VERSION "2021.24.4"

NS_ :

BS_:

BU_: VEH CH Receiver X

BA_DEF_ BO_ "GenMsgSendType" ENUM "Cyclic";
BA_DEF_ BO_ "GenMsgCycleTime" INT 0 10000;

BA_ "GenMsgSendType" BO_ 1879 0;
BA_ "GenMsgCycleTime" BO_ 1879 100;

BA_ "GenMsgSendType" BO_ 1680 0;
BA_ "GenMsgCycleTime" BO_ 1680 100;

BO_ 1666 HVP_hvpFaults: 8 Vector__XXX
 SG_ HVP_hvpFaultsChecksum : 56|8@1+ (1,0) [0|0] "" Vector__XXX
 SG_ HVP_hvpFaultsCounter : 52|4@1+ (1,0) [0|0] "" Vector__XXX
 SG_ HVP_shuntOverTemperature : 51|1@1+ (1,0) [0|0] "" Vector__XXX
 SG_ HVP_bmbBmbDataIntegrityLossFault : 49|1@1+ (1,0) [0|0] "" Vector__XXX
 SG_ HVP_bmbCommunicationFault : 48|1@1+ (1,0) [0|0] "" Vector__XXX
 SG_ HVP_configMinorVersion : 40|8@1+ (1,0) [0|0] "" Vector__XXX
 SG_ HVP_configMajorVersion : 32|8@1+ (1,0) [0|0] "" Vector__XXX
 SG_ HVP_hvilStatus : 30|2@1+ (1,0) [0|0] "" Vector__XXX
 SG_ HVP_hvilFault : 26|1@1+ (1,0) [0|0] "" Vector__XXX
 SG_ HVP_unsupportedBmbAsicType : 25|1@1+ (1,0) [0|0] "" Vector__XXX
 SG_ HVP_missingPartNumber : 24|1@1+ (1,0) [0|0] "" Vector__XXX
 SG_ HVP_missingConfigBlock : 23|1@1+ (1,0) [0|0] "" Vector__XXX
 SG_ HVP_fastVshFailureFault : 22|1@1+ (1,0) [0|0] "" Vector__XXX
 SG_ HVP_gpoRequestActive : 21|1@1+ (1,0) [0|0] "" Vector__XXX
 SG_ HVP_battery12vDisconnected : 20|1@1+ (1,0) [0|0] "" Vector__XXX
 SG_ HVP_packNegativeCtrArcFault : 19|1@1+ (1,0) [0|0] "" Vector__XXX
 SG_ HVP_packPositiveCtrArcFault : 18|1@1+ (1,0) [0|0] "" Vector__XXX
 SG_ HVP_ensMiaFault : 17|1@1+ (1,0) [0|0] "" Vector__XXX
 SG_ HVP_crashEvent : 16|1@1+ (1,0) [0|0] "" Vector__XXX
 SG_ HVP_packVoltageMismatchFault : 15|1@1+ (1,0) [0|0] "" Vector__XXX
 SG_ HVP_supply12vFault : 14|1@1+ (1,0) [0|0] "" Vector__XXX
 SG_ HVP_fcContactorHwFault : 13|1@1+ (1,0) [0|0] "" Vector__XXX
 SG_ HVP_packContactorHwFault : 12|1@1+ (1,0) [0|0] "" Vector__XXX
 SG_ HVP_pyroMiaWarning : 11|1@1+ (1,0) [0|0] "" Vector__XXX
 SG_ HVP_pyroMiaFault : 10|1@1+ (1,0) [0|0] "" Vector__XXX
 SG_ HVP_shuntHwAndBmsMiaFault : 9|1@1+ (1,0) [0|0] "" Vector__XXX
 SG_ HVP_shuntHwMiaFault : 8|1@1+ (1,0) [0|0] "" Vector__XXX
 SG_ HVP_cpFault : 7|1@1+ (1,0) [0|0] "" Vector__XXX
 SG_ HVP_pcsMiaFault : 6|1@1+ (1,0) [0|0] "" Vector__XXX
 SG_ HVP_cpMiaFault : 5|1@1+ (1,0) [0|0] "" Vector__XXX
 SG_ HVP_bmsMiaFault : 4|1@1+ (1,0) [0|0] "" Vector__XXX
 SG_ HVP_primaryBmbMiaFault : 3|1@1+ (1,0) [0|0] "" Vector__XXX
 SG_ HVP_underVoltageFault : 2|1@1+ (1,0) [0|0] "" Vector__XXX
 SG_ HVP_overVoltageFault : 1|1@1+ (1,0) [0|0] "" Vector__XXX
 SG_ HVP_overTemperatureFault : 0|1@1+ (1,0) [0|0] "" Vector__XXX

BO_ 1668 UDS_gtwRequest: 12 Vector__XXX
 SG_ UDS_gtwRequestData : 7|64@0+ (1,0) [0|0] "" Vector__XXX

BO_ 1669 GTW_udsResponse: 12 Vector__XXX
 SG_ GTW_udsResponseData : 7|64@0+ (1,0) [0|0] "" Vector__XXX

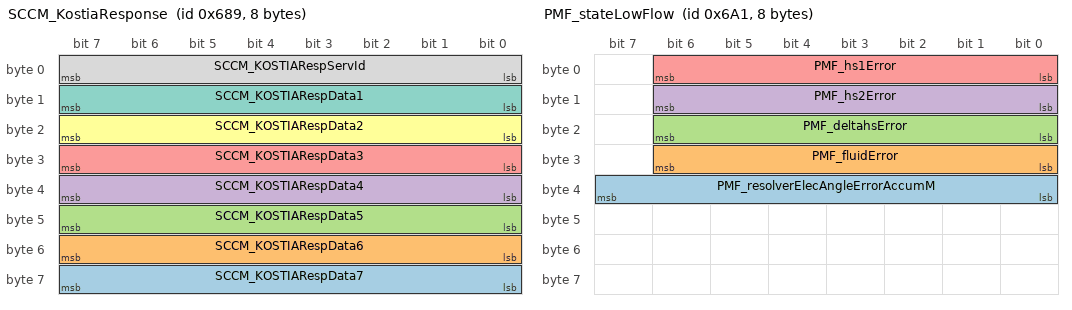
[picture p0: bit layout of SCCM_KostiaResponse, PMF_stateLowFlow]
BO_ 1673 SCCM_KostiaResponse: 8 Vector__XXX
 SG_ SCCM_KOSTIARespData7 : 56|8@1+ (1,0) [0|0] "" Vector__XXX
 SG_ SCCM_KOSTIARespData6 : 48|8@1+ (1,0) [0|0] "" Vector__XXX
 SG_ SCCM_KOSTIARespData5 : 40|8@1+ (1,0) [0|0] "" Vector__XXX
 SG_ SCCM_KOSTIARespData4 : 32|8@1+ (1,0) [0|0] "" Vector__XXX
 SG_ SCCM_KOSTIARespData3 : 24|8@1+ (1,0) [0|0] "" Vector__XXX
 SG_ SCCM_KOSTIARespData2 : 16|8@1+ (1,0) [0|0] "" Vector__XXX
 SG_ SCCM_KOSTIARespData1 : 8|8@1+ (1,0) [0|0] "" Vector__XXX
 SG_ SCCM_KOSTIARespServId : 0|8@1+ (1,0) [0|0] "" Vector__XXX

BO_ 1680 SCCM_udsResponse: 12 Vector__XXX
 SG_ SCCM_functionalResponseData_7 : 63|8@0+ (1,0) [0|0] "" Vector__XXX
 SG_ SCCM_functionalResponseData_6 : 55|8@0+ (1,0) [0|0] "" Vector__XXX
 SG_ SCCM_functionalResponseData_5 : 47|8@0+ (1,0) [0|0] "" Vector__XXX
 SG_ SCCM_functionalResponseData_4 : 39|8@0+ (1,0) [0|0] "" Vector__XXX
 SG_ SCCM_functionalResponseData_3 : 31|8@0+ (1,0) [0|0] "" Vector__XXX
 SG_ SCCM_functionalResponseData_2 : 23|8@0+ (1,0) [0|0] "" Vector__XXX
 SG_ SCCM_functionalResponseData_1 : 15|8@0+ (1,0) [0|0] "" Vector__XXX
 SG_ SCCM_functionalResponseData_0 : 7|8@0+ (1,0) [0|0] "" Vector__XXX

BO_ 1697 PMF_stateLowFlow: 8 Vector__XXX
 SG_ PMF_resolverElecAngleErrorAccumM : 32|8@1+ (0.00196078431372549,0) [0|0] "" Vector__XXX
 SG_ PMF_fluidError : 24|7@1+ (0.01,0) [0|0] "" Vector__XXX
 SG_ PMF_deltahsError : 16|7@1+ (0.01,0) [0|0] "" Vector__XXX
 SG_ PMF_hs2Error : 8|7@1+ (0.01,0) [0|0] "" Vector__XXX
 SG_ PMF_hs1Error : 0|7@1+ (0.01,0) [0|0] "" Vector__XXX

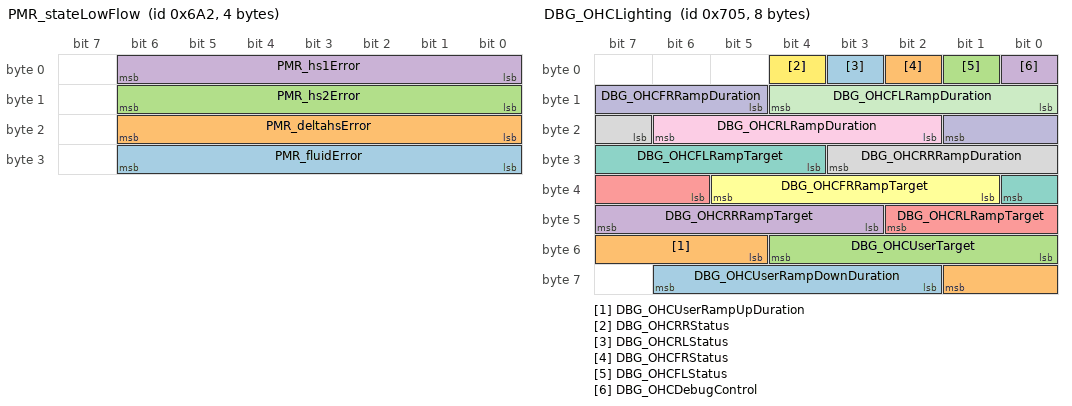
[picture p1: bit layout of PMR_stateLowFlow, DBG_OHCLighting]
BO_ 1698 PMR_stateLowFlow: 4 Vector__XXX
 SG_ PMR_fluidError : 24|7@1+ (0.01,0) [0|0] "" Vector__XXX
 SG_ PMR_deltahsError : 16|7@1+ (0.01,0) [0|0] "" Vector__XXX
 SG_ PMR_hs2Error : 8|7@1+ (0.01,0) [0|0] "" Vector__XXX
 SG_ PMR_hs1Error : 0|7@1+ (0.01,0) [0|0] "" Vector__XXX

BO_ 1723 UDS_sdcrRequest: 8 Vector__XXX
 SG_ UDS_sdcrRequestData : 7|64@0+ (1,0) [0|0] "" Vector__XXX

BO_ 1734 UDS_ptcRequest: 12 Vector__XXX
 SG_ UDS_ptcRequestData : 7|64@0+ (1,0) [0|0] "" Vector__XXX

BO_ 1736 EPBL_statsOutput: 8 Vector__XXX
 SG_ EPBL_staticApplyCountsVeryCold m0 : 44|20@1+ (1,0) [0|0] "" Vector__XXX
 SG_ EPBL_staticApplyCountsCold m0 : 24|20@1+ (1,0) [0|0] "" Vector__XXX
 SG_ EPBL_dynamicApplyCounts m1 : 8|32@1+ (1,0) [0|0] "" Vector__XXX
 SG_ EPBL_staticApplyCounts m0 : 2|20@1+ (1,0) [0|0] "" Vector__XXX
 SG_ EPBL_statsOutputIndex M : 0|2@1+ (1,0) [0|0] "" Vector__XXX

BO_ 1750 PTC_udsResponse: 12 Vector__XXX
 SG_ PTC_udsResponseData : 7|64@0+ (1,0) [0|0] "" Vector__XXX

BO_ 1766 PNCD_IsoTpPipeToCp: 8 Vector__XXX
 SG_ PNCD_isoTpToCpData : 0|64@1+ (1,0) [0|0] "" Vector__XXX

BO_ 1767 CP_IsoTpPipeToPncd: 8 Vector__XXX
 SG_ CP_isoTpToPncdData : 0|64@1+ (1,0) [0|0] "" Vector__XXX

BO_ 1768 EPBR_statsOutput: 8 Vector__XXX
 SG_ EPBR_staticApplyCountsVeryCold m0 : 44|20@1+ (1,0) [0|0] "" Vector__XXX
 SG_ EPBR_staticApplyCountsCold m0 : 24|20@1+ (1,0) [0|0] "" Vector__XXX
 SG_ EPBR_dynamicApplyCounts m1 : 8|32@1+ (1,0) [0|0] "" Vector__XXX
 SG_ EPBR_staticApplyCounts m0 : 2|20@1+ (1,0) [0|0] "" Vector__XXX
 SG_ EPBR_statsOutputIndex M : 0|2@1+ (1,0) [0|0] "" Vector__XXX

BO_ 1776 UNK_6F0_alive: 2 Vector__XXX
 SG_ UNK_6F0_crc : 0|8@1+ (1,0) [0|255] "" Vector__XXX
 SG_ UNK_6F0_counter : 8|4@1+ (1,0) [0|15] "" Vector__XXX

BO_ 1779 UNK_6F3_alive: 3 Vector__XXX
 SG_ UNK_6F3_crc : 0|8@1+ (1,0) [0|255] "" Vector__XXX
 SG_ UNK_6F3_counter : 8|4@1+ (1,0) [0|15] "" Vector__XXX

BO_ 1787 SDCR_udsResponse: 12 Vector__XXX
 SG_ SDCR_udsResponseData : 7|64@0+ (1,0) [0|0] "" Vector__XXX

BO_ 1793 VCFRONT_debugThermal10Hz: 8 Vector__XXX
 SG_ VCFRONT_ccRightExvCount m6 : 54|10@1- (4,0) [0|0] "" Vector__XXX
 SG_ VCFRONT_ccLeftExvCount m6 : 44|10@1- (4,0) [0|0] "" Vector__XXX
 SG_ VCFRONT_activeLouverAutoDetCur3 m3 : 40|7@1+ (5,0) [0|0] "" Vector__XXX
 SG_ VCFRONT_coolantNoFlowFaultPT m2 : 40|1@1+ (1,0) [0|0] "" Vector__XXX
 SG_ VCFRONT_coolantNoFlowReqPT m2 : 39|1@1+ (1,0) [0|0] "" Vector__XXX
 SG_ VCFRONT_lccExvCount m6 : 34|10@1- (4,0) [0|0] "" Vector__XXX
 SG_ VCFRONT_activeLouverAutoDetCur2 m3 : 32|7@1+ (5,0) [0|0] "" Vector__XXX
 SG_ VCFRONT_activeLouverMotorCurrent m5 : 32|10@1- (5,0) [0|0] "" Vector__XXX
 SG_ VCFRONT_coolantFlowPTMax m2 : 30|9@1+ (0.1,0) [0|0] "" Vector__XXX
 SG_ VCFRONT_coolantNoFlowFaultBat m2 : 29|1@1+ (1,0) [0|0] "" Vector__XXX
 SG_ VCFRONT_coolantNoFlowReqBat m2 : 28|1@1+ (1,0) [0|0] "" Vector__XXX
 SG_ VCFRONT_activeLouverAutoDetCur1 m3 : 25|7@1+ (5,0) [0|0] "" Vector__XXX
 SG_ VCFRONT_pumpBatteryFault m0 : 24|1@1+ (1,0) [0|0] "" Vector__XXX
 SG_ VCFRONT_pumpPowertrainFault m1 : 24|1@1+ (1,0) [0|0] "" Vector__XXX
 SG_ VCFRONT_radiatorFanFault m3 : 24|1@1+ (1,0) [0|0] "" Vector__XXX
 SG_ VCFRONT_recircExvCount m6 : 24|10@1- (4,0) [0|0] "" Vector__XXX
 SG_ VCFRONT_solenoidEvapPowerApplied m4 : 20|1@1+ (1,0) [0|0] "" Vector__XXX
 SG_ VCFRONT_coolantFlowBatMax m2 : 19|9@1+ (0.1,0) [0|0] "" Vector__XXX
 SG_ VCFRONT_exvMotorHasCommError m4 : 19|1@1+ (1,0) [0|0] "" Vector__XXX
 SG_ VCFRONT_coolantValveStall m2 : 18|1@1+ (1,0) [0|0] "" Vector__XXX
 SG_ VCFRONT_exvMotorIsCoilShortYNVbb m4 : 18|1@1+ (1,0) [0|0] "" Vector__XXX
 SG_ VCFRONT_coolantValveNoTravel m2 : 17|1@1+ (1,0) [0|0] "" Vector__XXX
 SG_ VCFRONT_exvMotorIsCoilShortYNGnd m4 : 17|1@1+ (1,0) [0|0] "" Vector__XXX
 SG_ VCFRONT_activeLouverMotorSpeed m5 : 16|16@1+ (0.1,0.1) [0|0] "" Vector__XXX
 SG_ VCFRONT_coolantValveOverTravel m2 : 16|1@1+ (1,0) [0|0] "" Vector__XXX
 SG_ VCFRONT_exvMotorIsCoilShortYPVbb m4 : 16|1@1+ (1,0) [0|0] "" Vector__XXX
 SG_ VCFRONT_pumpBatteryITerm m0 : 16|8@1+ (0.005,-0.6) [0|0] "" Vector__XXX
 SG_ VCFRONT_pumpPowertrainITerm m1 : 16|8@1+ (0.005,-0.6) [0|0] "" Vector__XXX
 SG_ VCFRONT_radiatorFanITerm m3 : 16|8@1+ (0.025,-1.5) [0|0] "" Vector__XXX
 SG_ VCFRONT_coolantValveUnderTravel m2 : 15|1@1+ (1,0) [0|0] "" Vector__XXX
 SG_ VCFRONT_exvMotorIsCoilShortYPGnd m4 : 15|1@1+ (1,0) [0|0] "" Vector__XXX
 SG_ VCFRONT_exvMotorIsCoilShortXNVbb m4 : 14|1@1+ (1,0) [0|0] "" Vector__XXX
 SG_ VCFRONT_evapExvCount m6 : 13|10@1- (4,0) [0|0] "" Vector__XXX
 SG_ VCFRONT_exvMotorIsCoilShortXNGnd m4 : 13|1@1+ (1,0) [0|0] "" Vector__XXX
 SG_ VCFRONT_exvMotorIsCoilShortXPVbb m4 : 12|1@1+ (1,0) [0|0] "" Vector__XXX
 SG_ VCFRONT_exvMotorIsCoilShortXPGnd m4 : 11|1@1+ (1,0) [0|0] "" Vector__XXX
 SG_ VCFRONT_exvMotorIsCoilOpenY m4 : 10|1@1+ (1,0) [0|0] "" Vector__XXX
 SG_ VCFRONT_exvMotorIsCoilOpenX m4 : 9|1@1+ (1,0) [0|0] "" Vector__XXX
 SG_ VCFRONT_exvMotorThermalShutdown m4 : 8|1@1+ (1,0) [0|0] "" Vector__XXX
 SG_ VCFRONT_pumpBatteryOutputDuty m0 : 8|7@1+ (1,0) [0|0] "" Vector__XXX
 SG_ VCFRONT_pumpPowertrainOutputDuty m1 : 8|7@1+ (1,0) [0|0] "" Vector__XXX
 SG_ VCFRONT_radiatorFanOutputDuty m3 : 8|7@1+ (1,0) [0|0] "" Vector__XXX
 SG_ VCFRONT_exvMotorThermalWarn m4 : 7|1@1+ (1,0) [0|0] "" Vector__XXX
 SG_ VCFRONT_exvMotorWasHardReset m4 : 6|1@1+ (1,0) [0|0] "" Vector__XXX
 SG_ VCFRONT_exvMotorDirection m4 : 5|1@1+ (1,0) [0|0] "" Vector__XXX
 SG_ VCFRONT_coolantValveMotorCounts m2 : 4|11@1+ (1,-1000) [0|0] "" Vector__XXX
 SG_ VCFRONT_exvMotorIsMoving m4 : 4|1@1+ (1,0) [0|0] "" Vector__XXX
 SG_ VCFRONT_activeLouverMotorKt m5 : 3|10@1+ (0.5,0) [0|0] "" Vector__XXX
 SG_ VCFRONT_chillerExvCount m6 : 3|10@1- (4,0) [0|0] "" Vector__XXX
 SG_ VCFRONT_coolantValveAtTarget m2 : 3|1@1+ (1,0) [0|0] "" Vector__XXX
 SG_ VCFRONT_exvMotorIsEnabled m4 : 3|1@1+ (1,0) [0|0] "" Vector__XXX
 SG_ VCFRONT_debugThermal10HzIndex M : 0|3@1+ (1,0) [0|0] "" Vector__XXX

BO_ 1796 XCP_pmrRequest: 12 Vector__XXX
 SG_ XCP_pmrRequestData : 7|64@0+ (1,0) [0|0] "" Vector__XXX

BO_ 1797 DBG_OHCLighting: 8 Vector__XXX
 SG_ DBG_OHCUserRampDownDuration : 58|5@1+ (0.25,0.25) [0|0] "" Vector__XXX
 SG_ DBG_OHCUserRampUpDuration : 53|5@1+ (0.25,0.25) [0|0] "" Vector__XXX
 SG_ DBG_OHCUserTarget : 48|5@1+ (5,0) [0|0] "" Vector__XXX
 SG_ DBG_OHCRRRampTarget : 43|5@1+ (5,0) [0|0] "" Vector__XXX
 SG_ DBG_OHCRLRampTarget : 38|5@1+ (5,0) [0|0] "" Vector__XXX
 SG_ DBG_OHCFRRampTarget : 33|5@1+ (5,0) [0|0] "" Vector__XXX
 SG_ DBG_OHCFLRampTarget : 28|5@1+ (5,0) [0|0] "" Vector__XXX
 SG_ DBG_OHCRRRampDuration : 23|5@1+ (0.25,0.25) [0|0] "" Vector__XXX
 SG_ DBG_OHCRLRampDuration : 18|5@1+ (0.25,0.25) [0|0] "" Vector__XXX
 SG_ DBG_OHCFRRampDuration : 13|5@1+ (0.25,0.25) [0|0] "" Vector__XXX
 SG_ DBG_OHCFLRampDuration : 8|5@1+ (0.25,0.25) [0|0] "" Vector__XXX
 SG_ DBG_OHCRRStatus : 4|1@1+ (1,0) [0|0] "" Vector__XXX
 SG_ DBG_OHCRLStatus : 3|1@1+ (1,0) [0|0] "" Vector__XXX
 SG_ DBG_OHCFRStatus : 2|1@1+ (1,0) [0|0] "" Vector__XXX
 SG_ DBG_OHCFLStatus : 1|1@1+ (1,0) [0|0] "" Vector__XXX
 SG_ DBG_OHCDebugControl : 0|1@1+ (1,0) [0|0] "" Vector__XXX

BO_ 1798 XCP_dirRequest: 12 Vector__XXX
 SG_ XCP_dirRequestData : 7|64@0+ (1,0) [0|0] "" Vector__XXX

BO_ 1799 DBG_intrusionSensor: 8 Vector__XXX
 SG_ DBG_IS_Reserved_06 : 23|1@1+ (1,0) [0|0] "" Vector__XXX
 SG_ DBG_IS_Siren_Alarm_Cycles : 22|1@1+ (1,0) [0|0] "" Vector__XXX
 SG_ DBG_IS_Siren_Tone : 21|1@1+ (1,0) [0|0] "" Vector__XXX
 SG_ DBG_IS_Siren_Beep_Duration : 19|2@1+ (1,0) [0|0] "" Vector__XXX
 SG_ DBG_IS_Siren_Beep_Type : 17|2@1+ (1,0) [0|0] "" Vector__XXX
 SG_ DBG_IS_Siren_Alarm : 16|1@1+ (1,0) [0|0] "" Vector__XXX
 SG_ DBG_IS_Reserved_05 : 15|1@1+ (1,0) [0|0] "" Vector__XXX
 SG_ DBG_IS_Reserved_04 : 14|1@1+ (1,0) [0|0] "" Vector__XXX
 SG_ DBG_IS_Reserved_03 : 13|1@1+ (1,0) [0|0] "" Vector__XXX
 SG_ DBG_IS_Reserved_02 : 12|1@1+ (1,0) [0|0] "" Vector__XXX
 SG_ DBG_IS_Vehicles_Settings : 8|4@1+ (1,0) [0|0] "" Vector__XXX
 SG_ DBG_IS_Suspensions : 7|1@1+ (1,0) [0|0] "" Vector__XXX
 SG_ DBG_IS_Reserved_01 : 6|1@1+ (1,0) [0|0] "" Vector__XXX
 SG_ DBG_IS_Window : 5|1@1+ (1,0) [0|0] "" Vector__XXX
 SG_ DBG_IS_Heater : 4|1@1+ (1,0) [0|0] "" Vector__XXX
 SG_ DBG_IS_Air_Conditioned : 3|1@1+ (1,0) [0|0] "" Vector__XXX
 SG_ DBG_IS_USS_Operation : 0|3@1+ (1,0) [0|0] "" Vector__XXX

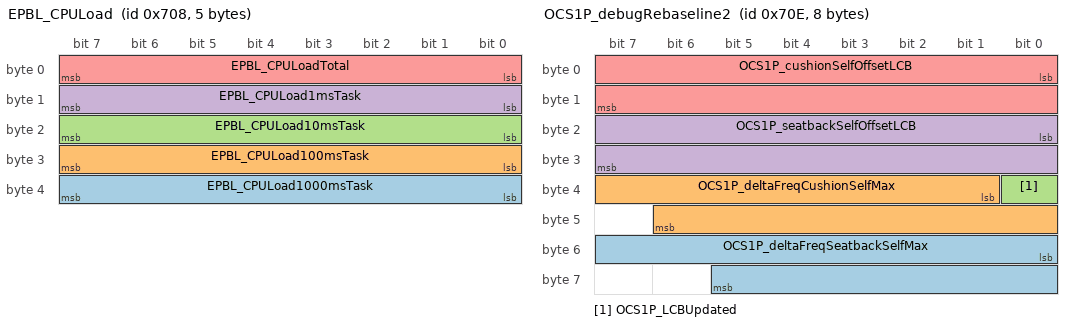
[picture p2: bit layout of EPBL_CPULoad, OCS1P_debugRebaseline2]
BO_ 1800 EPBL_CPULoad: 5 Vector__XXX
 SG_ EPBL_CPULoad1000msTask : 32|8@1+ (1,0) [0|0] "" Vector__XXX
 SG_ EPBL_CPULoad100msTask : 24|8@1+ (1,0) [0|0] "" Vector__XXX
 SG_ EPBL_CPULoad10msTask : 16|8@1+ (1,0) [0|0] "" Vector__XXX
 SG_ EPBL_CPULoad1msTask : 8|8@1+ (1,0) [0|0] "" Vector__XXX
 SG_ EPBL_CPULoadTotal : 0|8@1+ (1,0) [0|0] "" Vector__XXX

BO_ 1801 VCFRONT_logging0point1Hz: 8 Vector__XXX
 SG_ VCFRONT_sideMarkerLightCurrentSe m0 : 60|3@1+ (1,0) [0|0] "" Vector__XXX
 SG_ VCFRONT_airInRefrigerantFailureC m24 : 57|7@1+ (1,0) [0|0] "" Vector__XXX
 SG_ VCFRONT_evapExvFailureConfidence m23 : 57|7@1+ (1,0) [0|0] "" Vector__XXX
 SG_ VCFRONT_battHeatingPowerActual m2 : 56|7@1+ (100,0) [0|0] "" Vector__XXX
 SG_ VCFRONT_solverIterMaxAllModels m17 : 56|6@1+ (2,0) [0|0] "" Vector__XXX
 SG_ VCFRONT_solverIterMaxFeedforward m19 : 56|6@1+ (2,0) [0|0] "" Vector__XXX
 SG_ VCFRONT_solverIterMaxTotalLoad m18 : 56|6@1+ (2,0) [0|0] "" Vector__XXX
 SG_ VCFRONT_tempRefrigDischargeColdS m5 : 56|6@1+ (1,-40) [0|0] "" Vector__XXX
 SG_ VC_rightHeadlampAimingState m3 : 56|3@1+ (1,0) [0|0] "" Vector__XXX
 SG_ VC_rightHeadlampECUTemperature m1 : 56|8@1- (1,60) [0|0] "" Vector__XXX
 SG_ VC_hcmlCurrentBin3Value m26 : 52|3@1+ (1,0) [0|0] "" Vector__XXX
 SG_ VC_hcmrCurrentBin3Value m27 : 52|3@1+ (1,0) [0|0] "" Vector__XXX
 SG_ VCFRONT_sideMarkerLightCurrent m0 : 51|9@1+ (0.002,0) [0|0] "" Vector__XXX
 SG_ VC_leftHeadlampAimingState m3 : 51|3@1+ (1,0) [0|0] "" Vector__XXX
 SG_ VCFRONT_chillerExvFailureConfide m23 : 50|7@1+ (1,0) [0|0] "" Vector__XXX
 SG_ VCFRONT_maxAmbientSourceCapacity m24 : 50|7@1+ (100,0) [0|0] "" Vector__XXX
 SG_ VC_hcmlCurrentBin2Value m26 : 49|3@1+ (1,0) [0|0] "" Vector__XXX
 SG_ VC_hcmrCurrentBin2Value m27 : 49|3@1+ (1,0) [0|0] "" Vector__XXX
 SG_ VCFRONT_compLiquidDetectionTime m2 : 48|7@1+ (5,0) [0|0] "" Vector__XXX
 SG_ VCFRONT_headlampRegionAndTraffic m3 : 48|3@1+ (1,0) [0|0] "" Vector__XXX
 SG_ VCFRONT_leftSideRepeaterLig_0000 m0 : 48|3@1+ (1,0) [0|0] "" Vector__XXX
 SG_ VCFRONT_rightHeadlampBoostTemper m22 : 48|3@1+ (1,0) [0|0] "" Vector__XXX
 SG_ VCFRONT_rightHeadlampCommFaultCo m21 : 48|8@1+ (1,0) [0|0] "" Vector__XXX
 SG_ VCFRONT_solverIterAvgAllModels m17 : 48|6@1+ (2,0) [0|0] "" Vector__XXX
 SG_ VCFRONT_solverIterAvgFeedforward m19 : 48|6@1+ (2,0) [0|0] "" Vector__XXX
 SG_ VCFRONT_solverIterAvgTotalLoad m18 : 48|6@1+ (2,0) [0|0] "" Vector__XXX
 SG_ VC_leftHeadlampECUTemperature m1 : 48|8@1- (1,60) [0|0] "" Vector__XXX
 SG_ VCFRONT_calibratedPitchEstimate m4 : 46|10@1- (0.0002,0) [0|0] "" Vector__XXX
 SG_ VC_hcmlCurrentBin1Value m26 : 46|3@1+ (1,0) [0|0] "" Vector__XXX
 SG_ VC_hcmrCurrentBin1Value m27 : 46|3@1+ (1,0) [0|0] "" Vector__XXX
 SG_ VCFRONT_TlFailureConfidence m23 : 43|7@1+ (1,0) [0|0] "" Vector__XXX
 SG_ VCFRONT_leftHeadlampBoostTempera m22 : 43|3@1+ (1,0) [0|0] "" Vector__XXX
 SG_ VCFRONT_sovFailureConfidence m24 : 43|7@1+ (1,0) [0|0] "" Vector__XXX
 SG_ VC_hcmlCurrentBin0Value m26 : 43|3@1+ (1,0) [0|0] "" Vector__XXX
 SG_ VC_hcmrCurrentBin0Value m27 : 43|3@1+ (1,0) [0|0] "" Vector__XXX
 SG_ VC_rightHeadlampPositionSubState m20 : 43|4@1+ (1,0) [0|0] "" Vector__XXX
 SG_ VCFRONT_compRotationCount m28 : 41|18@1+ (10000,0) [0|0] "" Vector__XXX
 SG_ VCFRONT_leftSideRepeaterLightCur m0 : 41|7@1+ (0.002,0) [0|0] "" Vector__XXX
 SG_ VC_hcmlCurrentBinMappingType m26 : 41|2@1+ (1,0) [0|0] "" Vector__XXX
 SG_ VC_hcmrCurrentBinMappingType m27 : 41|2@1+ (1,0) [0|0] "" Vector__XXX
 SG_ VCFRONT_HCML_diffuseTemp m1 : 40|8@1- (1,67) [0|0] "" Vector__XXX
 SG_ VCFRONT_HCMR_diffuseTemp m2 : 40|8@1- (1,67) [0|0] "" Vector__XXX
 SG_ VCFRONT_rightHeadlampCrcFaultCou m21 : 40|8@1+ (1,0) [0|0] "" Vector__XXX
 SG_ VCFRONT_rightHeadlampLBWideDebou m22 : 40|3@1+ (1,0) [0|0] "" Vector__XXX
 SG_ VC_rightHeadlampPositionState m20 : 40|3@1+ (1,0) [0|0] "" Vector__XXX
 SG_ VCFRONT_leftFrontFogLightCu_0000 m0 : 38|3@1+ (1,0) [0|0] "" Vector__XXX
 SG_ VCFRONT_cclEXVCountOpenOvDrv m13 : 37|17@1+ (80,0) [0|0] "" Vector__XXX
 SG_ VCFRONT_ccrEXVCountOpenOvDrv m15 : 37|17@1+ (80,0) [0|0] "" Vector__XXX
 SG_ VCFRONT_chillerEXVCountOpenOvDrv m5 : 37|17@1+ (80,0) [0|0] "" Vector__XXX
 SG_ VCFRONT_evapEXVCountOpenOvDrv m7 : 37|17@1+ (80,0) [0|0] "" Vector__XXX
 SG_ VCFRONT_lccEXVCountOpenOvDrv m11 : 37|17@1+ (80,0) [0|0] "" Vector__XXX
 SG_ VCFRONT_recircEXVCountOpenOvDrv m9 : 37|17@1+ (80,0) [0|0] "" Vector__XXX
 SG_ VCFRONT_TsFailureConfidence m23 : 36|7@1+ (1,0) [0|0] "" Vector__XXX
 SG_ VCFRONT_lccExvFailureConfidence m24 : 36|7@1+ (1,0) [0|0] "" Vector__XXX
 SG_ VC_rightHeadlampAimedHorizontalP m4 : 36|10@1+ (1,0) [0|0] "" Vector__XXX
 SG_ VC_rightHeadlampCurrentHorizonta m3 : 36|10@1+ (1,0) [0|0] "" Vector__XXX
 SG_ VCFRONT_rightHeadlampLBWideInsta m22 : 35|4@1+ (1,0) [0|0] "" Vector__XXX
 SG_ VC_leftHeadlampPositionSubState m20 : 35|4@1+ (1,0) [0|0] "" Vector__XXX
 SG_ VCFRONT_HCML_bladeTemp m1 : 32|8@1- (1,67) [0|0] "" Vector__XXX
 SG_ VCFRONT_HCMR_bladeTemp m2 : 32|8@1- (1,67) [0|0] "" Vector__XXX
 SG_ VCFRONT_coolantValveOdometer m25 : 32|13@1+ (2000,0) [0|0] "" Vector__XXX
 SG_ VCFRONT_rightHeadlampLBSpotDebou m22 : 32|3@1+ (1,0) [0|0] "" Vector__XXX
 SG_ VCFRONT_rightHeadlampPowerBitRes m21 : 32|8@1+ (1,0) [0|0] "" Vector__XXX
 SG_ VC_leftHeadlampPositionState m20 : 32|3@1+ (1,0) [0|0] "" Vector__XXX
 SG_ VCFRONT_TdFailureConfidence m23 : 29|7@1+ (1,0) [0|0] "" Vector__XXX
 SG_ VCFRONT_ccrExvFailureConfidence m24 : 29|7@1+ (1,0) [0|0] "" Vector__XXX
 SG_ VCFRONT_leftFrontFogLightCurrent m0 : 29|9@1+ (0.002,0) [0|0] "" Vector__XXX
 SG_ VCFRONT_ccrEXVCountTotalDist m19 : 28|20@1+ (15000,0) [0|0] "" Vector__XXX
 SG_ VCFRONT_evapEXVCountTotalDist m17 : 28|20@1+ (15000,0) [0|0] "" Vector__XXX
 SG_ VCFRONT_lccEXVCountTotalDist m18 : 28|20@1+ (15000,0) [0|0] "" Vector__XXX
 SG_ VCFRONT_ccrEXVType m25 : 27|3@1+ (1,0) [0|0] "" Vector__XXX
 SG_ VCFRONT_rightHeadlampLBSpotInsta m22 : 27|4@1+ (1,0) [0|0] "" Vector__XXX
 SG_ VCFRONT_rightSideRepeaterLi_0000 m0 : 26|3@1+ (1,0) [0|0] "" Vector__XXX
 SG_ VC_leftHeadlampAimedHorizontalPo m4 : 26|10@1+ (1,0) [0|0] "" Vector__XXX
 SG_ VC_rightHeadlampCurrentVerticalP m3 : 26|10@1+ (1,0) [0|0] "" Vector__XXX
 SG_ VCFRONT_HCML_turnTemp m1 : 24|8@1- (1,67) [0|0] "" Vector__XXX
 SG_ VCFRONT_HCMR_turnTemp m2 : 24|8@1- (1,67) [0|0] "" Vector__XXX
 SG_ VCFRONT_activeLouverType m6 : 24|2@1+ (1,0) [0|0] "" Vector__XXX
 SG_ VCFRONT_cclEXVCountDirecChan m13 : 24|13@1+ (2000,0) [0|0] "" Vector__XXX
 SG_ VCFRONT_cclEXVType m25 : 24|3@1+ (1,0) [0|0] "" Vector__XXX
 SG_ VCFRONT_ccrEXVCountDirecChan m15 : 24|13@1+ (2000,0) [0|0] "" Vector__XXX
 SG_ VCFRONT_chillerEXVCountDirecChan m5 : 24|13@1+ (2000,0) [0|0] "" Vector__XXX
 SG_ VCFRONT_compHoursOn m28 : 24|17@1+ (1,0) [0|0] "" Vector__XXX
 SG_ VCFRONT_evapEXVCountDirecChan m7 : 24|13@1+ (2000,0) [0|0] "" Vector__XXX
 SG_ VCFRONT_lccEXVCountDirecChan m11 : 24|13@1+ (2000,0) [0|0] "" Vector__XXX
 SG_ VCFRONT_leftHeadlampCommFaultCou m21 : 24|8@1+ (1,0) [0|0] "" Vector__XXX
 SG_ VCFRONT_leftHeadlampLBWideDeboun m22 : 24|3@1+ (1,0) [0|0] "" Vector__XXX
 SG_ VCFRONT_minutesSinceAccDeviceCon m12 : 24|16@1+ (1,0) [0|0] "" Vector__XXX
 SG_ VCFRONT_recircEXVCountDirecChan m9 : 24|13@1+ (2000,0) [0|0] "" Vector__XXX
 SG_ VCFRONT_PlFailureConfidence m23 : 22|7@1+ (1,0) [0|0] "" Vector__XXX
 SG_ VCFRONT_cclExvFailureConfidence m24 : 22|7@1+ (1,0) [0|0] "" Vector__XXX
 SG_ VC_rightHeadlampUsableRange m20 : 20|10@1+ (1,0) [0|0] "" Vector__XXX
 SG_ VCFRONT_lccEXVType m25 : 19|3@1+ (1,0) [0|0] "" Vector__XXX
 SG_ VCFRONT_leftHeadlampLBWideInstan m22 : 19|4@1+ (1,0) [0|0] "" Vector__XXX
 SG_ VCFRONT_rightSideRepeaterLightCu m0 : 19|7@1+ (0.002,0) [0|0] "" Vector__XXX
 SG_ VCFRONT_HCML_highBeamTemp m1 : 16|8@1- (1,67) [0|0] "" Vector__XXX
 SG_ VCFRONT_HCMR_highBeamTemp m2 : 16|8@1- (1,67) [0|0] "" Vector__XXX
 SG_ VCFRONT_leftHeadlampCrcFaultCoun m21 : 16|8@1+ (1,0) [0|0] "" Vector__XXX
 SG_ VCFRONT_leftHeadlampLBSpotDeboun m22 : 16|3@1+ (1,0) [0|0] "" Vector__XXX
 SG_ VCFRONT_recircEXVType m25 : 16|3@1+ (1,0) [0|0] "" Vector__XXX
 SG_ VCFRONT_rightFrontFogLightC_0000 m0 : 16|3@1+ (1,0) [0|0] "" Vector__XXX
 SG_ VC_leftHeadlampCurrentHorizontal m3 : 16|10@1+ (1,0) [0|0] "" Vector__XXX
 SG_ VC_rightHeadlampAimedVerticalPos m4 : 16|10@1+ (1,0) [0|0] "" Vector__XXX
 SG_ VCFRONT_PsFailureConfidence m23 : 15|7@1+ (1,0) [0|0] "" Vector__XXX
 SG_ VCFRONT_compressorFailureConfide m24 : 15|7@1+ (1,0) [0|0] "" Vector__XXX
 SG_ VCFRONT_leftHeadlampLBSpotInstan m22 : 12|4@1+ (1,0) [0|0] "" Vector__XXX
 SG_ VCFRONT_evapEXVType m25 : 11|3@1+ (1,0) [0|0] "" Vector__XXX
 SG_ VC_leftHeadlampUsableRange m20 : 10|10@1+ (1,0) [0|0] "" Vector__XXX
 SG_ VC_hcmlHellaPartNumber m26 : 9|32@1+ (1,0) [0|0] "" Vector__XXX
 SG_ VC_hcmrHellaPartNumber m27 : 9|32@1+ (1,0) [0|0] "" Vector__XXX
 SG_ VCFRONT_HCML_lowBeamSpotTemp m1 : 8|8@1- (1,67) [0|0] "" Vector__XXX
 SG_ VCFRONT_HCMR_lowBeamSpotTemp m2 : 8|8@1- (1,67) [0|0] "" Vector__XXX
 SG_ VCFRONT_PdFailureConfidence m23 : 8|7@1+ (1,0) [0|0] "" Vector__XXX
 SG_ VCFRONT_cclEXVCountClosOvDrv m14 : 8|15@1+ (500,0) [0|0] "" Vector__XXX
 SG_ VCFRONT_cclEXVCountFirstOpen m13 : 8|15@1+ (100,0) [0|0] "" Vector__XXX
 SG_ VCFRONT_cclEXVCountTotalDist m19 : 8|20@1+ (15000,0) [0|0] "" Vector__XXX
 SG_ VCFRONT_ccrEXVCountClosOvDrv m16 : 8|15@1+ (500,0) [0|0] "" Vector__XXX
 SG_ VCFRONT_ccrEXVCountFirstOpen m15 : 8|15@1+ (100,0) [0|0] "" Vector__XXX
 SG_ VCFRONT_chillerEXVCountClosOvDrv m6 : 8|15@1+ (500,0) [0|0] "" Vector__XXX
 SG_ VCFRONT_chillerEXVCountFirstOpen m5 : 8|15@1+ (100,0) [0|0] "" Vector__XXX
 SG_ VCFRONT_chillerEXVCountTotalDist m17 : 8|20@1+ (15000,0) [0|0] "" Vector__XXX
 SG_ VCFRONT_chillerEXVType m25 : 8|3@1+ (1,0) [0|0] "" Vector__XXX
 SG_ VCFRONT_compOnOffCycles m28 : 8|16@1+ (10,0) [0|0] "" Vector__XXX
 SG_ VCFRONT_evapEXVCountClosOvDrv m8 : 8|15@1+ (500,0) [0|0] "" Vector__XXX
 SG_ VCFRONT_evapEXVCountFirstOpen m7 : 8|15@1+ (100,0) [0|0] "" Vector__XXX
 SG_ VCFRONT_hazardLightRequestDebug m22 : 8|4@1+ (1,0) [0|0] "" Vector__XXX
 SG_ VCFRONT_lccEXVCountClosOvDrv m12 : 8|15@1+ (500,0) [0|0] "" Vector__XXX
 SG_ VCFRONT_lccEXVCountFirstOpen m11 : 8|15@1+ (100,0) [0|0] "" Vector__XXX
 SG_ VCFRONT_leftHeadlampPowerBitRese m21 : 8|8@1+ (1,0) [0|0] "" Vector__XXX
 SG_ VCFRONT_recircEXVCountClosOvDrv m10 : 8|15@1+ (500,0) [0|0] "" Vector__XXX
 SG_ VCFRONT_recircEXVCountFirstOpen m9 : 8|15@1+ (100,0) [0|0] "" Vector__XXX
 SG_ VCFRONT_recircEXVCountTotalDist m18 : 8|20@1+ (15000,0) [0|0] "" Vector__XXX
 SG_ VCFRONT_recircExvFailureConfiden m24 : 8|7@1+ (1,0) [0|0] "" Vector__XXX
 SG_ VC_hcmlHellaPartNumberStatus m26 : 8|1@1+ (1,0) [0|0] "" Vector__XXX
 SG_ VC_hcmrHellaPartNumberStatus m27 : 8|1@1+ (1,0) [0|0] "" Vector__XXX
 SG_ VC_rightHeadlampMigrationState m20 : 8|2@1+ (1,0) [0|0] "" Vector__XXX
 SG_ VCFRONT_rightFrontFogLightCurren m0 : 6|9@1+ (0.002,0) [0|0] "" Vector__XXX
 SG_ VC_hcmlFactoryOfOrigin m26 : 6|2@1+ (1,0) [0|0] "" Vector__XXX
 SG_ VC_hcmrFactoryOfOrigin m27 : 6|2@1+ (1,0) [0|0] "" Vector__XXX
 SG_ VC_leftHeadlampAimedVerticalPosi m4 : 6|10@1+ (1,0) [0|0] "" Vector__XXX
 SG_ VC_leftHeadlampCurrentVerticalPo m3 : 6|10@1+ (1,0) [0|0] "" Vector__XXX
 SG_ VC_leftHeadlampMigrationState m20 : 6|2@1+ (1,0) [0|0] "" Vector__XXX
 SG_ VCFRONT_logging0point1HzIndex M : 0|6@1+ (1,0) [0|0] "" Vector__XXX

BO_ 1802 VCLEFT_logging0point1Hz: 5 Vector__XXX
 SG_ VCLEFT_leftBrakeLightCurrentSenseState m0 : 37|3@1+ (1,0) [0|0] "" Vector__XXX
 SG_ VCLEFT_leftBrakeLightCurrent m0 : 28|9@1+ (0.005,0) [0|0] "" Vector__XXX
 SG_ VCLEFT_leftRearTurnLightCurrentSenseState m0 : 24|3@1+ (1,0) [0|0] "" Vector__XXX
 SG_ VCLEFT_leftRearTurnLightCurrent m0 : 14|9@1+ (0.002,0) [0|0] "" Vector__XXX
 SG_ VCLEFT_leftTailLightCurrentSenseState m0 : 11|3@1+ (1,0) [0|0] "" Vector__XXX
 SG_ VCLEFT_leftTailLightCurrent m0 : 2|9@1+ (0.002,0) [0|0] "" Vector__XXX
 SG_ VCLEFT_logging0point1HzIndex M : 0|1@1+ (1,0) [0|0] "" Vector__XXX

BO_ 1803 VCRIGHT_logging0point1Hz: 8 Vector__XXX
 SG_ VCRIGHT_exteriorNightLightCurrentSenseState m0 : 61|3@1+ (1,0) [0|0] "" Vector__XXX
 SG_ VCRIGHT_leftTrunkLightCurrentSenseState m1 : 61|3@1+ (1,0) [0|0] "" Vector__XXX
 SG_ VCRIGHT_cabinTempBreathLevelF5minCooling m8 : 56|8@1+ (0.5,-40) [0|0] "" Vector__XXX
 SG_ VCRIGHT_hvacIntakeEndStop m3 : 56|8@1+ (0.02,0) [0|0] "" Vector__XXX
 SG_ VCRIGHT_hvacIntakeZeroStop m4 : 56|8@1+ (0.02,0) [0|0] "" Vector__XXX
 SG_ VCRIGHT_interiorCameraLedCurrent m6 : 56|8@1+ (8,0) [0|0] "" Vector__XXX
 SG_ VCRIGHT_airDistributionModeAdjustmentFactor m2 : 55|9@1+ (0.001,1) [0|0] "" Vector__XXX
 SG_ VCRIGHT_exteriorNightLightCurrent m0 : 52|9@1+ (0.002,0) [0|0] "" Vector__XXX
 SG_ VCRIGHT_leftTrunkLightCurrent m1 : 52|9@1+ (0.002,0) [0|0] "" Vector__XXX
 SG_ VCRIGHT_rearFogLightCurrentSenseState m1 : 49|3@1+ (1,0) [0|0] "" Vector__XXX
 SG_ VCRIGHT_rightTailLightCurrentSenseState m0 : 49|3@1+ (1,0) [0|0] "" Vector__XXX
 SG_ VCRIGHT_cabinTempBreathLevelF5minHeating m8 : 48|8@1+ (0.5,-40) [0|0] "" Vector__XXX
 SG_ VCRIGHT_hvacLowerModeEndStop m3 : 48|8@1+ (0.02,0) [0|0] "" Vector__XXX
 SG_ VCRIGHT_hvacLowerModeZeroStop m4 : 48|8@1+ (0.02,0) [0|0] "" Vector__XXX
 SG_ VCRIGHT_silentWakeRecordCount m6 : 48|5@1+ (1,0) [0|0] "" Vector__XXX
 SG_ VCRIGHT_cabinTempBreathLevelFOff m2 : 47|8@1+ (0.5,-40) [0|0] "" Vector__XXX
 SG_ VCRIGHT_cabinFilterHealthScore m2 : 40|7@1+ (1,0) [0|0] "" Vector__XXX
 SG_ VCRIGHT_cabinTempBreathLevelF10minCooling m8 : 40|8@1+ (0.5,-40) [0|0] "" Vector__XXX
 SG_ VCRIGHT_hvacUpperModeEndStop m3 : 40|8@1+ (0.02,0) [0|0] "" Vector__XXX
 SG_ VCRIGHT_hvacUpperModeZeroStop m4 : 40|8@1+ (0.02,0) [0|0] "" Vector__XXX
 SG_ VCRIGHT_rearFogLightCurrent m1 : 40|9@1+ (0.002,0) [0|0] "" Vector__XXX
 SG_ VCRIGHT_rightTailLightCurrent m0 : 40|9@1+ (0.002,0) [0|0] "" Vector__XXX
 SG_ VCRIGHT_thsSolarIrradianceLimp m6 : 40|8@1+ (5,0) [0|0] "" Vector__XXX
 SG_ VCRIGHT_rightBrakeLightCurrentSenseState m0 : 37|3@1+ (1,0) [0|0] "" Vector__XXX
 SG_ VCRIGHT_rightTrunkLightCurrentSenseState m1 : 37|3@1+ (1,0) [0|0] "" Vector__XXX
 SG_ VCRIGHT_cabinTempBreathLevelF10minHeating m8 : 32|8@1+ (0.5,-40) [0|0] "" Vector__XXX
 SG_ VCRIGHT_hepaFilterHealthScore m2 : 32|7@1+ (1,0) [0|0] "" Vector__XXX
 SG_ VCRIGHT_hvacRHVaneEndStop m3 : 32|8@1+ (0.02,0) [0|0] "" Vector__XXX
 SG_ VCRIGHT_hvacRHVaneZeroStop m4 : 32|8@1+ (0.02,0) [0|0] "" Vector__XXX
 SG_ VCRIGHT_thsCabinWaterMassLimp m6 : 32|8@1+ (0.5,0) [0|0] "" Vector__XXX
 SG_ VCRIGHT_rightBrakeLightCurrent m0 : 28|9@1+ (0.005,0) [0|0] "" Vector__XXX
 SG_ VCRIGHT_rightTrunkLightCurrent m1 : 28|9@1+ (0.002,0) [0|0] "" Vector__XXX
 SG_ VCRIGHT_rightPTCCompromisedRod m2 : 27|3@1+ (1,0) [0|0] "" Vector__XXX
 SG_ VCRIGHT_leftLiftgateTailLightCurrentSenseState m0 : 25|3@1+ (1,0) [0|0] "" Vector__XXX
 SG_ VCRIGHT_reverseLightCurrentSenseState m1 : 25|3@1+ (1,0) [0|0] "" Vector__XXX
 SG_ VCRIGHT_hvacLHVaneEndStop m3 : 24|8@1+ (0.02,0) [0|0] "" Vector__XXX
 SG_ VCRIGHT_hvacLHVaneZeroStop m4 : 24|8@1+ (0.02,0) [0|0] "" Vector__XXX
 SG_ VCRIGHT_leftPTCCompromisedRod m2 : 24|3@1+ (1,0) [0|0] "" Vector__XXX
 SG_ VCRIGHT_tempIncarCabinDeep m8 : 24|8@1+ (0.5,-40) [0|0] "" Vector__XXX
 SG_ VCRIGHT_thsTempLimp m6 : 24|8@1+ (0.5,-40) [0|0] "" Vector__XXX
 SG_ VCRIGHT_rightRearTurnLightCurrentSenseState m0 : 22|3@1+ (1,0) [0|0] "" Vector__XXX
 SG_ VCRIGHT_HEPAAirFilterLifeRemaining m2 : 17|7@1+ (1,0) [0|0] "" Vector__XXX
 SG_ VCRIGHT_cabinProbeTempLimp m6 : 16|8@1+ (0.5,-40) [0|0] "" Vector__XXX
 SG_ VCRIGHT_evapLoadInRecirc m8 : 16|8@1+ (35,0) [0|0] "" Vector__XXX
 SG_ VCRIGHT_hvacRHBleedEndStop m3 : 16|8@1+ (0.02,0) [0|0] "" Vector__XXX
 SG_ VCRIGHT_hvacRHBleedZeroStop m4 : 16|8@1+ (0.02,0) [0|0] "" Vector__XXX
 SG_ VCRIGHT_reverseLightCurrent m1 : 16|9@1+ (0.002,0) [0|0] "" Vector__XXX
 SG_ VCRIGHT_licensePlateLightCurrentSenseState m1 : 13|3@1+ (1,0) [0|0] "" Vector__XXX
 SG_ VCRIGHT_rightRearTurnLightCurrent m0 : 13|9@1+ (0.002,0) [0|0] "" Vector__XXX
 SG_ VCRIGHT_cabinAirFilterLifeRemaining m2 : 10|7@1+ (1,0) [0|0] "" Vector__XXX
 SG_ VCRIGHT_ambientTempLimp m6 : 8|8@1+ (0.5,-40) [0|0] "" Vector__XXX
 SG_ VCRIGHT_evapCondensateMass m7 : 8|8@1+ (2,0) [0|0] "" Vector__XXX
 SG_ VCRIGHT_evapLoadInFresh m8 : 8|8@1+ (35,0) [0|0] "" Vector__XXX
 SG_ VCRIGHT_hvacLHBleedEndStop m3 : 8|8@1+ (0.02,0) [0|0] "" Vector__XXX
 SG_ VCRIGHT_hvacLHBleedZeroStop m4 : 8|8@1+ (0.02,0) [0|0] "" Vector__XXX
 SG_ VCRIGHT_foggingMonitorRuntime m9 : 4|12@1+ (10,0) [0|0] "" Vector__XXX
 SG_ VCRIGHT_leftLiftgateTailLightCurrent m0 : 4|7@1+ (0.002,0) [0|0] "" Vector__XXX
 SG_ VCRIGHT_licensePlateLightCurrent m1 : 4|9@1+ (0.002,0) [0|0] "" Vector__XXX
 SG_ VCRIGHT_logging0point1HzIndex M : 0|4@1+ (1,0) [0|0] "" Vector__XXX

BO_ 1806 OCS1P_debugRebaseline2: 8 Vector__XXX
 SG_ OCS1P_deltaFreqSeatbackSelfMax : 48|14@1- (10,0) [0|0] "" Vector__XXX
 SG_ OCS1P_deltaFreqCushionSelfMax : 33|14@1- (10,0) [0|0] "" Vector__XXX
 SG_ OCS1P_LCBUpdated : 32|1@1+ (1,0) [0|0] "" Vector__XXX
 SG_ OCS1P_seatbackSelfOffsetLCB : 16|16@1- (0.005,0) [0|0] "" Vector__XXX
 SG_ OCS1P_cushionSelfOffsetLCB : 0|16@1- (0.005,0) [0|0] "" Vector__XXX

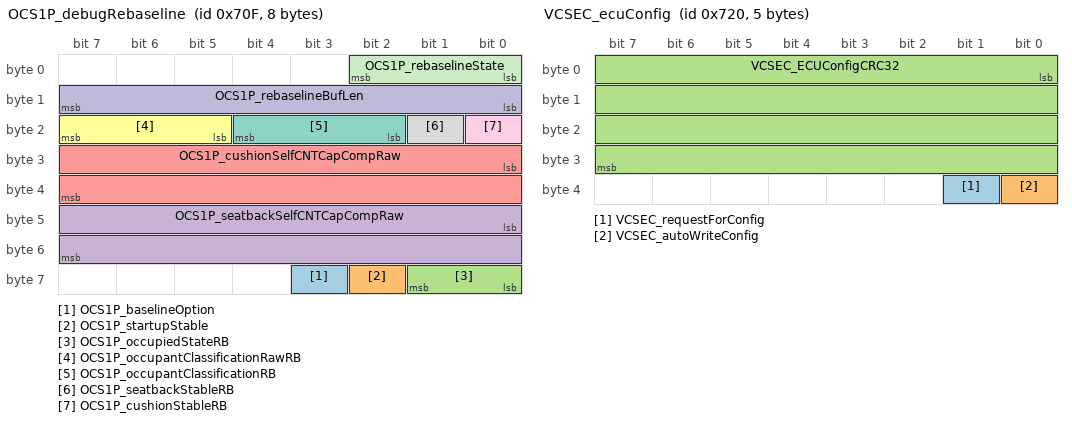
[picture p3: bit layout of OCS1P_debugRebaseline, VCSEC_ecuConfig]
BO_ 1807 OCS1P_debugRebaseline: 8 Vector__XXX
 SG_ OCS1P_baselineOption : 59|1@1+ (1,0) [0|0] "" Vector__XXX
 SG_ OCS1P_startupStable : 58|1@1+ (1,0) [0|0] "" Vector__XXX
 SG_ OCS1P_occupiedStateRB : 56|2@1+ (1,0) [0|0] "" Vector__XXX
 SG_ OCS1P_seatbackSelfCNTCapCompRaw : 40|16@1+ (0.005,0) [0|0] "" Vector__XXX
 SG_ OCS1P_cushionSelfCNTCapCompRaw : 24|16@1+ (0.005,0) [0|0] "" Vector__XXX
 SG_ OCS1P_occupantClassificationRawRB : 21|3@1+ (1,0) [0|0] "" Vector__XXX
 SG_ OCS1P_occupantClassificationRB : 18|3@1+ (1,0) [0|0] "" Vector__XXX
 SG_ OCS1P_seatbackStableRB : 17|1@1+ (1,0) [0|0] "" Vector__XXX
 SG_ OCS1P_cushionStableRB : 16|1@1+ (1,0) [0|0] "" Vector__XXX
 SG_ OCS1P_rebaselineBufLen : 8|8@1+ (1,0) [0|0] "" Vector__XXX
 SG_ OCS1P_rebaselineState : 0|3@1+ (1,0) [0|0] "" Vector__XXX

BO_ 1810 BMS_packTemperatureMeasurements: 8 Vector__XXX
 SG_ BMS_packTemperature12 m3 : 48|16@1- (0.01,0) [0|0] "" Vector__XXX
 SG_ BMS_packTemperature15 m4 : 48|16@1- (0.01,0) [0|0] "" Vector__XXX
 SG_ BMS_packTemperature18 m5 : 48|16@1- (0.01,0) [0|0] "" Vector__XXX
 SG_ BMS_packTemperature3 m0 : 48|16@1- (0.01,0) [0|0] "" Vector__XXX
 SG_ BMS_packTemperature6 m1 : 48|16@1- (0.01,0) [0|0] "" Vector__XXX
 SG_ BMS_packTemperature9 m2 : 48|16@1- (0.01,0) [0|0] "" Vector__XXX
 SG_ BMS_packTemperature11 m3 : 32|16@1- (0.01,0) [0|0] "" Vector__XXX
 SG_ BMS_packTemperature14 m4 : 32|16@1- (0.01,0) [0|0] "" Vector__XXX
 SG_ BMS_packTemperature17 m5 : 32|16@1- (0.01,0) [0|0] "" Vector__XXX
 SG_ BMS_packTemperature2 m0 : 32|16@1- (0.01,0) [0|0] "" Vector__XXX
 SG_ BMS_packTemperature5 m1 : 32|16@1- (0.01,0) [0|0] "" Vector__XXX
 SG_ BMS_packTemperature8 m2 : 32|16@1- (0.01,0) [0|0] "" Vector__XXX
 SG_ BMS_packTemperature1 m0 : 16|16@1- (0.01,0) [0|0] "" Vector__XXX
 SG_ BMS_packTemperature10 m3 : 16|16@1- (0.01,0) [0|0] "" Vector__XXX
 SG_ BMS_packTemperature13 m4 : 16|16@1- (0.01,0) [0|0] "" Vector__XXX
 SG_ BMS_packTemperature16 m5 : 16|16@1- (0.01,0) [0|0] "" Vector__XXX
 SG_ BMS_packTemperature4 m1 : 16|16@1- (0.01,0) [0|0] "" Vector__XXX
 SG_ BMS_packTemperature7 m2 : 16|16@1- (0.01,0) [0|0] "" Vector__XXX
 SG_ BMS_packTemperatureCounter : 14|2@1+ (1,0) [0|0] "" Vector__XXX
 SG_ BMS_packTemperatureStatus12 m3 : 12|2@1+ (1,0) [0|0] "" Vector__XXX
 SG_ BMS_packTemperatureStatus15 m4 : 12|2@1+ (1,0) [0|0] "" Vector__XXX
 SG_ BMS_packTemperatureStatus18 m5 : 12|2@1+ (1,0) [0|0] "" Vector__XXX
 SG_ BMS_packTemperatureStatus3 m0 : 12|2@1+ (1,0) [0|0] "" Vector__XXX
 SG_ BMS_packTemperatureStatus6 m1 : 12|2@1+ (1,0) [0|0] "" Vector__XXX
 SG_ BMS_packTemperatureStatus9 m2 : 12|2@1+ (1,0) [0|0] "" Vector__XXX
 SG_ BMS_packTemperatureStatus11 m3 : 10|2@1+ (1,0) [0|0] "" Vector__XXX
 SG_ BMS_packTemperatureStatus14 m4 : 10|2@1+ (1,0) [0|0] "" Vector__XXX
 SG_ BMS_packTemperatureStatus17 m5 : 10|2@1+ (1,0) [0|0] "" Vector__XXX
 SG_ BMS_packTemperatureStatus2 m0 : 10|2@1+ (1,0) [0|0] "" Vector__XXX
 SG_ BMS_packTemperatureStatus5 m1 : 10|2@1+ (1,0) [0|0] "" Vector__XXX
 SG_ BMS_packTemperatureStatus8 m2 : 10|2@1+ (1,0) [0|0] "" Vector__XXX
 SG_ BMS_packTemperatureStatus1 m0 : 8|2@1+ (1,0) [0|0] "" Vector__XXX
 SG_ BMS_packTemperatureStatus10 m3 : 8|2@1+ (1,0) [0|0] "" Vector__XXX
 SG_ BMS_packTemperatureStatus13 m4 : 8|2@1+ (1,0) [0|0] "" Vector__XXX
 SG_ BMS_packTemperatureStatus16 m5 : 8|2@1+ (1,0) [0|0] "" Vector__XXX
 SG_ BMS_packTemperatureStatus4 m1 : 8|2@1+ (1,0) [0|0] "" Vector__XXX
 SG_ BMS_packTemperatureStatus7 m2 : 8|2@1+ (1,0) [0|0] "" Vector__XXX
 SG_ BMS_packTemperatureMultiplexer M : 0|8@1+ (1,0) [0|0] "" Vector__XXX

BO_ 1812 PMR_xcpResponse: 12 Vector__XXX
 SG_ PMR_xcpResponseData : 7|64@0+ (1,0) [0|0] "" Vector__XXX

BO_ 1814 DIR_xcpResponse: 12 Vector__XXX
 SG_ DIR_xcpResponseData : 7|64@0+ (1,0) [0|0] "" Vector__XXX

BO_ 1815 RCM_imuOffsets: 7 Vector__XXX
 SG_ RCM_CGZdistance m2 : 40|16@1+ (1,-32768) [0|0] "" Vector__XXX
 SG_ RCM_rollRateOffset m0 : 40|16@1- (0.0001,0) [0|0] "" Vector__XXX
 SG_ RCM_verticalAccelOffset m1 : 40|16@1- (0.00125,0) [0|0] "" Vector__XXX
 SG_ RCM_CGYdistance m2 : 24|16@1+ (1,-32768) [0|0] "" Vector__XXX
 SG_ RCM_lateralAccelOffset m1 : 24|16@1- (0.00125,0) [0|0] "" Vector__XXX
 SG_ RCM_pitchRateOffset m0 : 24|16@1- (0.0001,0) [0|0] "" Vector__XXX
 SG_ RCM_CGXdistance m2 : 8|16@1+ (1,-32768) [0|0] "" Vector__XXX
 SG_ RCM_longitudinalAccelOffset m1 : 8|16@1- (0.00125,0) [0|0] "" Vector__XXX
 SG_ RCM_yawRateOffset m0 : 8|16@1- (0.0001,0) [0|0] "" Vector__XXX
 SG_ RCM_imuOffsetsIndex M : 0|2@1+ (1,0) [0|0] "" Vector__XXX

BO_ 1816 VC_LVBMS_statusLow: 8 Vector__XXX
 SG_ VC_LVBMS_MosfetStuckOpenError m0 : 51|1@1+ (1,0) [0|0] "" Vector__XXX
 SG_ VC_LVBMS_MosfetStuckCloseError m0 : 50|1@1+ (1,0) [0|0] "" Vector__XXX
 SG_ VC_LVBMS_SamplingError m0 : 49|1@1+ (1,0) [0|0] "" Vector__XXX
 SG_ VC_LVBMS_DeepDischargeFlag m0 : 48|1@1+ (1,0) [0|0] "" Vector__XXX
 SG_ VC_LVBMS_SOP m1 : 48|8@1+ (20,0) [0|0] "" Vector__XXX
 SG_ VC_LVBMS_NTCTempDiffWarnLevel1 m0 : 47|1@1+ (1,0) [0|0] "" Vector__XXX
 SG_ VC_LVBMS_MOSStateFault m0 : 46|1@1+ (1,0) [0|0] "" Vector__XXX
 SG_ VC_LVBMS_BalanceCircuitFault m0 : 45|1@1+ (1,0) [0|0] "" Vector__XXX
 SG_ VC_LVBMS_KBValueLostFault m0 : 44|1@1+ (1,0) [0|0] "" Vector__XXX
 SG_ VC_LVBMS_MOSFETOTLevel1 m0 : 43|1@1+ (1,0) [0|0] "" Vector__XXX
 SG_ VC_LVBMS_ChrgOCLevel2 m0 : 42|1@1+ (1,0) [0|0] "" Vector__XXX
 SG_ VC_LVBMS_ChrgOCLevel1 m0 : 41|1@1+ (1,0) [0|0] "" Vector__XXX
 SG_ VC_LVBMS_usableEnergyAvailable m4 : 41|12@1+ (1,0) [0|0] "" Vector__XXX
 SG_ VC_LVBMS_DischrgOCLevel2 m0 : 40|1@1+ (1,0) [0|0] "" Vector__XXX
 SG_ VC_LVBMS_MaxSleepCurrent m3 : 40|16@1+ (0.01,-200) [0|0] "" Vector__XXX
 SG_ VC_LVBMS_MinSleepCurrent m2 : 40|16@1+ (0.01,-200) [0|0] "" Vector__XXX
 SG_ VC_LVBMS_dynamicSOCCorrection m4 : 40|1@1+ (1,0) [0|0] "" Vector__XXX
 SG_ VC_LVBMS_DischrgOCLevel1 m0 : 39|1@1+ (1,0) [0|0] "" Vector__XXX
 SG_ VC_LVBMS_staticSOCCorrection m4 : 39|1@1+ (1,0) [0|0] "" Vector__XXX
 SG_ VC_LVBMS_PackOVLevel2 m0 : 38|1@1+ (1,0) [0|0] "" Vector__XXX
 SG_ VC_LVBMS_PackOVLevel1 m0 : 37|1@1+ (1,0) [0|0] "" Vector__XXX
 SG_ VC_LVBMS_ModuleOTLevel1 m0 : 36|1@1+ (1,0) [0|0] "" Vector__XXX
 SG_ VC_LVBMS_CellUVLevel2 m0 : 35|1@1+ (1,0) [0|0] "" Vector__XXX
 SG_ VC_LVBMS_CellUVLevel1 m0 : 34|1@1+ (1,0) [0|0] "" Vector__XXX
 SG_ VC_LVBMS_CellOVLevel3 m0 : 33|1@1+ (1,0) [0|0] "" Vector__XXX
 SG_ VC_LVBMS_CellOVLevel2 m0 : 32|1@1+ (1,0) [0|0] "" Vector__XXX
 SG_ VC_LVBMS_minCellSOC m4 : 32|7@1+ (1,0) [0|0] "" Vector__XXX
 SG_ VC_LVBMS_CellOVLevel1 m0 : 31|1@1+ (1,0) [0|0] "" Vector__XXX
 SG_ VC_LVBMS_SOH m0 : 24|7@1+ (1,0) [0|0] "" Vector__XXX
 SG_ VC_LVBMS_TimeSlept m1 : 24|24@1+ (1,0) [0|0] "" Vector__XXX
 SG_ VC_LVBMS_maxCellSOC m4 : 24|7@1+ (1,0) [0|0] "" Vector__XXX
 SG_ VC_LVBMS_SOE m0 : 16|7@1+ (1,0) [0|0] "" Vector__XXX
 SG_ VC_LVBMS_AhCharged m2 : 8|32@1+ (0.001,0) [0|0] "" Vector__XXX
 SG_ VC_LVBMS_AhDischarged m3 : 8|32@1+ (0.001,0) [0|0] "" Vector__XXX
 SG_ VC_LVBMS_AvgSleepCurrent m1 : 8|16@1+ (0.01,-200) [0|0] "" Vector__XXX
 SG_ VC_LVBMS_SOC m0 : 8|7@1+ (1,0) [0|0] "" Vector__XXX
 SG_ VC_LVBMS_sumCellVoltageFiltered m4 : 8|16@1+ (0.001,0) [0|0] "" Vector__XXX
 SG_ VC_lvbmsStatusLowIndex M : 0|3@1+ (1,0) [0|0] "" Vector__XXX

BO_ 1817 VCSEC_debug100ms: 8 Vector__XXX
 SG_ VCSEC_UHFInterruptState m2 : 61|1@1+ (1,0) [0|0] "" Vector__XXX
 SG_ VCSEC_BLE2PhoneBatteryLevel m20 : 58|6@1+ (2,0) [0|0] "" Vector__XXX
 SG_ VCSEC_lastFromVCSECTagSentRemote m13 : 57|7@1+ (1,0) [0|0] "" Vector__XXX
 SG_ VCSEC_BLE2PhoneBatteryState m20 : 56|2@1+ (1,0) [0|0] "" Vector__XXX
 SG_ VCSEC_algoNNPresentRevision m14 : 56|8@1+ (1,0) [0|0] "" Vector__XXX
 SG_ VCSEC_BLE2LastMessageRoutable m12 : 55|1@1+ (1,0) [0|0] "" Vector__XXX
 SG_ VCSEC_chargeHandleMitigationActi m0 : 55|1@1+ (1,0) [0|0] "" Vector__XXX
 SG_ VCSEC_BLE1LastMessageRoutable m12 : 54|1@1+ (1,0) [0|0] "" Vector__XXX
 SG_ VCSEC_BLE0LastMessageRoutable m12 : 53|1@1+ (1,0) [0|0] "" Vector__XXX
 SG_ VCSEC_thermalDetectState m0 : 53|2@1+ (1,0) [0|0] "" Vector__XXX
 SG_ VCSEC_routableNotDispatched m12 : 52|1@1+ (1,0) [0|0] "" Vector__XXX
 SG_ VCSEC_BLE1PhoneBatteryLevel m20 : 50|6@1+ (2,0) [0|0] "" Vector__XXX
 SG_ VCSEC_lastFromVCSECTagSentBLE2 m13 : 50|7@1+ (1,0) [0|0] "" Vector__XXX
 SG_ VCSEC_BLE1PhoneBatteryState m20 : 48|2@1+ (1,0) [0|0] "" Vector__XXX
 SG_ VCSEC_algoNNPresentClassifi_0003 m14 : 48|7@1+ (0.01,0) [0|0] "" Vector__XXX
 SG_ VCSEC_incomingMessageSigStartFai m12 : 48|4@1+ (1,0) [0|0] "" Vector__XXX
 SG_ VCSEC_numberOfPubKeysOnWhitelist m0 : 48|5@1+ (1,0) [0|0] "" Vector__XXX
 SG_ VCSEC_UHFNumberEndpointResets m2 : 45|16@1+ (1,0) [0|0] "" Vector__XXX
 SG_ VCSEC_UHFFaultCalibrationFail m2 : 44|1@1+ (1,0) [0|0] "" Vector__XXX
 SG_ VCSEC_incomingMessageChannelBusy m12 : 44|4@1+ (1,0) [0|0] "" Vector__XXX
 SG_ VCSEC_UHFFaultPLLNotLocked m2 : 43|1@1+ (1,0) [0|0] "" Vector__XXX
 SG_ VCSEC_lastFromVCSECTagSentBLE1 m13 : 43|7@1+ (1,0) [0|0] "" Vector__XXX
 SG_ VCSEC_pollingReason m0 : 43|4@1+ (1,0) [0|0] "" Vector__XXX
 SG_ VCSEC_BLE0PhoneBatteryLevel m20 : 42|6@1+ (2,0) [0|0] "" Vector__XXX
 SG_ VCSEC_UHFFaultRadioBadState m2 : 42|1@1+ (1,0) [0|0] "" Vector__XXX
 SG_ VCSEC_algoHighThreshCenter m0 : 42|1@1+ (1,0) [0|0] "" Vector__XXX
 SG_ VCSEC_UHFFaultSPITimeout m2 : 41|1@1+ (1,0) [0|0] "" Vector__XXX
 SG_ VCSEC_algoHighThreshRight m0 : 41|1@1+ (1,0) [0|0] "" Vector__XXX
 SG_ VCSEC_BLE0PhoneBatteryState m20 : 40|2@1+ (1,0) [0|0] "" Vector__XXX
 SG_ VCSEC_UHFFaultResponseTimeout m2 : 40|1@1+ (1,0) [0|0] "" Vector__XXX
 SG_ VCSEC_algoHighThreshLeft m0 : 40|1@1+ (1,0) [0|0] "" Vector__XXX
 SG_ VCSEC_algoNNPresentClassifi_0002 m14 : 40|7@1+ (0.01,0) [0|0] "" Vector__XXX
 SG_ VCSEC_incomingMessageOutOfAddres m12 : 40|4@1+ (1,0) [0|0] "" Vector__XXX
 SG_ VCSEC_UHFFaultReceiverReset m2 : 39|1@1+ (1,0) [0|0] "" Vector__XXX
 SG_ VCSEC_UHFRecalibrationFailure m2 : 38|1@1+ (1,0) [0|0] "" Vector__XXX
 SG_ VCSEC_UHFRecalibrated m2 : 37|1@1+ (1,0) [0|0] "" Vector__XXX
 SG_ VCSEC_walkUpUnlockState m0 : 37|3@1+ (1,0) [0|0] "" Vector__XXX
 SG_ VCSEC_infoRequestSlotsCounter m12 : 36|4@1+ (1,0) [0|0] "" Vector__XXX
 SG_ VCSEC_lastFromVCSECTagSentBLE0 m13 : 36|7@1+ (1,0) [0|0] "" Vector__XXX
 SG_ VCSEC_BLE2WatchBatteryLevel m20 : 34|6@1+ (2,0) [0|0] "" Vector__XXX
 SG_ VCSEC_UHFRecalibrationState m2 : 34|3@1+ (1,0) [0|0] "" Vector__XXX
 SG_ VCSEC_BLE2WatchExceededBgNotiLim m20 : 33|1@1+ (1,0) [0|0] "" Vector__XXX
 SG_ VCSEC_BLE0AuthResponseSplit m21 : 32|8@1+ (10,0) [0|0] "" Vector__XXX
 SG_ VCSEC_BLE1AuthResponseSplit m22 : 32|8@1+ (10,0) [0|0] "" Vector__XXX
 SG_ VCSEC_BLE2AuthResponseSplit m23 : 32|8@1+ (10,0) [0|0] "" Vector__XXX
 SG_ VCSEC_BLE2WatchNearBackgroundNot m20 : 32|1@1+ (1,0) [0|0] "" Vector__XXX
 SG_ VCSEC_algoNNPresentClassifierFil m14 : 32|7@1+ (0.01,0) [0|0] "" Vector__XXX
 SG_ VCSEC_flowControlSentCounter m12 : 32|4@1+ (1,0) [0|0] "" Vector__XXX
 SG_ VCSEC_lastSPComm_central_TPMS3 m19 : 32|2@1+ (1,0) [0|0] "" Vector__XXX
 SG_ VCSEC_rearAdvertRSSI m3 : 32|8@1- (1,0) [0|0] "" Vector__XXX
 SG_ VCSEC_rssi2WLEntry m0 : 32|5@1+ (1,0) [0|0] "" Vector__XXX
 SG_ VCSEC_BLE2WatchAppState m20 : 30|2@1+ (1,0) [0|0] "" Vector__XXX
 SG_ VCSEC_lastSPComm_central_TPMS2 m19 : 30|2@1+ (1,0) [0|0] "" Vector__XXX
 SG_ VCSEC_lastToVCSECTagReceivedRemo m13 : 29|7@1+ (1,0) [0|0] "" Vector__XXX
 SG_ VCSEC_UHFDevUHFState m2 : 28|6@1+ (1,0) [0|0] "" Vector__XXX
 SG_ VCSEC_lastSPComm_central_TPMS1 m19 : 28|2@1+ (1,0) [0|0] "" Vector__XXX
 SG_ VCSEC_routingChannelBusyCounter m12 : 28|4@1+ (1,0) [0|0] "" Vector__XXX
 SG_ VCSEC_UHFSleep m2 : 27|1@1+ (1,0) [0|0] "" Vector__XXX
 SG_ VCSEC_lastSPComm_central_TPMS0 m19 : 26|2@1+ (1,0) [0|0] "" Vector__XXX
 SG_ VCSEC_BLE0SignUpSplit m21 : 24|8@1+ (10,0) [0|0] "" Vector__XXX
 SG_ VCSEC_BLE1SignUpSplit m22 : 24|8@1+ (10,0) [0|0] "" Vector__XXX
 SG_ VCSEC_BLE1WatchBatteryLevel m20 : 24|6@1+ (2,0) [0|0] "" Vector__XXX
 SG_ VCSEC_BLE2SignUpSplit m23 : 24|8@1+ (10,0) [0|0] "" Vector__XXX
 SG_ VCSEC_UHFradioState m2 : 24|3@1+ (1,0) [0|0] "" Vector__XXX
 SG_ VCSEC_algoNNPresentClassifi_0001 m14 : 24|7@1+ (0.01,0) [0|0] "" Vector__XXX
 SG_ VCSEC_device2Offset m1 : 24|6@1- (0.5,0) [0|0] "" Vector__XXX
 SG_ VCSEC_lastSPComm_central_BLE2 m19 : 24|2@1+ (1,0) [0|0] "" Vector__XXX
 SG_ VCSEC_rightAdvertRSSI m3 : 24|8@1- (1,0) [0|0] "" Vector__XXX
 SG_ VCSEC_routingOutofAddressCounter m12 : 24|4@1+ (1,0) [0|0] "" Vector__XXX
 SG_ VCSEC_rssi1WLEntry m0 : 24|5@1+ (1,0) [0|0] "" Vector__XXX
 SG_ VCSEC_UHFBasestationInitialized m2 : 22|1@1+ (1,0) [0|0] "" Vector__XXX
 SG_ VCSEC_lastSPComm_central_BLE1 m19 : 22|2@1+ (1,0) [0|0] "" Vector__XXX
 SG_ VCSEC_lastToVCSECTagReceivedBLE2 m13 : 22|7@1+ (1,0) [0|0] "" Vector__XXX
 SG_ VCSEC_endpointLayout m0 : 21|2@1+ (1,0) [0|0] "" Vector__XXX
 SG_ VCSEC_lastSPComm_central_BLE0 m19 : 20|2@1+ (1,0) [0|0] "" Vector__XXX
 SG_ VCSEC_routingCantFindAddressCoun m12 : 20|4@1+ (1,0) [0|0] "" Vector__XXX
 SG_ VCSEC_BLE1WatchExceededBgNotiLim m20 : 19|1@1+ (1,0) [0|0] "" Vector__XXX
 SG_ VCSEC_BLE1WatchNearBackgroundNot m20 : 18|1@1+ (1,0) [0|0] "" Vector__XXX
 SG_ VCSEC_lastSPComm_peripheral_0002 m19 : 18|2@1+ (1,0) [0|0] "" Vector__XXX
 SG_ VCSEC_BLE0ServiceDiscoverySplit m21 : 16|8@1+ (10,0) [0|0] "" Vector__XXX
 SG_ VCSEC_BLE1ServiceDiscoverySplit m22 : 16|8@1+ (10,0) [0|0] "" Vector__XXX
 SG_ VCSEC_BLE1WatchAppState m20 : 16|2@1+ (1,0) [0|0] "" Vector__XXX
 SG_ VCSEC_BLE2ServiceDiscoverySplit m23 : 16|8@1+ (10,0) [0|0] "" Vector__XXX
 SG_ VCSEC_UHFMeasureofSuccess m2 : 16|6@1+ (1,0) [0|0] "" Vector__XXX
 SG_ VCSEC_algoNNPresentClassifi_0000 m14 : 16|7@1+ (0.01,0) [0|0] "" Vector__XXX
 SG_ VCSEC_device1Offset m1 : 16|6@1- (0.5,0) [0|0] "" Vector__XXX
 SG_ VCSEC_lastSPComm_peripheral_0001 m19 : 16|2@1+ (1,0) [0|0] "" Vector__XXX
 SG_ VCSEC_leftAdvertRSSI m3 : 16|8@1- (1,0) [0|0] "" Vector__XXX
 SG_ VCSEC_routingAddressesFreeCounte m12 : 16|4@1+ (1,0) [0|0] "" Vector__XXX
 SG_ VCSEC_rssi0WLEntry m0 : 16|5@1+ (1,0) [0|0] "" Vector__XXX
 SG_ VCSEC_lastToVCSECTagReceivedBLE1 m13 : 15|7@1+ (1,0) [0|0] "" Vector__XXX
 SG_ VCSEC_lastSPComm_peripheral_0000 m19 : 14|2@1+ (1,0) [0|0] "" Vector__XXX
 SG_ VCSEC_lastSPComm_peripheral_TPMS m19 : 12|2@1+ (1,0) [0|0] "" Vector__XXX
 SG_ VCSEC_routablesProcessed m12 : 12|4@1+ (1,0) [0|0] "" Vector__XXX
 SG_ VCSEC_walkAwayLockState m0 : 11|3@1+ (1,0) [0|0] "" Vector__XXX
 SG_ VCSEC_lastSPComm_peripheral_BLE2 m19 : 10|2@1+ (1,0) [0|0] "" Vector__XXX
 SG_ VCSEC_BLE0WatchBatteryLevel m20 : 9|6@1+ (2,0) [0|0] "" Vector__XXX
 SG_ VCSEC_algoNNPresentClassifierRaw m14 : 9|7@1+ (0.01,0) [0|0] "" Vector__XXX
 SG_ VCSEC_BLE0MTUExchangeSplit m21 : 8|8@1+ (10,0) [0|0] "" Vector__XXX
 SG_ VCSEC_BLE0WatchExceededBgNotiLim m20 : 8|1@1+ (1,0) [0|0] "" Vector__XXX
 SG_ VCSEC_BLE1MTUExchangeSplit m22 : 8|8@1+ (10,0) [0|0] "" Vector__XXX
 SG_ VCSEC_BLE2MTUExchangeSplit m23 : 8|8@1+ (10,0) [0|0] "" Vector__XXX
 SG_ VCSEC_UHFRSSI m2 : 8|8@1- (1,0) [0|0] "" Vector__XXX
 SG_ VCSEC_algoNNPresentEnsemble_0000 m14 : 8|1@1+ (1,0) [0|0] "" Vector__XXX
 SG_ VCSEC_centerAdvertRSSI m3 : 8|8@1- (1,0) [0|0] "" Vector__XXX
 SG_ VCSEC_device0Offset m1 : 8|6@1- (0.5,0) [0|0] "" Vector__XXX
 SG_ VCSEC_lastSPComm_peripheral_BLE1 m19 : 8|2@1+ (1,0) [0|0] "" Vector__XXX
 SG_ VCSEC_lastToVCSECTagReceivedBLE0 m13 : 8|7@1+ (1,0) [0|0] "" Vector__XXX
 SG_ VCSEC_routingCompleteCounter m12 : 8|4@1+ (1,0) [0|0] "" Vector__XXX
 SG_ VCSEC_thresholdOffsetVersion m0 : 8|3@1+ (1,0) [0|0] "" Vector__XXX
 SG_ VCSEC_BLE0WatchNearBackgroundNot m20 : 7|1@1+ (1,0) [0|0] "" Vector__XXX
 SG_ VCSEC_algoNNPresentEnsembleClass m14 : 7|1@1+ (1,0) [0|0] "" Vector__XXX
 SG_ VCSEC_algoNNPresentModelClassFil m14 : 6|1@1+ (1,0) [0|0] "" Vector__XXX
 SG_ VCSEC_BLE0WatchAppState m20 : 5|2@1+ (1,0) [0|0] "" Vector__XXX
 SG_ VCSEC_algoHighThreshRear m1 : 5|1@1+ (1,0) [0|0] "" Vector__XXX
 SG_ VCSEC_algoNNPresentModelClassRaw m14 : 5|1@1+ (1,0) [0|0] "" Vector__XXX
 SG_ VCSEC_lastSPComm_peripheral_BLE0 m19 : 5|2@1+ (1,0) [0|0] "" Vector__XXX
 SG_ VCSEC_walkAwayLockKeyState m0 : 5|2@1+ (1,0) [0|0] "" Vector__XXX
 SG_ VCSEC_debug100msIndex M : 0|5@1+ (1,0) [0|0] "" Vector__XXX

BO_ 1822 GB_chgLogData: 8 Vector__XXX
 SG_ GB_Chg_Permission m5 : 56|2@1+ (1,0) [0|0] "" Vector__XXX
 SG_ GB_Min_Output_I m3 : 51|13@1+ (0.1,-400) [0|0] "" Vector__XXX
 SG_ GB_EVSE_maxCurrentLimit_exp m11 : 43|3@1- (1,0) [0|0] "" Vector__XXX
 SG_ GB_Chg_Time m5 : 40|16@1+ (1,0) [0|0] "" Vector__XXX
 SG_ GB_EVSE_outputCurrent_exp m11 : 40|3@1- (1,0) [0|0] "" Vector__XXX
 SG_ GB_Max_Output_I m3 : 38|13@1+ (0.1,-400) [0|0] "" Vector__XXX
 SG_ GB_Chg_Stop_Rsn_V_ERR m6 : 26|2@1+ (1,0) [0|0] "" Vector__XXX
 SG_ GB_Chg_Stop_Rsn_I_Match_ERR m6 : 24|2@1+ (1,0) [0|0] "" Vector__XXX
 SG_ GB_EVSE_maxCurrentLimit_value m11 : 24|16@1- (1,0) [0|0] "" Vector__XXX
 SG_ GB_EVSE_teslaGbProtocolVersion m9 : 24|8@1+ (1,0) [0|0] "" Vector__XXX
 SG_ GB_Iout m5 : 24|16@1+ (0.1,-400) [0|0] "" Vector__XXX
 SG_ GB_Min_Output_V m3 : 24|14@1+ (0.1,0) [0|0] "" Vector__XXX
 SG_ GB_Total_Chg_Energy m7 : 24|16@1+ (0.1,0) [0|0] "" Vector__XXX
 SG_ GB_Chg_Stop_Rsn_Other_FLT m6 : 22|2@1+ (1,0) [0|0] "" Vector__XXX
 SG_ GB_Chg_Stop_Rsn_E_Stop_FLT m6 : 20|2@1+ (1,0) [0|0] "" Vector__XXX
 SG_ GB_BMS_CHG_Others m8 : 18|6@1+ (1,0) [0|0] "" Vector__XXX
 SG_ GB_Chg_Stop_Rsn_Bad_Req_FLT m6 : 18|2@1+ (1,0) [0|0] "" Vector__XXX
 SG_ GB_BMS_CHG_Statistic_Tmt m8 : 16|2@1+ (1,0) [0|0] "" Vector__XXX
 SG_ GB_Charger_Number m1 : 16|32@1+ (1,0) [0|0] "" Vector__XXX
 SG_ GB_Chg_Stop_Rsn_EVSE_OT_FLT m6 : 16|2@1+ (1,0) [0|0] "" Vector__XXX
 SG_ GB_BMS_CHG_Stop_Tmt m8 : 14|2@1+ (1,0) [0|0] "" Vector__XXX
 SG_ GB_Chg_Stop_Rsn_Conn_FLT m6 : 14|2@1+ (1,0) [0|0] "" Vector__XXX
 SG_ GB_BMS_CHG_Demand_Tmt m8 : 12|2@1+ (1,0) [0|0] "" Vector__XXX
 SG_ GB_Chg_Stop_Rsn_OT_FLT m6 : 12|2@1+ (1,0) [0|0] "" Vector__XXX
 SG_ GB_BMS_CHG_Status_Tmt m8 : 10|2@1+ (1,0) [0|0] "" Vector__XXX
 SG_ GB_Chg_Stop_Rsn_BST m6 : 10|2@1+ (1,0) [0|0] "" Vector__XXX
 SG_ GB_BMS_CHG_Ready_Tmt m8 : 8|2@1+ (1,0) [0|0] "" Vector__XXX
 SG_ GB_Chg_Stop_Rsn_Error m6 : 8|2@1+ (1,0) [0|0] "" Vector__XXX
 SG_ GB_EVSE_outputCurrent_value m11 : 8|16@1- (1,0) [0|0] "" Vector__XXX
 SG_ GB_FC_maxCurrentLimit m9 : 8|16@1+ (0.1,-400) [0|0] "" Vector__XXX
 SG_ GB_Local_Area_Number m2 : 8|24@1+ (1,0) [0|0] "" Vector__XXX
 SG_ GB_Max_Output_V m3 : 8|14@1+ (0.1,0) [0|0] "" Vector__XXX
 SG_ GB_Protocol_Ver m0 : 8|24@1+ (1,0) [0|0] "" Vector__XXX
 SG_ GB_Recognition_Result m1 : 8|8@1+ (1,0) [0|0] "" Vector__XXX
 SG_ GB_Total_Chg_Time m7 : 8|16@1+ (1,0) [0|0] "" Vector__XXX
 SG_ GB_Vout m5 : 8|16@1+ (0.1,0) [0|0] "" Vector__XXX
 SG_ GB_ready m4 : 8|8@1+ (1,0) [0|0] "" Vector__XXX
 SG_ GB_BMS_CHG_Param_Tmt m8 : 6|2@1+ (1,0) [0|0] "" Vector__XXX
 SG_ GB_Chg_Stop_Rsn_Manual m6 : 6|2@1+ (1,0) [0|0] "" Vector__XXX
 SG_ GB_BMS_ID_Tmt m8 : 4|2@1+ (1,0) [0|0] "" Vector__XXX
 SG_ GB_Chg_Stop_Rsn_Setpoint m6 : 4|2@1+ (1,0) [0|0] "" Vector__XXX
 SG_ GB_chgLogDataSelect M : 0|4@1+ (1,0) [0|0] "" Vector__XXX

BO_ 1824 VCSEC_ecuConfig: 5 Vector__XXX
 SG_ VCSEC_requestForConfig : 33|1@1+ (1,0) [0|0] "" Vector__XXX
 SG_ VCSEC_autoWriteConfig : 32|1@1+ (1,0) [0|0] "" Vector__XXX
 SG_ VCSEC_ECUConfigCRC32 : 0|32@1+ (1,0) [0|0] "" Vector__XXX

BO_ 1825 VCFRONT_debugThermal1Hz: 8 Vector__XXX
 SG_ VCFRONT_fanRadStatDiagFail m4 : 63|1@1+ (1,0) [0|0] "" Vector__XXX
 SG_ VCFRONT_fanRadStatSPIFail m4 : 62|1@1+ (1,0) [0|0] "" Vector__XXX
 SG_ VCFRONT_fanRadStatOTPAny m4 : 61|1@1+ (1,0) [0|0] "" Vector__XXX
 SG_ VCFRONT_fanRadStatMode m4 : 59|2@1+ (1,0) [0|0] "" Vector__XXX
 SG_ VCFRONT_fanRadPwmInputFault m4 : 58|1@1+ (1,0) [0|0] "" Vector__XXX
 SG_ VCFRONT_fanRadVccUnderVoltage m4 : 57|1@1+ (1,0) [0|0] "" Vector__XXX
 SG_ VCFRONT_fanRadLossOfSpeedLock m4 : 56|1@1+ (1,0) [0|0] "" Vector__XXX
 SG_ VCFRONT_activeDemandChiller m0 : 55|7@1+ (1,0) [0|0] "" Vector__XXX
 SG_ VCFRONT_fanRadStartUpOperation m4 : 55|1@1+ (1,0) [0|0] "" Vector__XXX
 SG_ VCFRONT_fanRadWatchdogTimeout m4 : 54|1@1+ (1,0) [0|0] "" Vector__XXX
 SG_ VCFRONT_fanRadJunctionOverTemp m4 : 53|1@1+ (1,0) [0|0] "" Vector__XXX
 SG_ VCFRONT_fanRadJunctionTempWarn m4 : 52|1@1+ (1,0) [0|0] "" Vector__XXX
 SG_ VCFRONT_fanRadLockedRotor m4 : 51|1@1+ (1,0) [0|0] "" Vector__XXX
 SG_ VCFRONT_fanRadThOverTemperature m4 : 50|1@1+ (1,0) [0|0] "" Vector__XXX
 SG_ VCFRONT_fanRadFetShortCircuit m4 : 49|1@1+ (1,0) [0|0] "" Vector__XXX
 SG_ VCFRONT_activeDemandFanRad m0 : 48|7@1+ (1,0) [0|0] "" Vector__XXX
 SG_ VCFRONT_fanRadVglUnderVoltage m4 : 48|1@1+ (1,0) [0|0] "" Vector__XXX
 SG_ VCFRONT_passiveDemandLouver m3 : 48|7@1+ (1,0) [0|0] "" Vector__XXX
 SG_ VCFRONT_fanRadChpUnderVoltage m4 : 47|1@1+ (1,0) [0|0] "" Vector__XXX
 SG_ VCFRONT_fanRadVsOverVoltage m4 : 46|1@1+ (1,0) [0|0] "" Vector__XXX
 SG_ VCFRONT_fanRadVsUnderVoltage m4 : 45|1@1+ (1,0) [0|0] "" Vector__XXX
 SG_ VCFRONT_fanRadOverCurrentError m4 : 44|1@1+ (1,0) [0|0] "" Vector__XXX
 SG_ VCFRONT_pumpPtStatDiagFail m4 : 43|1@1+ (1,0) [0|0] "" Vector__XXX
 SG_ VCFRONT_pumpPtStatSPIFail m4 : 42|1@1+ (1,0) [0|0] "" Vector__XXX
 SG_ VCFRONT_activeDemandPumpBatt m0 : 41|7@1+ (1,0) [0|0] "" Vector__XXX
 SG_ VCFRONT_pumpPtStatOTPAny m4 : 41|1@1+ (1,0) [0|0] "" Vector__XXX
 SG_ VCFRONT_passiveDemandPumpBatt m3 : 40|7@1+ (1,0) [0|0] "" Vector__XXX
 SG_ VCFRONT_pumpPtStatMode m4 : 39|2@1+ (1,0) [0|0] "" Vector__XXX
 SG_ VCFRONT_pumpPtPwmInputFault m4 : 38|1@1+ (1,0) [0|0] "" Vector__XXX
 SG_ VCFRONT_pumpPtVccUnderVoltage m4 : 37|1@1+ (1,0) [0|0] "" Vector__XXX
 SG_ VCFRONT_pumpPtLossOfSpeedLock m4 : 36|1@1+ (1,0) [0|0] "" Vector__XXX
 SG_ VCFRONT_pumpPtStartUpOperation m4 : 35|1@1+ (1,0) [0|0] "" Vector__XXX
 SG_ VCFRONT_activeDemandPumpPT m0 : 34|7@1+ (1,0) [0|0] "" Vector__XXX
 SG_ VCFRONT_mdotRefLcc m6 : 34|10@1+ (0.1,0) [0|0] "" Vector__XXX
 SG_ VCFRONT_pumpPtWatchdogTimeout m4 : 34|1@1+ (1,0) [0|0] "" Vector__XXX
 SG_ VCFRONT_activeParallelBattRegOn m0 : 33|1@1+ (1,0) [0|0] "" Vector__XXX
 SG_ VCFRONT_pumpPtJunctionOverTemp m4 : 33|1@1+ (1,0) [0|0] "" Vector__XXX
 SG_ VCFRONT_activeParallelPTRegOn m0 : 32|1@1+ (1,0) [0|0] "" Vector__XXX
 SG_ VCFRONT_condenserMinLouverReq m5 : 32|7@1+ (1,0) [0|0] "" Vector__XXX
 SG_ VCFRONT_passiveDemandPumpPT m3 : 32|7@1+ (1,0) [0|0] "" Vector__XXX
 SG_ VCFRONT_pumpPtJunctionTempWarn m4 : 32|1@1+ (1,0) [0|0] "" Vector__XXX
 SG_ VCFRONT_superheatChiller m7 : 32|6@1+ (1,0) [0|0] "" Vector__XXX
 SG_ VCFRONT_activeSeriesRegOn m0 : 31|1@1+ (1,0) [0|0] "" Vector__XXX
 SG_ VCFRONT_pumpPtLockedRotor m4 : 31|1@1+ (1,0) [0|0] "" Vector__XXX
 SG_ VCFRONT_pumpPtThOverTemperature m4 : 30|1@1+ (1,0) [0|0] "" Vector__XXX
 SG_ VCFRONT_refrigLccTypeConfig m8 : 30|2@1+ (1,0) [0|0] "" Vector__XXX
 SG_ VCFRONT_pumpPtFetShortCircuit m4 : 29|1@1+ (1,0) [0|0] "" Vector__XXX
 SG_ VCFRONT_pumpPtVglUnderVoltage m4 : 28|1@1+ (1,0) [0|0] "" Vector__XXX
 SG_ VCFRONT_refrigFilterTypeConfig m8 : 28|2@1+ (1,0) [0|0] "" Vector__XXX
 SG_ VCFRONT_pumpPtChpUnderVoltage m4 : 27|1@1+ (1,0) [0|0] "" Vector__XXX
 SG_ VCFRONT_pumpPtVsOverVoltage m4 : 26|1@1+ (1,0) [0|0] "" Vector__XXX
 SG_ VCFRONT_passiveParallelPTRegMaxd m3 : 25|1@1+ (1,0) [0|0] "" Vector__XXX
 SG_ VCFRONT_pumpPtVsUnderVoltage m4 : 25|1@1+ (1,0) [0|0] "" Vector__XXX
 SG_ VCFRONT_activeParallelBattReg m0 : 24|7@1+ (1,0) [0|0] "" Vector__XXX
 SG_ VCFRONT_condenserMinFanReq m5 : 24|7@1+ (1,0) [0|0] "" Vector__XXX
 SG_ VCFRONT_mdotRefCabinCondenser m6 : 24|10@1+ (0.1,0) [0|0] "" Vector__XXX
 SG_ VCFRONT_passiveSeriesRegMaxd m3 : 24|1@1+ (1,0) [0|0] "" Vector__XXX
 SG_ VCFRONT_pumpPtOverCurrentError m4 : 24|1@1+ (1,0) [0|0] "" Vector__XXX
 SG_ VCFRONT_superheatEvap m7 : 24|6@1+ (1,0) [0|0] "" Vector__XXX
 SG_ VCFRONT_supermanifoldTypeConfig m8 : 24|4@1+ (1,0) [0|0] "" Vector__XXX
 SG_ VCFRONT_passiveParallelPTRegOn m3 : 23|1@1+ (1,0) [0|0] "" Vector__XXX
 SG_ VCFRONT_pumpBatStatDiagFail m4 : 23|1@1+ (1,0) [0|0] "" Vector__XXX
 SG_ VCFRONT_pumpBatStatSPIFail m4 : 22|1@1+ (1,0) [0|0] "" Vector__XXX
 SG_ VCFRONT_pumpBatStatOTPAny m4 : 21|1@1+ (1,0) [0|0] "" Vector__XXX
 SG_ VCFRONT_pumpPtPolePairConfig m8 : 20|4@1+ (1,0) [0|0] "" Vector__XXX
 SG_ VCFRONT_pumpBatStatMode m4 : 19|2@1+ (1,0) [0|0] "" Vector__XXX
 SG_ VCFRONT_pumpBatPwmInputFault m4 : 18|1@1+ (1,0) [0|0] "" Vector__XXX
 SG_ VCFRONT_burnInState m1 : 17|3@1+ (1,0) [0|0] "" Vector__XXX
 SG_ VCFRONT_condenserRegDemand m5 : 17|7@1+ (1,0) [0|0] "" Vector__XXX
 SG_ VCFRONT_pumpBatVccUnderVoltage m4 : 17|1@1+ (1,0) [0|0] "" Vector__XXX
 SG_ VCFRONT_activeLouverBrakeEngaged m1 : 16|1@1+ (1,0) [0|0] "" Vector__XXX
 SG_ VCFRONT_activeParallelPTReg m0 : 16|7@1+ (1,0) [0|0] "" Vector__XXX
 SG_ VCFRONT_condenserFeedfwdForEvap m5 : 16|1@1+ (1,0) [0|0] "" Vector__XXX
 SG_ VCFRONT_passiveParallelPTReg m3 : 16|7@1+ (1,0) [0|0] "" Vector__XXX
 SG_ VCFRONT_pumpBatLossOfSpeedLock m4 : 16|1@1+ (1,0) [0|0] "" Vector__XXX
 SG_ VCFRONT_pumpBattPolePairConfig m8 : 16|4@1+ (1,0) [0|0] "" Vector__XXX
 SG_ VCFRONT_subcoolLcc m7 : 16|6@1+ (1,0) [0|0] "" Vector__XXX
 SG_ VCFRONT_activeLouverDirection m1 : 15|1@1+ (1,0) [0|0] "" Vector__XXX
 SG_ VCFRONT_condenserFeedfwdForChill m5 : 15|1@1+ (1,0) [0|0] "" Vector__XXX
 SG_ VCFRONT_pumpBatStartUpOperation m4 : 15|1@1+ (1,0) [0|0] "" Vector__XXX
 SG_ VCFRONT_condenserActivePID m5 : 14|1@1+ (1,0) [0|0] "" Vector__XXX
 SG_ VCFRONT_mdotRefChiller m6 : 14|10@1+ (0.1,0) [0|0] "" Vector__XXX
 SG_ VCFRONT_pumpBatWatchdogTimeout m4 : 14|1@1+ (1,0) [0|0] "" Vector__XXX
 SG_ VCFRONT_pumpBatJunctionOverTemp m4 : 13|1@1+ (1,0) [0|0] "" Vector__XXX
 SG_ VCFRONT_compressorTypeConfig m8 : 12|4@1+ (1,0) [0|0] "" Vector__XXX
 SG_ VCFRONT_pumpBatJunctionTempWarn m4 : 12|1@1+ (1,0) [0|0] "" Vector__XXX
 SG_ VCFRONT_copEvapActiveSinceLastDr m2 : 11|1@1+ (1,0) [0|0] "" Vector__XXX
 SG_ VCFRONT_pumpBatLockedRotor m4 : 11|1@1+ (1,0) [0|0] "" Vector__XXX
 SG_ VCFRONT_modeCop1Attainable m2 : 10|1@1+ (1,0) [0|0] "" Vector__XXX
 SG_ VCFRONT_pumpBatThOverTemperature m4 : 10|1@1+ (1,0) [0|0] "" Vector__XXX
 SG_ VCFRONT_modeAmbientSourceAttaina m2 : 9|1@1+ (1,0) [0|0] "" Vector__XXX
 SG_ VCFRONT_pumpBatFetShortCircuit m4 : 9|1@1+ (1,0) [0|0] "" Vector__XXX
 SG_ VCFRONT_activeLouverSpeedCmd m1 : 8|7@1+ (1,0) [0|0] "" Vector__XXX
 SG_ VCFRONT_activeSeriesReg m0 : 8|7@1+ (1,0) [0|0] "" Vector__XXX
 SG_ VCFRONT_condenserTempLimit m5 : 8|6@1+ (1,80) [0|0] "" Vector__XXX
 SG_ VCFRONT_modeParallelAttainable m2 : 8|1@1+ (1,0) [0|0] "" Vector__XXX
 SG_ VCFRONT_passiveSeriesReg m3 : 8|8@1- (1,0) [0|0] "" Vector__XXX
 SG_ VCFRONT_pumpBatVglUnderVoltage m4 : 8|1@1+ (1,0) [0|0] "" Vector__XXX
 SG_ VCFRONT_refrigerantTypeConfig m8 : 8|4@1+ (1,0) [0|0] "" Vector__XXX
 SG_ VCFRONT_subcoolCabinCondenser m7 : 8|6@1+ (1,0) [0|0] "" Vector__XXX
 SG_ VCFRONT_modeSeriesAttainable m2 : 7|1@1+ (1,0) [0|0] "" Vector__XXX
 SG_ VCFRONT_pumpBatChpUnderVoltage m4 : 7|1@1+ (1,0) [0|0] "" Vector__XXX
 SG_ VCFRONT_modeHysteresisActive m2 : 6|1@1+ (1,0) [0|0] "" Vector__XXX
 SG_ VCFRONT_pumpBatVsOverVoltage m4 : 6|1@1+ (1,0) [0|0] "" Vector__XXX
 SG_ VCFRONT_pumpBatVsUnderVoltage m4 : 5|1@1+ (1,0) [0|0] "" Vector__XXX
 SG_ VCFRONT_coolantPumpTypeConfig m8 : 4|4@1+ (1,0) [0|0] "" Vector__XXX
 SG_ VCFRONT_mdotRefEvap m6 : 4|10@1+ (0.1,0) [0|0] "" Vector__XXX
 SG_ VCFRONT_modeDesiredPrevious m2 : 4|2@1+ (1,0) [0|0] "" Vector__XXX
 SG_ VCFRONT_pumpBatOverCurrentError m4 : 4|1@1+ (1,0) [0|0] "" Vector__XXX
 SG_ VCFRONT_debugThermal1HzIndex M : 0|4@1+ (1,0) [0|0] "" Vector__XXX

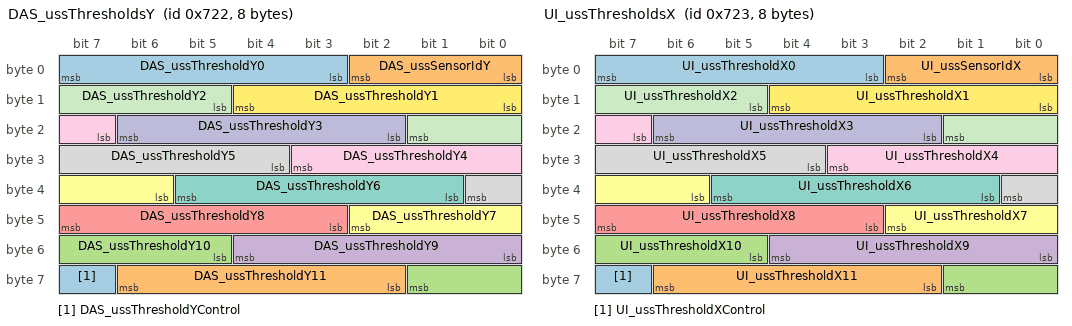
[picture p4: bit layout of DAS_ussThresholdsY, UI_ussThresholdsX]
BO_ 1826 DAS_ussThresholdsY: 8 Vector__XXX
 SG_ DAS_ussThresholdYControl : 63|1@1+ (1,0) [0|0] "" Vector__XXX
 SG_ DAS_ussThresholdY11 : 58|5@1+ (1,0) [0|0] "" Vector__XXX
 SG_ DAS_ussThresholdY10 : 53|5@1+ (1,0) [0|0] "" Vector__XXX
 SG_ DAS_ussThresholdY9 : 48|5@1+ (1,0) [0|0] "" Vector__XXX
 SG_ DAS_ussThresholdY8 : 43|5@1+ (1,0) [0|0] "" Vector__XXX
 SG_ DAS_ussThresholdY7 : 38|5@1+ (1,0) [0|0] "" Vector__XXX
 SG_ DAS_ussThresholdY6 : 33|5@1+ (1,0) [0|0] "" Vector__XXX
 SG_ DAS_ussThresholdY5 : 28|5@1+ (1,0) [0|0] "" Vector__XXX
 SG_ DAS_ussThresholdY4 : 23|5@1+ (1,0) [0|0] "" Vector__XXX
 SG_ DAS_ussThresholdY3 : 18|5@1+ (1,0) [0|0] "" Vector__XXX
 SG_ DAS_ussThresholdY2 : 13|5@1+ (1,0) [0|0] "" Vector__XXX
 SG_ DAS_ussThresholdY1 : 8|5@1+ (1,0) [0|0] "" Vector__XXX
 SG_ DAS_ussThresholdY0 : 3|5@1+ (1,0) [0|0] "" Vector__XXX
 SG_ DAS_ussSensorIdY : 0|3@1+ (1,0) [0|0] "" Vector__XXX

BO_ 1827 UI_ussThresholdsX: 8 Vector__XXX
 SG_ UI_ussThresholdXControl : 63|1@1+ (1,0) [0|0] "" Vector__XXX
 SG_ UI_ussThresholdX11 : 58|5@1+ (1,0) [0|0] "" Vector__XXX
 SG_ UI_ussThresholdX10 : 53|5@1+ (1,0) [0|0] "" Vector__XXX
 SG_ UI_ussThresholdX9 : 48|5@1+ (1,0) [0|0] "" Vector__XXX
 SG_ UI_ussThresholdX8 : 43|5@1+ (1,0) [0|0] "" Vector__XXX
 SG_ UI_ussThresholdX7 : 38|5@1+ (1,0) [0|0] "" Vector__XXX
 SG_ UI_ussThresholdX6 : 33|5@1+ (1,0) [0|0] "" Vector__XXX
 SG_ UI_ussThresholdX5 : 28|5@1+ (1,0) [0|0] "" Vector__XXX
 SG_ UI_ussThresholdX4 : 23|5@1+ (1,0) [0|0] "" Vector__XXX
 SG_ UI_ussThresholdX3 : 18|5@1+ (1,0) [0|0] "" Vector__XXX
 SG_ UI_ussThresholdX2 : 13|5@1+ (1,0) [0|0] "" Vector__XXX
 SG_ UI_ussThresholdX1 : 8|5@1+ (1,0) [0|0] "" Vector__XXX
 SG_ UI_ussThresholdX0 : 3|5@1+ (1,0) [0|0] "" Vector__XXX
 SG_ UI_ussSensorIdX : 0|3@1+ (1,0) [0|0] "" Vector__XXX

BO_ 1828 VCFRONT_loadShedDebugStatus: 3 Vector__XXX
 SG_ VCFRONT_loadShedStsBatteryPump_duty m1 : 16|7@1+ (1,0) [0|0] "" Vector__XXX
 SG_ VCFRONT_loadShedStsCondenserFan_duty m2 : 16|7@1+ (1,0) [0|0] "" Vector__XXX
 SG_ VCFRONT_loadShedStsPTPump_duty m3 : 16|7@1+ (1,0) [0|0] "" Vector__XXX
 SG_ VCFRONT_loadShedReasonAPHeater m0 : 4|9@1+ (1,0) [0|0] "" Vector__XXX
 SG_ VCFRONT_loadShedReasonAutopilot m5 : 4|9@1+ (1,0) [0|0] "" Vector__XXX
 SG_ VCFRONT_loadShedReasonBatteryPump m1 : 4|9@1+ (1,0) [0|0] "" Vector__XXX
 SG_ VCFRONT_loadShedReasonCondenserFan m2 : 4|9@1+ (1,0) [0|0] "" Vector__XXX
 SG_ VCFRONT_loadShedReasonMCUAudio m8 : 4|9@1+ (1,0) [0|0] "" Vector__XXX
 SG_ VCFRONT_loadShedReasonMCUGraphic m7 : 4|9@1+ (1,0) [0|0] "" Vector__XXX
 SG_ VCFRONT_loadShedReasonPCS m9 : 4|9@1+ (1,0) [0|0] "" Vector__XXX
 SG_ VCFRONT_loadShedReasonPTPump m3 : 4|9@1+ (1,0) [0|0] "" Vector__XXX
 SG_ VCFRONT_loadShedReasonTAS m4 : 4|9@1+ (1,0) [0|0] "" Vector__XXX
 SG_ VCFRONT_loadShedReasonUI m6 : 4|9@1+ (1,0) [0|0] "" Vector__XXX
 SG_ VCFRONT_loadShedDebugStatusIndex M : 0|4@1+ (1,0) [0|0] "" Vector__XXX

BO_ 1829 VCBATT2_loadShedDebugStatus: 8 Vector__XXX
 SG_ VCBATT2_loadShedStsBatteryPump_d m1 : 16|7@1+ (1,0) [0|0] "" Vector__XXX
 SG_ VCBATT2_loadShedStsCondenserFan_ m2 : 16|7@1+ (1,0) [0|0] "" Vector__XXX
 SG_ VCBATT2_loadShedStsPTPump_duty m3 : 16|7@1+ (1,0) [0|0] "" Vector__XXX
 SG_ VCBATT2_loadShedReasonAPHeater m0 : 4|9@1+ (1,0) [0|0] "" Vector__XXX
 SG_ VCBATT2_loadShedReasonAutopilot m5 : 4|9@1+ (1,0) [0|0] "" Vector__XXX
 SG_ VCBATT2_loadShedReasonBatteryPum m1 : 4|9@1+ (1,0) [0|0] "" Vector__XXX
 SG_ VCBATT2_loadShedReasonCondenserF m2 : 4|9@1+ (1,0) [0|0] "" Vector__XXX
 SG_ VCBATT2_loadShedReasonMCUAudio m8 : 4|9@1+ (1,0) [0|0] "" Vector__XXX
 SG_ VCBATT2_loadShedReasonMCUGraphic m7 : 4|9@1+ (1,0) [0|0] "" Vector__XXX
 SG_ VCBATT2_loadShedReasonPCS m9 : 4|9@1+ (1,0) [0|0] "" Vector__XXX
 SG_ VCBATT2_loadShedReasonPTPump m3 : 4|9@1+ (1,0) [0|0] "" Vector__XXX
 SG_ VCBATT2_loadShedReasonTAS m4 : 4|9@1+ (1,0) [0|0] "" Vector__XXX
 SG_ VCBATT2_loadShedReasonUI m6 : 4|9@1+ (1,0) [0|0] "" Vector__XXX
 SG_ VCBATT2_loadShedDebugStatusIndex M : 0|4@1+ (1,0) [0|0] "" Vector__XXX

BO_ 1830 VCLEFT_loadShedDebugStatus: 3 Vector__XXX
 SG_ VCLEFT_loadShedStsHVACBlower_duty m1 : 16|7@1+ (1,0) [0|0] "" Vector__XXX
 SG_ VCLEFT_loadShedReason12VAuxLoads m0 : 8|7@1+ (1,0) [0|0] "" Vector__XXX
 SG_ VCLEFT_loadShedReasonHVACBlower m1 : 8|7@1+ (1,0) [0|0] "" Vector__XXX
 SG_ VCLEFT_loadShedReasonLiftgate m2 : 8|7@1+ (1,0) [0|0] "" Vector__XXX
 SG_ VCLEFT_loadShedReasonMirrorHeater m3 : 8|7@1+ (1,0) [0|0] "" Vector__XXX
 SG_ VCLEFT_loadShedReasonMotorEncoders m4 : 8|7@1+ (1,0) [0|0] "" Vector__XXX
 SG_ VCLEFT_loadShedReasonSTWInOut m10 : 8|7@1+ (1,0) [0|0] "" Vector__XXX
 SG_ VCLEFT_loadShedReasonSTWUpDown m11 : 8|7@1+ (1,0) [0|0] "" Vector__XXX
 SG_ VCLEFT_loadShedReasonSeatBackrest m5 : 8|7@1+ (1,0) [0|0] "" Vector__XXX
 SG_ VCLEFT_loadShedReasonSeatHeaters m7 : 8|7@1+ (1,0) [0|0] "" Vector__XXX
 SG_ VCLEFT_loadShedReasonSeatLift m6 : 8|7@1+ (1,0) [0|0] "" Vector__XXX
 SG_ VCLEFT_loadShedReasonSeatTilt m8 : 8|7@1+ (1,0) [0|0] "" Vector__XXX
 SG_ VCLEFT_loadShedReasonSeatTrack m9 : 8|7@1+ (1,0) [0|0] "" Vector__XXX
 SG_ VCLEFT_loadShedReasonUSBPorts m12 : 8|7@1+ (1,0) [0|0] "" Vector__XXX
 SG_ VCLEFT_loadShedReasonWindowMotorsFront m13 : 8|7@1+ (1,0) [0|0] "" Vector__XXX
 SG_ VCLEFT_loadShedReasonWindowMotorsRear m14 : 8|7@1+ (1,0) [0|0] "" Vector__XXX
 SG_ VCLEFT_loadShedDebugStatusIndex M : 0|4@1+ (1,0) [0|0] "" Vector__XXX

BO_ 1831 VCRIGHT_loadShedDebugStatus: 2 Vector__XXX
 SG_ VCRIGHT_loadShedReasonMirrorHeater m0 : 8|7@1+ (1,0) [0|0] "" Vector__XXX
 SG_ VCRIGHT_loadShedReasonMotorEncoders m1 : 8|7@1+ (1,0) [0|0] "" Vector__XXX
 SG_ VCRIGHT_loadShedReasonPremAudio m2 : 8|7@1+ (1,0) [0|0] "" Vector__XXX
 SG_ VCRIGHT_loadShedReasonRearDefroster m3 : 8|7@1+ (1,0) [0|0] "" Vector__XXX
 SG_ VCRIGHT_loadShedReasonSeatBackrest m4 : 8|7@1+ (1,0) [0|0] "" Vector__XXX
 SG_ VCRIGHT_loadShedReasonSeatHeaters m5 : 8|7@1+ (1,0) [0|0] "" Vector__XXX
 SG_ VCRIGHT_loadShedReasonSeatLift m6 : 8|7@1+ (1,0) [0|0] "" Vector__XXX
 SG_ VCRIGHT_loadShedReasonSeatTilt m7 : 8|7@1+ (1,0) [0|0] "" Vector__XXX
 SG_ VCRIGHT_loadShedReasonSeatTrack m8 : 8|7@1+ (1,0) [0|0] "" Vector__XXX
 SG_ VCRIGHT_loadShedReasonUSBPorts m9 : 8|7@1+ (1,0) [0|0] "" Vector__XXX
 SG_ VCRIGHT_loadShedReasonWindowMotorsFront m10 : 8|7@1+ (1,0) [0|0] "" Vector__XXX
 SG_ VCRIGHT_loadShedReasonWindowMotorsRear m11 : 8|7@1+ (1,0) [0|0] "" Vector__XXX
 SG_ VCRIGHT_loadShedDebugStatusIndex M : 0|4@1+ (1,0) [0|0] "" Vector__XXX

BO_ 1833 DBG_IsotermSMS: 12 Vector__XXX
 SG_ DBG_IsotermSMS : 7|64@0+ (1,0) [0|0] "" Vector__XXX

BO_ 1834 BMS_serialNumber: 8 Vector__XXX
 SG_ BMS_packSerialNumberByte07 m0 : 56|8@1+ (1,0) [0|0] "" Vector__XXX
 SG_ BMS_packSerialNumberByte14 m1 : 56|8@1+ (1,0) [0|0] "" Vector__XXX
 SG_ BMS_packSerialNumberByte06 m0 : 48|8@1+ (1,0) [0|0] "" Vector__XXX
 SG_ BMS_packSerialNumberByte13 m1 : 48|8@1+ (1,0) [0|0] "" Vector__XXX
 SG_ BMS_packSerialNumberByte05 m0 : 40|8@1+ (1,0) [0|0] "" Vector__XXX
 SG_ BMS_packSerialNumberByte12 m1 : 40|8@1+ (1,0) [0|0] "" Vector__XXX
 SG_ BMS_packSerialNumberByte04 m0 : 32|8@1+ (1,0) [0|0] "" Vector__XXX
 SG_ BMS_packSerialNumberByte11 m1 : 32|8@1+ (1,0) [0|0] "" Vector__XXX
 SG_ BMS_packSerialNumberByte03 m0 : 24|8@1+ (1,0) [0|0] "" Vector__XXX
 SG_ BMS_packSerialNumberByte10 m1 : 24|8@1+ (1,0) [0|0] "" Vector__XXX
 SG_ BMS_packSerialNumberByte02 m0 : 16|8@1+ (1,0) [0|0] "" Vector__XXX
 SG_ BMS_packSerialNumberByte09 m1 : 16|8@1+ (1,0) [0|0] "" Vector__XXX
 SG_ BMS_packSerialBirthDateBinned m2 : 8|32@1+ (1,0) [0|0] "" Vector__XXX
 SG_ BMS_packSerialNumberByte01 m0 : 8|8@1+ (1,0) [0|0] "" Vector__XXX
 SG_ BMS_packSerialNumberByte08 m1 : 8|8@1+ (1,0) [0|0] "" Vector__XXX
 SG_ BMS_serialNumberMultiplexer M : 0|2@1+ (1,0) [0|0] "" Vector__XXX

BO_ 1835 XCP_tasRequest: 12 Vector__XXX
 SG_ XCP_tasRequest : 7|64@0+ (1,0) [0|0] "" Vector__XXX

BO_ 1840 UDS_epas3sRequest: 12 Vector__XXX
 SG_ UDS_epas3sRequestData : 7|64@0+ (1,0) [0|0] "" Vector__XXX

BO_ 1842 XCP_bmsRequest: 12 Vector__XXX
 SG_ XCP_bmsRequestData : 7|64@0+ (1,0) [0|0] "" Vector__XXX

BO_ 1847 VCFRONT_LVBMS_info: 7 Vector__XXX
 SG_ VCFRONT_LVBMS_mfgYear m4 : 48|7@1+ (1,2011) [0|0] "" Vector__XXX
 SG_ VCFRONT_LVBMS_SubUsageId m0 : 40|16@1+ (1,0) [0|0] "" Vector__XXX
 SG_ VCFRONT_LVBMS_mfgMonth m4 : 40|4@1+ (1,0) [0|0] "" Vector__XXX
 SG_ VCFRONT_LVBMS_mfgDay m4 : 32|5@1+ (1,0) [0|0] "" Vector__XXX
 SG_ VCFRONT_LVBMS_AppCRC m1 : 24|32@1+ (1,0) [0|0] "" Vector__XXX
 SG_ VCFRONT_LVBMS_AssemblyId m0 : 24|16@1+ (1,0) [0|0] "" Vector__XXX
 SG_ VCFRONT_LVBMS_FWBuildType m3 : 8|8@1+ (1,0) [0|0] "" Vector__XXX
 SG_ VCFRONT_LVBMS_GitHash m2 : 8|16@1+ (1,0) [0|0] "" Vector__XXX
 SG_ VCFRONT_LVBMS_PcbaId m0 : 8|16@1+ (1,0) [0|0] "" Vector__XXX
 SG_ VCFRONT_LVBMS_UsageId m1 : 8|16@1+ (1,0) [0|0] "" Vector__XXX
 SG_ VCFRONT_LVBMS_serialNumber m4 : 8|24@1+ (1,0) [0|0] "" Vector__XXX
 SG_ VCFRONT_LVBMS_InfoIndex M : 0|8@1+ (1,0) [0|0] "" Vector__XXX

BO_ 1848 EPAS3S_udsResponse: 12 Vector__XXX
 SG_ EPAS3S_udsResponseData : 7|64@0+ (1,0) [0|0] "" Vector__XXX

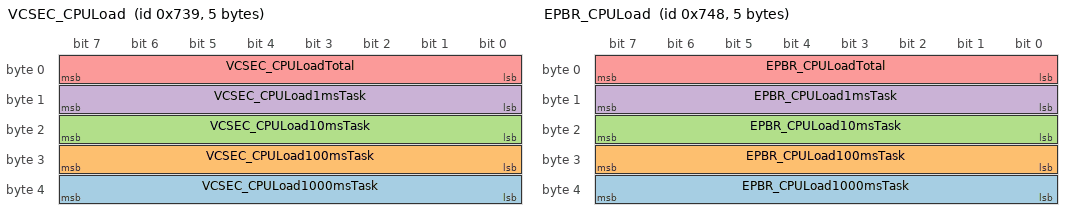
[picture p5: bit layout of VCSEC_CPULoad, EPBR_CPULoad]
BO_ 1849 VCSEC_CPULoad: 5 Vector__XXX
 SG_ VCSEC_CPULoad1000msTask : 32|8@1+ (1,0) [0|0] "" Vector__XXX
 SG_ VCSEC_CPULoad100msTask : 24|8@1+ (1,0) [0|0] "" Vector__XXX
 SG_ VCSEC_CPULoad10msTask : 16|8@1+ (1,0) [0|0] "" Vector__XXX
 SG_ VCSEC_CPULoad1msTask : 8|8@1+ (1,0) [0|0] "" Vector__XXX
 SG_ VCSEC_CPULoadTotal : 0|8@1+ (1,0) [0|0] "" Vector__XXX

BO_ 1850 VC_LVBMS_brickMeasurements: 8 Vector__XXX
 SG_ VC_LVBMS_brickBalancingState2 m1 : 57|1@1+ (1,0) [0|0] "" Vector__XXX
 SG_ VC_LVBMS_brickBalancingState4 m2 : 57|1@1+ (1,0) [0|0] "" Vector__XXX
 SG_ VC_LVBMS_brickBalancingState1 m1 : 56|1@1+ (1,0) [0|0] "" Vector__XXX
 SG_ VC_LVBMS_brickBalancingState3 m2 : 56|1@1+ (1,0) [0|0] "" Vector__XXX
 SG_ VC_LVBMS_brickVoltage4 m0 : 50|13@1+ (0.001,0) [0|0] "" Vector__XXX
 SG_ VC_LVBMS_brickVoltage3 m0 : 37|13@1+ (0.001,0) [0|0] "" Vector__XXX
 SG_ VC_LVBMS_brickBalancingAh2 m1 : 32|24@1+ (0.001,0) [0|0] "" Vector__XXX
 SG_ VC_LVBMS_brickBalancingAh4 m2 : 32|24@1+ (0.001,0) [0|0] "" Vector__XXX
 SG_ VC_LVBMS_brickVoltage2 m0 : 24|13@1+ (0.001,0) [0|0] "" Vector__XXX
 SG_ VC_LVBMS_brickBalancingAh1 m1 : 8|24@1+ (0.001,0) [0|0] "" Vector__XXX
 SG_ VC_LVBMS_brickBalancingAh3 m2 : 8|24@1+ (0.001,0) [0|0] "" Vector__XXX
 SG_ VC_LVBMS_brickVoltage1 m0 : 8|13@1+ (0.001,0) [0|0] "" Vector__XXX
 SG_ VC_LVBMS_brickMeasurementsMultiplexer M : 0|6@1+ (1,0) [0|0] "" Vector__XXX

BO_ 1851 TAS_xcpResponse: 12 Vector__XXX
 SG_ TAS_xcpResponse : 7|64@0+ (1,0) [0|0] "" Vector__XXX

BO_ 1853 SDCR_debug: 8 Vector__XXX
 SG_ SDCR_accumulatedSampleTime m1 : 52|12@1+ (0.1,0) [0|0] "" Vector__XXX
 SG_ SDCR_cpuUsageISR m4 : 44|10@1+ (0.1,0) [0|0] "" Vector__XXX
 SG_ SDCR_maxSampleTime m1 : 40|12@1+ (0.1,0) [0|0] "" Vector__XXX
 SG_ SDCR_cpuUsage100MS m4 : 34|10@1+ (0.1,0) [0|0] "" Vector__XXX
 SG_ SDCR_vPhaseC m2 : 28|12@1+ (0.4,0) [0|0] "" Vector__XXX
 SG_ SDCR_cpuUsage10MS m4 : 24|10@1+ (0.1,0) [0|0] "" Vector__XXX
 SG_ SDCR_lastMaxAbsSpeed m1 : 24|16@1- (0.1,0) [0|0] "" Vector__XXX
 SG_ SDCR_magI2 m0 : 24|16@1+ (34.33279926756695,0) [0|0] "" Vector__XXX
 SG_ SDCR_busBarTempA m3 : 16|8@1+ (1,-40) [0|0] "" Vector__XXX
 SG_ SDCR_vPhaseB m2 : 16|12@1+ (0.4,0) [0|0] "" Vector__XXX
 SG_ SDCR_vref m0 : 16|8@1+ (0.02,0) [0|0] "" Vector__XXX
 SG_ SDCR_cpuUsage1MS m4 : 13|10@1+ (0.1,0) [0|0] "" Vector__XXX
 SG_ SDCR_busBarTempC m3 : 8|8@1+ (1,-40) [0|0] "" Vector__XXX
 SG_ SDCR_elcSpeed m1 : 8|16@1- (0.1,0) [0|0] "" Vector__XXX
 SG_ SDCR_pyroSenseV m0 : 8|8@1+ (0.02,0) [0|0] "" Vector__XXX
 SG_ SDCR_cpuUsageCumulative m4 : 3|10@1+ (0.1,0) [0|0] "" Vector__XXX
 SG_ SDCR_vPhaseA m2 : 3|12@1+ (0.4,0) [0|0] "" Vector__XXX
 SG_ SDCR_debugOutputIndex M : 0|3@1+ (1,0) [0|0] "" Vector__XXX

BO_ 1854 GB_vehLogData: 8 Vector__XXX
 SG_ VEH_GB_BAT_Max_V_BRM m1 : 48|16@1+ (0.1,0) [0|0] "" Vector__XXX
 SG_ VEH_GB_Rem_Chg_Time_Mins m6 : 48|16@1+ (1,0) [0|0] "" Vector__XXX
 SG_ VEH_chargeCurrent_exp_log m13 : 43|3@1- (1,0) [0|0] "" Vector__XXX
 SG_ VEH_GB_BAT_V m3 : 40|16@1+ (0.1,0) [0|0] "" Vector__XXX
 SG_ VEH_GB_SOC m6 : 40|8@1+ (1,0) [0|0] "" Vector__XXX
 SG_ VEH_currentDemand_exp_log m13 : 40|3@1- (1,0) [0|0] "" Vector__XXX
 SG_ VEH_GB_BAT_Cap_Ah m1 : 32|16@1+ (0.1,0) [0|0] "" Vector__XXX
 SG_ VEH_GB_Chg_Stop_Rsn_Param_Mismat m9 : 32|2@1+ (1,0) [0|0] "" Vector__XXX
 SG_ VEH_GB_Chg_Stop_Rsn_V_ERR m9 : 30|2@1+ (1,0) [0|0] "" Vector__XXX
 SG_ VEH_GB_Chg_Stop_Rsn_OC_ERR m9 : 28|2@1+ (1,0) [0|0] "" Vector__XXX
 SG_ VEH_GB_Chg_Stop_Rsn_Other_FLT m9 : 26|2@1+ (1,0) [0|0] "" Vector__XXX
 SG_ VEH_GB_BAT_SOC m3 : 24|16@1+ (0.1,0) [0|0] "" Vector__XXX
 SG_ VEH_GB_Chg_Stop_Rsn_VPt2_FLT m9 : 24|2@1+ (1,0) [0|0] "" Vector__XXX
 SG_ VEH_GB_Meas_I m6 : 24|16@1+ (0.1,-400) [0|0] "" Vector__XXX
 SG_ VEH_chargeCurrent_value_log m13 : 24|16@1- (1,0) [0|0] "" Vector__XXX
 SG_ VEH_GB_Chg_Stop_Rsn_HVRelay_FLT m9 : 22|2@1+ (1,0) [0|0] "" Vector__XXX
 SG_ VEH_GB_Chg_Stop_Rsn_Pack_OT_FLT m9 : 20|2@1+ (1,0) [0|0] "" Vector__XXX
 SG_ VEH_GB_Chg_Other_Tmt m11 : 18|6@1+ (1,0) [0|0] "" Vector__XXX
 SG_ VEH_GB_Chg_Stop_Rsn_Conn_FLT m9 : 18|2@1+ (1,0) [0|0] "" Vector__XXX
 SG_ VEH_GB_Chg_Statistics_Tmt m11 : 16|2@1+ (1,0) [0|0] "" Vector__XXX
 SG_ VEH_GB_Chg_Stop_Rsn_BMS_OT_FLT m9 : 16|2@1+ (1,0) [0|0] "" Vector__XXX
 SG_ VEH_GB_Chg_Stop_Rsn_Conn_OT_FLT m9 : 14|2@1+ (1,0) [0|0] "" Vector__XXX
 SG_ VEH_GB_Chg_Stop_Tmt m11 : 14|2@1+ (1,0) [0|0] "" Vector__XXX
 SG_ VEH_GB_Chg_Status_Tmt m11 : 12|2@1+ (1,0) [0|0] "" Vector__XXX
 SG_ VEH_GB_Chg_Stop_Rsn_Insul_Fault m9 : 12|2@1+ (1,0) [0|0] "" Vector__XXX
 SG_ VEH_GB_CHG_Readiness_Tmt m11 : 10|2@1+ (1,0) [0|0] "" Vector__XXX
 SG_ VEH_GB_Chg_Stop_Rsn_CST m9 : 10|2@1+ (1,0) [0|0] "" Vector__XXX
 SG_ VEH_GB_BAT_Max_V_BHM m0 : 8|16@1+ (0.1,0) [0|0] "" Vector__XXX
 SG_ VEH_GB_BAT_Mfr_Name m2 : 8|32@1+ (1,0) [0|0] "" Vector__XXX
 SG_ VEH_GB_Chg_Max_I m3 : 8|16@1+ (0.1,-400) [0|0] "" Vector__XXX
 SG_ VEH_GB_Chg_Max_Output_Tmt m11 : 8|2@1+ (1,0) [0|0] "" Vector__XXX
 SG_ VEH_GB_Chg_Stop_Rsn_Cell_V m9 : 8|2@1+ (1,0) [0|0] "" Vector__XXX
 SG_ VEH_GB_Current_Demand m5 : 8|16@1+ (0.1,-400) [0|0] "" Vector__XXX
 SG_ VEH_GB_Final_SOC m10 : 8|8@1+ (1,0) [0|0] "" Vector__XXX
 SG_ VEH_GB_Meas_V m6 : 8|16@1+ (0.1,0) [0|0] "" Vector__XXX
 SG_ VEH_GB_Protocol_Ver_log m1 : 8|24@1+ (1,0) [0|0] "" Vector__XXX
 SG_ VEH_GB_Status m4 : 8|8@1+ (1,0) [0|0] "" Vector__XXX
 SG_ VEH_currentDemand_value_log m13 : 8|16@1- (1,0) [0|0] "" Vector__XXX
 SG_ VEH_teslaGbProtocolVersion_log m12 : 8|8@1+ (1,0) [0|0] "" Vector__XXX
 SG_ VEH_GB_Chg_ID_AA_Tmt m11 : 6|2@1+ (1,0) [0|0] "" Vector__XXX
 SG_ VEH_GB_Chg_Stop_Rsn_Pack_V m9 : 6|2@1+ (1,0) [0|0] "" Vector__XXX
 SG_ VEH_GB_Chg_Allowed m7 : 4|1@1+ (1,0) [0|0] "" Vector__XXX
 SG_ VEH_GB_Chg_ID_00_Tmt m11 : 4|2@1+ (1,0) [0|0] "" Vector__XXX
 SG_ VEH_GB_Chg_Stop_Rsn_SOC m9 : 4|2@1+ (1,0) [0|0] "" Vector__XXX
 SG_ VEH_GB_kwhChargeTotal_sent m8 : 4|1@1+ (1,0) [0|0] "" Vector__XXX
 SG_ VEH_teslaVin_muxSent m14 : 4|2@1+ (1,0) [0|0] "" Vector__XXX
 SG_ GB_vehLogDataSelect M : 0|4@1+ (1,0) [0|0] "" Vector__XXX

BO_ 1856 TPMS_sensorIDs: 8 Vector__XXX
 SG_ TPMS_sensorIDRR m1 : 32|32@1+ (1,0) [0|0] "" Vector__XXX
 SG_ TPMS_sensorIDRL m3 : 32|32@1+ (1,0) [0|0] "" Vector__XXX
 SG_ TPMS_sensorIDFR m2 : 32|32@1+ (1,0) [0|0] "" Vector__XXX
 SG_ TPMS_sensorIDFL m0 : 32|32@1+ (1,0) [0|0] "" Vector__XXX
 SG_ TPMS_sensorIDIndex M : 0|8@1+ (1,0) [0|0] "" Vector__XXX

BO_ 1858 VCBATT1_LVBMS_statusHigh: 8 Vector__XXX
 SG_ VCBATT1_LVBMS_minBrickVoltageIndex m4 : 56|8@1+ (1,0) [0|0] "" Vector__XXX
 SG_ VCBATT1_LVBMS_MOSTemperature m0 : 50|12@1+ (0.5,-50) [0|0] "" Vector__XXX
 SG_ VCBATT1_LVBMS_maxAllowedDischargeCurrent m3 : 50|13@1+ (0.1,0) [0|0] "" Vector__XXX
 SG_ VCBATT1_LVBMS_estimatedPackOcv m2 : 48|16@1+ (0.001,0) [0|0] "" Vector__XXX
 SG_ VCBATT1_LVBMS_packTemperature m0 : 41|9@1+ (0.5,-50) [0|0] "" Vector__XXX
 SG_ VCBATT1_LVBMS_maxBrickVoltageIndex m1 : 40|8@1+ (1,0) [0|0] "" Vector__XXX
 SG_ VCBATT1_LVBMS_minBrickVoltage m4 : 40|13@1+ (0.001,0) [0|0] "" Vector__XXX
 SG_ VCBATT1_LVBMS_maxAllowedChargeCurrent m3 : 37|13@1+ (0.1,0) [0|0] "" Vector__XXX
 SG_ VCBATT1_LVPackCurrent m2 : 34|14@1- (0.1,0) [0|0] "" Vector__XXX
 SG_ VCBATT1_LVBMS_packVoltage m0 : 25|16@1+ (0.001,0) [0|0] "" Vector__XXX
 SG_ VCBATT1_LVBMS_avgBrickVoltage m4 : 24|13@1+ (0.001,0) [0|0] "" Vector__XXX
 SG_ VCBATT1_LVBMS_maxBrickVoltage m1 : 24|13@1+ (0.001,0) [0|0] "" Vector__XXX
 SG_ VCBATT1_LVPackChargeCurrentLimit m2 : 22|12@1+ (0.1,0) [0|0] "" Vector__XXX
 SG_ VCBATT1_LVBMS_cellAndArcProtEnabled m4 : 19|1@1+ (1,0) [0|0] "" Vector__XXX
 SG_ VCBATT1_LVBMS_currentTarget m3 : 19|18@1+ (0.001,-122) [0|0] "" Vector__XXX
 SG_ VCBATT1_LVBMS_chargeType m4 : 16|3@1+ (1,0) [0|0] "" Vector__XXX
 SG_ VCBATT1_LVBMS_LINWakeDisabled m4 : 14|1@1+ (1,0) [0|0] "" Vector__XXX
 SG_ VCBATT1_LVBMS_VehicleState m4 : 12|2@1+ (1,0) [0|0] "" Vector__XXX
 SG_ VCBATT1_LVBMS_MOSState m4 : 10|2@1+ (1,0) [0|0] "" Vector__XXX
 SG_ VCBATT1_LVBMS_ECPAState m4 : 8|2@1+ (1,0) [0|0] "" Vector__XXX
 SG_ VCBATT1_LVBMS_sumCellVoltage m1 : 8|16@1+ (0.001,0) [0|0] "" Vector__XXX
 SG_ VCBATT1_totalLVLoadCurrent m2 : 8|14@1- (0.1,0) [0|0] "" Vector__XXX
 SG_ VCBATT1_LVBMS_EnterHibernationCommand m4 : 7|1@1+ (1,0) [0|0] "" Vector__XXX
 SG_ VCBATT1_LVBMS_ResetLVBMSCommand m4 : 6|1@1+ (1,0) [0|0] "" Vector__XXX
 SG_ VCBATT1_LVBMS_ClearHistoricFaultCommand m4 : 5|1@1+ (1,0) [0|0] "" Vector__XXX
 SG_ VCBATT1_LVBMS_ClearErrorCntrCommand m4 : 4|1@1+ (1,0) [0|0] "" Vector__XXX
 SG_ VCBATT1_LVBMS_MOSCommand m4 : 3|1@1+ (1,0) [0|0] "" Vector__XXX
 SG_ VCBATT1_LVBMS_packCurrent m0 : 3|22@1+ (0.001,-2000) [0|0] "" Vector__XXX
 SG_ VCBATT1_LVBMS_voltageTarget m3 : 3|16@1+ (0.001,0) [0|0] "" Vector__XXX
 SG_ VCBATT1_lvbmsStatusHighIndex M : 0|3@1+ (1,0) [0|0] "" Vector__XXX

BO_ 1863 DBG_vdcControl: 8 Vector__XXX
 SG_ DBG_vdcDebugEnable : 0|1@1+ (1,0) [0|0] "" Vector__XXX

BO_ 1864 EPBR_CPULoad: 5 Vector__XXX
 SG_ EPBR_CPULoad1000msTask : 32|8@1+ (1,0) [0|0] "" Vector__XXX
 SG_ EPBR_CPULoad100msTask : 24|8@1+ (1,0) [0|0] "" Vector__XXX
 SG_ EPBR_CPULoad10msTask : 16|8@1+ (1,0) [0|0] "" Vector__XXX
 SG_ EPBR_CPULoad1msTask : 8|8@1+ (1,0) [0|0] "" Vector__XXX
 SG_ EPBR_CPULoadTotal : 0|8@1+ (1,0) [0|0] "" Vector__XXX

BO_ 1870 XCP_pmRequest: 8 Vector__XXX
 SG_ XCP_pmRequestData : 7|64@0+ (1,0) [0|0] "" Vector__XXX

BO_ 1871 PM_xcpResponse: 8 Vector__XXX
 SG_ PM_xcpResponseData : 7|64@0+ (1,0) [0|0] "" Vector__XXX

BO_ 1872 XCP_vcbattRequest: 8 Vector__XXX
 SG_ XCP_vcbattRequestData : 0|64@1+ (1,0) [0|0] "" Vector__XXX

BO_ 1873 XCP_vcbatt1Request: 8 Vector__XXX
 SG_ XCP_vcbatt1RequestData : 0|64@1+ (1,0) [0|0] "" Vector__XXX

BO_ 1874 BMS_debugInfo_100Hz: 8 Vector__XXX
 SG_ BMS_energyCounter m4 : 59|4@1+ (1,0) [0|0] "" Vector__XXX
 SG_ BMS_dbgCpUserChargeStatus m2 : 57|3@1+ (1,0) [0|0] "" Vector__XXX
 SG_ BMS_energyCoolantOutletTemp m10 : 56|8@1+ (1,-50) [0|0] "" Vector__XXX
 SG_ BMS_voltageInstabilityMaxBrickVN m8 : 56|7@1+ (1,0) [0|0] "" Vector__XXX
 SG_ BMS_instantPowerDissipation m9 : 54|10@1+ (0.25,0) [0|0] "" Vector__XXX
 SG_ BMS_dbgHviBusIsOff m6 : 50|1@1+ (1,0) [0|0] "" Vector__XXX
 SG_ BMS_impedanceDevDeltaCurrent m12 : 50|12@1+ (1,-3000) [0|0] "" Vector__XXX
 SG_ BMS_energyWalkPackSoc m4 : 49|10@1+ (0.1,0) [0|0] "" Vector__XXX
 SG_ BMS_dbgHviFaultConfinement m6 : 48|2@1+ (1,0) [0|0] "" Vector__XXX
 SG_ BMS_energyWalkPackTemp m5 : 48|8@1- (1,40) [0|0] "" Vector__XXX
 SG_ BMS_missingCellImpedanceDeviatio m13 : 48|10@1+ (0.001,0) [0|0] "" Vector__XXX
 SG_ BMS_chargeSourcePresent m3 : 47|1@1+ (1,0) [0|0] "" Vector__XXX
 SG_ BMS_brickVoltagesClean m3 : 46|1@1+ (1,0) [0|0] "" Vector__XXX
 SG_ BMS_dbgCurrentReg_targetI m2 : 46|11@1+ (0.5,0) [0|0] "" Vector__XXX
 SG_ BMS_energyMinBrickTemp m10 : 46|9@1+ (0.25,-25) [0|0] "" Vector__XXX
 SG_ BMS_brickOcvSum m9 : 44|10@1+ (0.5,0) [0|0] "" Vector__XXX
 SG_ BMS_dbgDischargeCurrentLimitMode m7 : 44|4@1+ (1,0) [0|0] "" Vector__XXX
 SG_ BMS_voltageInstabilityMaxRawCnts m8 : 44|12@1+ (1,0) [0|0] "" Vector__XXX
 SG_ BMS_dbgCurrentReg_error m1 : 40|12@1- (0.1,0) [0|0] "" Vector__XXX
 SG_ BMS_dbgHviRxErrorCount m6 : 40|8@1+ (1,0) [0|0] "" Vector__XXX
 SG_ BMS_dbgPeakRegenCurrentLimitMode m7 : 40|4@1+ (1,0) [0|0] "" Vector__XXX
 SG_ BMS_dbgVoltageReg_output m0 : 40|12@1- (0.5,0) [0|0] "" Vector__XXX
 SG_ BMS_fcCtrCleaningNegCount m3 : 40|6@1+ (1,0) [0|0] "" Vector__XXX
 SG_ BMS_missingCellExcessCurrentGain m13 : 40|8@1+ (0.05,0) [0|0] "" Vector__XXX
 SG_ BMS_snapshot1MaxVoltage m12 : 40|10@1+ (0.005,0) [0|0] "" Vector__XXX
 SG_ BMS_energyMaxBrickTemp m10 : 37|9@1+ (0.25,-25) [0|0] "" Vector__XXX
 SG_ BMS_energyWalkAhRemaining m4 : 37|12@1+ (0.1,0) [0|0] "" Vector__XXX
 SG_ BMS_dbgMaxDcCurrentAvailable m2 : 35|11@1+ (0.5,0) [0|0] "" Vector__XXX
 SG_ BMS_brickOcvMin m9 : 32|12@1+ (0.002,0) [0|0] "" Vector__XXX
 SG_ BMS_dbgChargeNeededState m2 : 32|3@1+ (1,0) [0|0] "" Vector__XXX
 SG_ BMS_dbgHviTxErrorCount m6 : 32|8@1+ (1,0) [0|0] "" Vector__XXX
 SG_ BMS_energyWalkPackResistance m5 : 32|10@1+ (0.1,0) [0|0] "" Vector__XXX
 SG_ BMS_fcCtrCleaningPosCount m3 : 32|6@1+ (1,0) [0|0] "" Vector__XXX
 SG_ BMS_voltageInstabilityFltExcessN m8 : 32|12@1+ (0.1,0) [0|0] "" Vector__XXX
 SG_ BMS_fcCtrCleaningActive m3 : 31|1@1+ (1,0) [0|0] "" Vector__XXX
 SG_ BMS_socByDvNetAh m7 : 31|9@1+ (0.002,0) [0|0] "" Vector__XXX
 SG_ BMS_fcCtrCleaningAllowed m3 : 30|1@1+ (1,0) [0|0] "" Vector__XXX
 SG_ BMS_rawImpedanceDeviation m13 : 30|10@1+ (0.001,0) [0|0] "" Vector__XXX
 SG_ BMS_fcCtrCleaningDesired m3 : 29|1@1+ (1,0) [0|0] "" Vector__XXX
 SG_ BMS_avgBrickImpedance m12 : 28|12@1+ (0.01,0) [0|0] "" Vector__XXX
 SG_ BMS_dbgVoltageReg_error m0 : 28|12@1- (0.00122,0) [0|0] "" Vector__XXX
 SG_ BMS_smHvUpRequestAllowed m3 : 28|1@1+ (1,0) [0|0] "" Vector__XXX
 SG_ BMS_dbgHvsGoToSleep m6 : 27|1@1+ (1,0) [0|0] "" Vector__XXX
 SG_ BMS_minTetheredLoadPresent m3 : 27|1@1+ (1,0) [0|0] "" Vector__XXX
 SG_ BMS_dbgHvsBusIsOff m6 : 26|1@1+ (1,0) [0|0] "" Vector__XXX
 SG_ BMS_walkEnergy m4 : 26|11@1+ (0.1,0) [0|0] "" Vector__XXX
 SG_ BMS_chargeEnergyPackCurrent m10 : 24|13@1- (1,1000) [0|0] "" Vector__XXX
 SG_ BMS_dbgCurrentReg_outProp m1 : 24|14@1- (0.1,0) [0|0] "" Vector__XXX
 SG_ BMS_dbgHvsFaultConfinement m6 : 24|2@1+ (1,0) [0|0] "" Vector__XXX
 SG_ BMS_fcLinkLeakageTestStatus m3 : 24|3@1+ (1,0) [0|0] "" Vector__XXX
 SG_ BMS_dbgEnoughPowerForSupport m3 : 21|1@1+ (1,0) [0|0] "" Vector__XXX
 SG_ BMS_socByDvStartCurrent m7 : 21|10@1- (1,0) [0|0] "" Vector__XXX
 SG_ BMS_voltageDiffPerSMax m8 : 21|11@1+ (0.00244140625,-2.5) [0|0] "" Vector__XXX
 SG_ BMS_brickOcvMax m9 : 20|12@1+ (0.002,0) [0|0] "" Vector__XXX
 SG_ BMS_dbgUdsCtrControlActive m3 : 20|1@1+ (1,0) [0|0] "" Vector__XXX
 SG_ BMS_normalizedDcrNoise m13 : 20|10@1+ (0.001,0) [0|0] "" Vector__XXX
 SG_ BMS_dbgFeimBlocking m3 : 19|1@1+ (1,0) [0|0] "" Vector__XXX
 SG_ BMS_dbgSmDriveActive m3 : 18|1@1+ (1,0) [0|0] "" Vector__XXX
 SG_ BMS_dbgOffsetReg_output m2 : 17|14@1- (0.1,0) [0|0] "" Vector__XXX
 SG_ BMS_dbgSmStateSupportRequired m3 : 17|1@1+ (1,0) [0|0] "" Vector__XXX
 SG_ BMS_dbgVoltageReg_Ki m0 : 17|11@1+ (1,0) [0|0] "" Vector__XXX
 SG_ BMS_energyWalkPackCurrent m5 : 17|15@1- (0.1,1000) [0|0] "" Vector__XXX
 SG_ BMS_dbgChargeNeeded m3 : 16|1@1+ (1,0) [0|0] "" Vector__XXX
 SG_ BMS_dbgHvsRxErrorCount m6 : 16|8@1+ (1,0) [0|0] "" Vector__XXX
 SG_ BMS_energyWalkTime m4 : 16|10@1+ (0.01,0) [0|0] "" Vector__XXX
 SG_ BMS_maxDeviationBrickImpedance m12 : 16|12@1+ (0.01,0) [0|0] "" Vector__XXX
 SG_ BMS_energyWalkId m4 : 13|3@1+ (1,0) [0|0] "" Vector__XXX
 SG_ BMS_dbgChargeState m3 : 12|4@1+ (1,0) [0|0] "" Vector__XXX
 SG_ BMS_energyWalkTimedOut m4 : 12|1@1+ (1,0) [0|0] "" Vector__XXX
 SG_ BMS_dbgSmBmsWantsToCharge m3 : 11|1@1+ (1,0) [0|0] "" Vector__XXX
 SG_ BMS_energyTargetReached m4 : 11|1@1+ (1,0) [0|0] "" Vector__XXX
 SG_ BMS_dbgSmChargerActive m3 : 10|1@1+ (1,0) [0|0] "" Vector__XXX
 SG_ BMS_energyNotEnoughPower m4 : 10|1@1+ (1,0) [0|0] "" Vector__XXX
 SG_ BMS_dbgSmChargeRequestActive m3 : 9|1@1+ (1,0) [0|0] "" Vector__XXX
 SG_ BMS_energySocLimitReached m4 : 9|1@1+ (1,0) [0|0] "" Vector__XXX
 SG_ BMS_socByDvStartCcv m7 : 9|12@1+ (0.002,0) [0|0] "" Vector__XXX
 SG_ BMS_voltageInstabilityFiltMedian m8 : 9|12@1+ (0.1,0) [0|0] "" Vector__XXX
 SG_ BMS_brickOcvAvg m9 : 8|12@1+ (0.002,0) [0|0] "" Vector__XXX
 SG_ BMS_dbgCurrentReg_outIntegral m1 : 8|14@1- (0.1,0) [0|0] "" Vector__XXX
 SG_ BMS_dbgHvsTxErrorCount m6 : 8|8@1+ (1,0) [0|0] "" Vector__XXX
 SG_ BMS_dbgSmChargeCablePresent m3 : 8|1@1+ (1,0) [0|0] "" Vector__XXX
 SG_ BMS_dbgVoltageReg_Kp m0 : 8|9@1+ (5,0) [0|0] "" Vector__XXX
 SG_ BMS_energySimulationWalk m11 : 8|3@1+ (1,0) [0|0] "" Vector__XXX
 SG_ BMS_energySimulationWalkTime m10 : 8|14@1+ (0.1,0) [0|0] "" Vector__XXX
 SG_ BMS_energyWalkDone m4 : 8|1@1+ (1,0) [0|0] "" Vector__XXX
 SG_ BMS_energyWalkLoadedPackV m5 : 8|9@1+ (1,0) [0|0] "" Vector__XXX
 SG_ BMS_maxDeviationBrickId m12 : 8|8@1+ (1,1) [0|0] "" Vector__XXX
 SG_ BMS_measuredImpedanceNoise m13 : 8|12@1+ (0.001,0) [0|0] "" Vector__XXX
 SG_ BMS_socByDvStartPtInitialized m7 : 8|1@1+ (1,0) [0|0] "" Vector__XXX
 SG_ BMS_voltageInstabilityPresent m8 : 8|1@1+ (1,0) [0|0] "" Vector__XXX
 SG_ BMS_dbgSmChgModuleBlockingTrans m3 : 7|1@1+ (1,0) [0|0] "" Vector__XXX
 SG_ BMS_energyPowerTargetReached m4 : 7|1@1+ (1,0) [0|0] "" Vector__XXX
 SG_ BMS_dbgLoadReg_output m2 : 6|11@1- (0.1,0) [0|0] "" Vector__XXX
 SG_ BMS_dbgSmWeldRequest m3 : 6|1@1+ (1,0) [0|0] "" Vector__XXX
 SG_ BMS_energyVoltageFloorReached m4 : 6|1@1+ (1,0) [0|0] "" Vector__XXX
 SG_ BMS_100HzDebug_Id M : 0|6@1+ (1,0) [0|0] "" Vector__XXX

BO_ 1875 XCP_vcrightRequest: 12 Vector__XXX
 SG_ XCP_vcrightRequestData : 7|64@0+ (1,0) [0|0] "" Vector__XXX

BO_ 1876 XCP_vcfrontRequest: 12 Vector__XXX
 SG_ XCP_vcfrontRequestData : 7|64@0+ (1,0) [0|0] "" Vector__XXX

BO_ 1877 XCP_vcsecRequest: 12 Vector__XXX
 SG_ XCP_vcsecRequestData : 7|64@0+ (1,0) [0|0] "" Vector__XXX

BO_ 1878 XCP_vcleftRequest: 12 Vector__XXX
 SG_ XCP_vcleftRequestData : 7|64@0+ (1,0) [0|0] "" Vector__XXX

BO_ 1879 DIF_debug: 8 Vector__XXX
 SG_ DIF_immobilizerStack m68 : 56|8@1+ (0.4,0) [0|0] "" Vector__XXX
 SG_ DIF_posDcBusbarTemp m70 : 56|8@1+ (1,-40) [0|0] "" Vector__XXX
 SG_ DIF_intervalMaxHvBusV m72 : 54|10@1+ (1,0) [0|0] "" Vector__XXX
 SG_ DIF_cpuIDWord3 m132 : 48|16@1+ (1,0) [0|0] "" Vector__XXX
 SG_ DIF_internalAngleFilt m37 : 48|16@1+ (0.0003,0) [0|0] "" Vector__XXX
 SG_ DIF_magnetTempEst m47 : 48|8@1+ (1,-40) [0|0] "" Vector__XXX
 SG_ DIF_module10HzStack m66 : 48|8@1+ (0.4,0) [0|0] "" Vector__XXX
 SG_ DIF_motorIBavg m38 : 48|16@1- (0.1,0) [0|0] "" Vector__XXX
 SG_ DIF_motorV m34 : 48|16@1+ (2e-05,0) [0|0] "" Vector__XXX
 SG_ DIF_negDcBusbarTemp m70 : 48|8@1+ (1,-40) [0|0] "" Vector__XXX
 SG_ DIF_peakFlux m36 : 48|16@1+ (0.0001,0) [0|0] "" Vector__XXX
 SG_ DIF_phaseImbalanceFactor m35 : 48|16@1+ (0.0001,0) [0|0] "" Vector__XXX
 SG_ DIF_pwmState m63 : 48|2@1+ (1,0) [0|0] "" Vector__XXX
 SG_ DIF_resolverErrorRmsSquared m52 : 48|8@1+ (0.005,0) [0|0] "" Vector__XXX
 SG_ DIF_tqScaleMaxMotorSpeed m40 : 48|8@1+ (0.4,0) [0|0] "" Vector__XXX
 SG_ DIF_xcpStack m68 : 48|8@1+ (0.4,0) [0|0] "" Vector__XXX
 SG_ DIF_statorSlotWindingTemp m72 : 46|8@1+ (1,-40) [0|0] "" Vector__XXX
 SG_ DIF_resolverClaMIA m48 : 43|1@1+ (1,0) [0|0] "" Vector__XXX
 SG_ DIF_resolverNoPhaseLock m48 : 42|1@1+ (1,0) [0|0] "" Vector__XXX
 SG_ DIF_resolverNoCarrier m48 : 41|1@1+ (1,0) [0|0] "" Vector__XXX
 SG_ DIF_controlStack m67 : 40|8@1+ (0.4,0) [0|0] "" Vector__XXX
 SG_ DIF_cpu10msMin m66 : 40|8@1+ (0.4,0) [0|0] "" Vector__XXX
 SG_ DIF_hvDcCableTemp m70 : 40|8@1+ (1,-40) [0|0] "" Vector__XXX
 SG_ DIF_loadAngle m42 : 40|16@1- (0.0003,0) [0|0] "" Vector__XXX
 SG_ DIF_motorIC m32 : 40|16@1+ (0.1,0) [0|0] "" Vector__XXX
 SG_ DIF_resolverReady m48 : 40|1@1+ (1,0) [0|0] "" Vector__XXX
 SG_ DIF_resolverSinFiltered m52 : 40|8@1- (0.01,0) [0|0] "" Vector__XXX
 SG_ DIF_soptMaxCurrentMagSqrd m49 : 40|16@1+ (100,0) [0|0] "" Vector__XXX
 SG_ DIF_statorTemp2 m64 : 40|8@1+ (1,-40) [0|0] "" Vector__XXX
 SG_ DIF_torquePerAmp m33 : 40|16@1+ (0.0001,0) [0|0] "" Vector__XXX
 SG_ DIF_tqSatMotorCurrent m39 : 40|8@1+ (0.4,0) [0|0] "" Vector__XXX
 SG_ DIF_udsStack m68 : 40|8@1+ (0.4,0) [0|0] "" Vector__XXX
 SG_ DIF_cpu100HzAvg m66 : 32|8@1+ (0.4,0) [0|0] "" Vector__XXX
 SG_ DIF_cpu20kHzAvg m67 : 32|8@1+ (0.4,0) [0|0] "" Vector__XXX
 SG_ DIF_cpuIDWord2 m132 : 32|16@1+ (1,0) [0|0] "" Vector__XXX
 SG_ DIF_crc m131 : 32|32@1+ (1,0) [0|0] "" Vector__XXX
 SG_ DIF_dcCableHeat m47 : 32|16@1+ (0.001,0) [0|0] "" Vector__XXX
 SG_ DIF_dcLinkCapTemp m70 : 32|8@1+ (1,-40) [0|0] "" Vector__XXX
 SG_ DIF_driveUnitOdometer m69 : 32|32@1+ (10,0) [0|0] "" Vector__XXX
 SG_ DIF_eepromStack m68 : 32|8@1+ (0.4,0) [0|0] "" Vector__XXX
 SG_ DIF_llrScale m42 : 32|8@1+ (0.015,0) [0|0] "" Vector__XXX
 SG_ DIF_loadAngleMargin m37 : 32|16@1- (0.0003,0) [0|0] "" Vector__XXX
 SG_ DIF_motorIAavg m38 : 32|16@1- (0.1,0) [0|0] "" Vector__XXX
 SG_ DIF_oilPumpPressureExpectedMin m46 : 32|8@1+ (2,0) [0|0] "" Vector__XXX
 SG_ DIF_preregulatorRail m50 : 32|8@1+ (0.15,0) [0|0] "" Vector__XXX
 SG_ DIF_resolverCommonGain m48 : 32|8@1+ (0.025,0) [0|0] "" Vector__XXX
 SG_ DIF_resolverCosFiltered m52 : 32|8@1- (0.01,0) [0|0] "" Vector__XXX
 SG_ DIF_statorFluxFdb m35 : 32|16@1+ (0.0001,0) [0|0] "" Vector__XXX
 SG_ DIF_statorIQfdb m34 : 32|16@1- (0.1,0) [0|0] "" Vector__XXX
 SG_ DIF_statorTemp1 m64 : 32|8@1+ (1,-40) [0|0] "" Vector__XXX
 SG_ DIF_statorVD m36 : 32|16@1- (4e-05,0) [0|0] "" Vector__XXX
 SG_ DIF_statorVQFiltered m63 : 32|16@1- (4e-05,0) [0|0] "" Vector__XXX
 SG_ DIF_tqSatMotorVoltage m39 : 32|8@1+ (0.4,0) [0|0] "" Vector__XXX
 SG_ DIF_wasteCurrentLimit m41 : 32|16@1+ (0.1,0) [0|0] "" Vector__XXX
 SG_ DIF_pyroSenseV m72 : 30|8@1+ (0.02,0) [0|0] "" Vector__XXX
 SG_ DIF_activeDischargeRail m50 : 24|8@1+ (0.3,0) [0|0] "" Vector__XXX
 SG_ DIF_cpu100HzMin m66 : 24|8@1+ (0.4,0) [0|0] "" Vector__XXX
 SG_ DIF_cpu20kHzMin m67 : 24|8@1+ (0.4,0) [0|0] "" Vector__XXX
 SG_ DIF_decodeHardwareStack m68 : 24|8@1+ (0.4,0) [0|0] "" Vector__XXX
 SG_ DIF_lightSenseV m72 : 24|6@1+ (0.1,0) [0|0] "" Vector__XXX
 SG_ DIF_llsScale m42 : 24|8@1+ (0.004,0) [0|0] "" Vector__XXX
 SG_ DIF_motorIB m32 : 24|16@1+ (0.1,0) [0|0] "" Vector__XXX
 SG_ DIF_oilPumpPressureEstimateMax m46 : 24|8@1+ (2,0) [0|0] "" Vector__XXX
 SG_ DIF_pcsTemp m64 : 24|8@1+ (1,-40) [0|0] "" Vector__XXX
 SG_ DIF_phaseOutLugTemp m70 : 24|8@1+ (1,-40) [0|0] "" Vector__XXX
 SG_ DIF_resolverPhaseOffset m48 : 24|8@1+ (0.4,0) [0|0] "" Vector__XXX
 SG_ DIF_resolverSinRmsSquared m52 : 24|8@1+ (0.005,0) [0|0] "" Vector__XXX
 SG_ DIF_soptTimeToOff m49 : 24|11@1+ (0.05,0) [0|0] "" Vector__XXX
 SG_ DIF_statorIDfdb m33 : 24|16@1- (0.1,0) [0|0] "" Vector__XXX
 SG_ DIF_tcMinRequest m40 : 24|8@1+ (5,0) [0|0] "" Vector__XXX
 SG_ DIF_rotorOffsetMean m43 : 20|12@1- (0.01,0) [0|0] "" Vector__XXX
 SG_ DIF_busbarTemp m64 : 16|8@1+ (1,-40) [0|0] "" Vector__XXX
 SG_ DIF_cpu10HzAvg m66 : 16|8@1+ (0.4,0) [0|0] "" Vector__XXX
 SG_ DIF_cpu1HzAvg m128 : 16|8@1+ (0.4,0) [0|0] "" Vector__XXX
 SG_ DIF_cpu1kHzAvg m67 : 16|8@1+ (0.4,0) [0|0] "" Vector__XXX
 SG_ DIF_cpuIDWord0 m131 : 16|16@1+ (1,0) [0|0] "" Vector__XXX
 SG_ DIF_cpuIDWord1 m132 : 16|16@1+ (1,0) [0|0] "" Vector__XXX
 SG_ DIF_idleStack m68 : 16|8@1+ (0.4,0) [0|0] "" Vector__XXX
 SG_ DIF_lvBoostedRail m50 : 16|8@1+ (0.08,0) [0|0] "" Vector__XXX
 SG_ DIF_offsetB m44 : 16|6@1- (0.763,0) [0|0] "" Vector__XXX
 SG_ DIF_oilPumpPhaseVoltage m46 : 16|8@1+ (0.3,0) [0|0] "" Vector__XXX
 SG_ DIF_peakIQref m38 : 16|16@1+ (0.1,0) [0|0] "" Vector__XXX
 SG_ DIF_phaseOutBusbarWeldTemp m70 : 16|8@1+ (1,-40) [0|0] "" Vector__XXX
 SG_ DIF_resolverCosRmsSquared m52 : 16|8@1+ (0.005,0) [0|0] "" Vector__XXX
 SG_ DIF_resolverOffsetSin m48 : 16|8@1+ (0.015,0) [0|0] "" Vector__XXX
 SG_ DIF_rotorFlux m47 : 16|16@1+ (0.0001,0) [0|0] "" Vector__XXX
 SG_ DIF_rotorMaxMagnetTemp m72 : 16|8@1+ (1,-40) [0|0] "" Vector__XXX
 SG_ DIF_soptTripDelay m49 : 16|8@1+ (0.05,0) [0|0] "" Vector__XXX
 SG_ DIF_statorFluxRef m35 : 16|16@1+ (0.0001,0) [0|0] "" Vector__XXX
 SG_ DIF_statorIQref m34 : 16|16@1- (0.1,0) [0|0] "" Vector__XXX
 SG_ DIF_statorVDFiltered m63 : 16|16@1- (4e-05,0) [0|0] "" Vector__XXX
 SG_ DIF_statorVQ m36 : 16|16@1- (4e-05,0) [0|0] "" Vector__XXX
 SG_ DIF_tcMaxRequest m40 : 16|8@1+ (5,0) [0|0] "" Vector__XXX
 SG_ DIF_usmState m38 : 12|3@1+ (1,0) [0|0] "" Vector__XXX
 SG_ DIF_mechssLatchesActive m50 : 9|1@1+ (1,0) [0|0] "" Vector__XXX
 SG_ DIF_cpu10HzMin m66 : 8|8@1+ (0.4,0) [0|0] "" Vector__XXX
 SG_ DIF_cpu1HzMin m128 : 8|8@1+ (0.4,0) [0|0] "" Vector__XXX
 SG_ DIF_cpu1kHzMin m67 : 8|8@1+ (0.4,0) [0|0] "" Vector__XXX
 SG_ DIF_dcCapTemp m64 : 8|8@1+ (1,-40) [0|0] "" Vector__XXX
 SG_ DIF_gainScale m37 : 8|8@1+ (0.01,0) [0|0] "" Vector__XXX
 SG_ DIF_hwFaultCount m69 : 8|4@1+ (1,0) [0|0] "" Vector__XXX
 SG_ DIF_latchFeedback m50 : 8|1@1+ (1,0) [0|0] "" Vector__XXX
 SG_ DIF_lmScale m36 : 8|8@1+ (0.004,0) [0|0] "" Vector__XXX
 SG_ DIF_motorIA m32 : 8|16@1+ (0.1,0) [0|0] "" Vector__XXX
 SG_ DIF_offsetA m44 : 8|6@1- (0.763,0) [0|0] "" Vector__XXX
 SG_ DIF_oilPumpMotorSpeed m46 : 8|8@1+ (40,0) [0|0] "" Vector__XXX
 SG_ DIF_phaseOutBusbarTemp m70 : 8|8@1+ (1,-40) [0|0] "" Vector__XXX
 SG_ DIF_resolverOffsetCos m48 : 8|8@1+ (0.015,0) [0|0] "" Vector__XXX
 SG_ DIF_rotorOffsetEst m43 : 8|12@1- (0.01,0) [0|0] "" Vector__XXX
 SG_ DIF_rsScale m34 : 8|8@1+ (0.01,0) [0|0] "" Vector__XXX
 SG_ DIF_soptTimeToTrip m49 : 8|8@1+ (0.05,0) [0|0] "" Vector__XXX
 SG_ DIF_statorEndWindingTemp m72 : 8|8@1+ (1,-40) [0|0] "" Vector__XXX
 SG_ DIF_statorIDref m33 : 8|16@1- (0.1,0) [0|0] "" Vector__XXX
 SG_ DIF_systemStack m68 : 8|8@1+ (0.4,0) [0|0] "" Vector__XXX
 SG_ DIF_tqSatThermal m39 : 8|8@1+ (0.4,0) [0|0] "" Vector__XXX
 SG_ DIF_tqScaleDifferential m35 : 8|8@1+ (0.4,0) [0|0] "" Vector__XXX
 SG_ DIF_debugSelector M : 0|8@1+ (1,0) [0|0] "" Vector__XXX

BO_ 1881 XCP_vcfront1Request: 8 Vector__XXX
 SG_ XCP_vcfront1RequestData : 0|64@1+ (1,0) [0|0] "" Vector__XXX

BO_ 1882 XCP_vcfront2Request: 8 Vector__XXX
 SG_ XCP_vcfront2RequestData : 0|64@1+ (1,0) [0|0] "" Vector__XXX

BO_ 1883 XCP_vcbatt2Request: 8 Vector__XXX
 SG_ XCP_vcbatt2RequestData : 0|64@1+ (1,0) [0|0] "" Vector__XXX

BO_ 1886 CHADA_status_2: 8 Vector__XXX
 SG_ CA_VEH_BAT_SOC m0 : 56|8@1+ (0.39215686275,0) [0|0] "" Vector__XXX
 SG_ CA_disableVehicleLimiting m2 : 56|1@1+ (1,0) [0|0] "" Vector__XXX
 SG_ CA_flybackVoltageLimit m1 : 48|16@1+ (0.01283327338,0) [0|0] "" Vector__XXX
 SG_ CA_EVSE_Avail_I_Out m1 : 40|8@1+ (1,0) [0|0] "" Vector__XXX
 SG_ CA_VEH_BAT_V_Target m0 : 40|16@1+ (1,0) [0|0] "" Vector__XXX
 SG_ CA_pcbaTempDegC m2 : 40|16@1- (0.01007110813,25) [0|0] "" Vector__XXX
 SG_ CA_pcbaTempV m3 : 40|16@1+ (5.035477e-05,0) [0|0] "" Vector__XXX
 SG_ CA_BMS_protocolVersion m0 : 32|8@1+ (1,0) [0|0] "" Vector__XXX
 SG_ CA_EVSE_Avail_V_Out m1 : 24|16@1+ (1,0) [0|0] "" Vector__XXX
 SG_ CA_EVSE_Eff_Avail_I_Out m4 : 24|16@1+ (1,0) [0|0] "" Vector__XXX
 SG_ CA_FC_protocolVersion m0 : 24|8@1+ (1,0) [0|0] "" Vector__XXX
 SG_ CA_evseConnTempDegC m2 : 24|16@1- (0.00457770657,0) [0|0] "" Vector__XXX
 SG_ CA_evseConnTempV m3 : 24|16@1+ (5.035477e-05,0) [0|0] "" Vector__XXX
 SG_ CA_EVSE_Ext_Protocol_Ver m0 : 16|8@1+ (1,0) [0|0] "" Vector__XXX
 SG_ CA_EVSE_Ext_Avail_I_Out m4 : 8|16@1+ (1,0) [0|0] "" Vector__XXX
 SG_ CA_EVSE_Threshold_V m1 : 8|16@1+ (1,0) [0|0] "" Vector__XXX
 SG_ CA_VEH_Ext_Protocol_Ver m0 : 8|8@1+ (1,0) [0|0] "" Vector__XXX
 SG_ CA_vehConnTempDegC m2 : 8|16@1- (0.00457770657,0) [0|0] "" Vector__XXX
 SG_ CA_vehConnTempV m3 : 8|16@1+ (5.035477e-05,0) [0|0] "" Vector__XXX
 SG_ CA_status2DummySig : 7|1@1+ (1,0) [0|0] "" Vector__XXX
 SG_ CA_status2DataSelect M : 0|7@1+ (1,0) [0|0] "" Vector__XXX

BO_ 1889 PMF_debug: 8 Vector__XXX
 SG_ PMF_resolverDiMIA m17 : 57|1@1+ (1,0) [0|0] "" Vector__XXX
 SG_ PMF_cpu100HzMin m64 : 56|8@1+ (0.4,0) [0|0] "" Vector__XXX
 SG_ PMF_cpu10kHzMax m65 : 56|8@1+ (0.4,0) [0|0] "" Vector__XXX
 SG_ PMF_lmSatCoeff m3 : 56|8@1+ (0.00391,0) [0|0] "" Vector__XXX
 SG_ PMF_resolverClaMIA m17 : 56|1@1+ (1,0) [0|0] "" Vector__XXX
 SG_ PMF_statorT m4 : 56|8@1+ (1,-40) [0|0] "" Vector__XXX
 SG_ PMF_resolverPhaseOutOfSpec m17 : 55|1@1+ (1,0) [0|0] "" Vector__XXX
 SG_ PMF_resolverNoCarrier m17 : 54|1@1+ (1,0) [0|0] "" Vector__XXX
 SG_ PMF_cpu1kHzAvg m64 : 48|8@1+ (0.4,0) [0|0] "" Vector__XXX
 SG_ PMF_cpu20kHzMin m65 : 48|8@1+ (0.4,0) [0|0] "" Vector__XXX
 SG_ PMF_resolverOffsetExt m17 : 48|6@1+ (0.053,0) [0|0] "" Vector__XXX
 SG_ PMF_torqueOutOfMap m5 : 47|1@1+ (1,0) [0|0] "" Vector__XXX
 SG_ PMF_switchingActive m5 : 46|1@1+ (1,0) [0|0] "" Vector__XXX
 SG_ PMF_cpu100HzMax m64 : 40|8@1+ (0.4,0) [0|0] "" Vector__XXX
 SG_ PMF_cpu20kHzMax m65 : 40|8@1+ (0.4,0) [0|0] "" Vector__XXX
 SG_ PMF_iDQmagnitude m3 : 40|16@1- (0.0939,0) [0|0] "" Vector__XXX
 SG_ PMF_motorRPM m4 : 40|16@1- (1,0) [0|0] "" Vector__XXX
 SG_ PMF_resolverOffsetSin m17 : 40|6@1+ (0.053,0) [0|0] "" Vector__XXX
 SG_ PMF_torqueAccelAvg m1 : 40|13@1- (2,0) [0|0] "" Vector__XXX
 SG_ PMF_torqueReversalWindow m2 : 40|13@1- (2,0) [0|0] "" Vector__XXX
 SG_ PMF_cpu10HzMin m65 : 32|8@1+ (0.4,0) [0|0] "" Vector__XXX
 SG_ PMF_cpu10kHzAvg m64 : 32|8@1+ (0.4,0) [0|0] "" Vector__XXX
 SG_ PMF_resolverOffsetCos m17 : 32|6@1+ (0.053,0) [0|0] "" Vector__XXX
 SG_ PMF_Ib m3 : 24|16@1- (0.0939,0) [0|0] "" Vector__XXX
 SG_ PMF_cpu10HzAvg m65 : 24|8@1+ (0.4,0) [0|0] "" Vector__XXX
 SG_ PMF_cpu1kHzMin m64 : 24|8@1+ (0.4,0) [0|0] "" Vector__XXX
 SG_ PMF_idleStackMax m67 : 24|16@1+ (1,0) [0|0] "" Vector__XXX
 SG_ PMF_resolverExcitationGain m17 : 24|7@1+ (0.063,0) [0|0] "" Vector__XXX
 SG_ PMF_sysStackMax m70 : 24|16@1+ (1,0) [0|0] "" Vector__XXX
 SG_ PMF_torqueAccelWindow m1 : 24|13@1- (2,0) [0|0] "" Vector__XXX
 SG_ PMF_torqueDecelAvg m2 : 24|13@1- (2,0) [0|0] "" Vector__XXX
 SG_ PMF_udsStackMax m68 : 24|16@1+ (1,0) [0|0] "" Vector__XXX
 SG_ PMF_xcpStackMax m69 : 24|16@1+ (1,0) [0|0] "" Vector__XXX
 SG_ PMF_offsetIb m5 : 20|12@1- (0.1,0) [0|0] "" Vector__XXX
 SG_ PMF_resolverCommonGain m17 : 17|7@1+ (0.063,0) [0|0] "" Vector__XXX
 SG_ PMF_cpu10HzMax m65 : 16|8@1+ (0.4,0) [0|0] "" Vector__XXX
 SG_ PMF_cpu20kHzAvg m64 : 16|8@1+ (0.4,0) [0|0] "" Vector__XXX
 SG_ PMF_Ia m3 : 8|16@1- (0.0939,0) [0|0] "" Vector__XXX
 SG_ PMF_cpu100HzAvg m65 : 8|8@1+ (0.4,0) [0|0] "" Vector__XXX
 SG_ PMF_cpu10kHzMin m66 : 8|8@1+ (0.4,0) [0|0] "" Vector__XXX
 SG_ PMF_cpu1kHzMax m64 : 8|8@1+ (0.4,0) [0|0] "" Vector__XXX
 SG_ PMF_idleStackSize m67 : 8|16@1+ (1,0) [0|0] "" Vector__XXX
 SG_ PMF_offsetIa m5 : 8|12@1- (0.1,0) [0|0] "" Vector__XXX
 SG_ PMF_resolverPhaseAngle m17 : 8|9@1+ (0.001537,0) [0|0] "" Vector__XXX
 SG_ PMF_resolverSpeedError m16 : 8|16@1- (0.75,0) [0|0] "" Vector__XXX
 SG_ PMF_slipFrequency m4 : 8|16@1- (0.005,0) [0|0] "" Vector__XXX
 SG_ PMF_sysStackSize m70 : 8|16@1+ (1,0) [0|0] "" Vector__XXX
 SG_ PMF_torqueDecelWindow m2 : 8|13@1- (2,0) [0|0] "" Vector__XXX
 SG_ PMF_torqueSignError m1 : 8|13@1- (2,0) [0|0] "" Vector__XXX
 SG_ PMF_udsStackSize m68 : 8|16@1+ (1,0) [0|0] "" Vector__XXX
 SG_ PMF_xcpStackSize m69 : 8|16@1+ (1,0) [0|0] "" Vector__XXX
 SG_ PMF_debugSelector M : 0|8@1+ (1,0) [0|0] "" Vector__XXX

BO_ 1890 VCLEFT_xcpResponse: 8 Vector__XXX
 SG_ VCLEFT_xcpResponseData : 0|64@1+ (1,0) [0|0] "" Vector__XXX

BO_ 1891 VCRIGHT_xcpResponse: 8 Vector__XXX
 SG_ VCRIGHT_xcpResponseData : 0|64@1+ (1,0) [0|0] "" Vector__XXX

BO_ 1892 VCFRONT_xcpResponse: 8 Vector__XXX
 SG_ VCFRONT_xcpResponseData : 0|64@1+ (1,0) [0|0] "" Vector__XXX

BO_ 1894 DIF_dlogData: 8 Vector__XXX
 SG_ DIF_dlogData : 0|64@1+ (1,0) [0|0] "" Vector__XXX

BO_ 1896 VCBATT_xcpResponse: 8 Vector__XXX
 SG_ VCBATT_xcpResponseData : 0|64@1+ (1,0) [0|0] "" Vector__XXX

BO_ 1897 VCBATT1_xcpResponse: 8 Vector__XXX
 SG_ VCBATT1_xcpResponseData : 0|64@1+ (1,0) [0|0] "" Vector__XXX

BO_ 1899 VCFRONT2_xcpResponse: 8 Vector__XXX
 SG_ VCFRONT2_xcpResponseData : 0|64@1+ (1,0) [0|0] "" Vector__XXX

BO_ 1904 VCBATT2_xcpResponse: 8 Vector__XXX
 SG_ VCBATT2_xcpResponseData : 0|64@1+ (1,0) [0|0] "" Vector__XXX

BO_ 1910 XCP_difRequest: 12 Vector__XXX
 SG_ XCP_difRequestData : 7|64@0+ (1,0) [0|0] "" Vector__XXX

BO_ 1911 XCP_diRequest: 12 Vector__XXX
 SG_ XCP_diRequestData : 7|64@0+ (1,0) [0|0] "" Vector__XXX

BO_ 1914 HVP_log1hz: 8 Vector__XXX
 SG_ HVP_shuntAsicChipYCoordinate m0 : 56|8@1+ (1,0) [0|0] "" Vector__XXX
 SG_ HVP_energyReserveAvg m1 : 48|16@1- (0.001,0) [0|0] "" Vector__XXX
 SG_ HVP_shuntAsicChipXCoordinate m0 : 48|8@1+ (1,0) [0|0] "" Vector__XXX
 SG_ HVP_energyReserveMax m1 : 32|16@1- (0.001,0) [0|0] "" Vector__XXX
 SG_ HVP_pyroSquibResistance m0 : 32|16@1+ (0.001,0) [0|0] "" Vector__XXX
 SG_ HVP_energyReserveMin m1 : 16|16@1- (0.001,0) [0|0] "" Vector__XXX
 SG_ HVP_shuntAsicChipWaferNumber m1 : 8|8@1+ (1,0) [0|0] "" Vector__XXX
 SG_ HVP_shuntCurrentAuxLog m0 : 8|24@1- (0.001,0) [0|0] "" Vector__XXX
 SG_ HVP_gpioPcsEnable m1 : 7|1@1+ (1,0) [0|0] "" Vector__XXX
 SG_ HVP_gpioPcsChargePwmEnable m1 : 6|1@1+ (1,0) [0|0] "" Vector__XXX
 SG_ HVP_gpioPcsDcdcPwmEnable m1 : 5|1@1+ (1,0) [0|0] "" Vector__XXX
 SG_ HVP_bmbAsicType m0 : 3|2@1+ (1,0) [0|0] "" Vector__XXX
 SG_ HVP_hvilCalType m1 : 3|2@1+ (1,0) [0|0] "" Vector__XXX
 SG_ HVP_log1HzIndex M : 0|3@1+ (1,0) [0|0] "" Vector__XXX

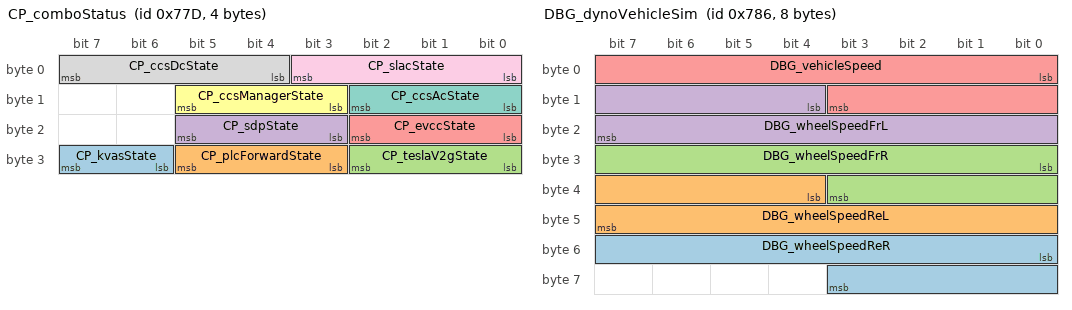
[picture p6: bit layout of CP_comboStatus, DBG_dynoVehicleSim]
BO_ 1917 CP_comboStatus: 4 Vector__XXX
 SG_ CP_kvasState : 30|2@1+ (1,0) [0|0] "" Vector__XXX
 SG_ CP_plcForwardState : 27|3@1+ (1,0) [0|0] "" Vector__XXX
 SG_ CP_teslaV2gState : 24|3@1+ (1,0) [0|0] "" Vector__XXX
 SG_ CP_sdpState : 19|3@1+ (1,0) [0|0] "" Vector__XXX
 SG_ CP_evccState : 16|3@1+ (1,0) [0|0] "" Vector__XXX
 SG_ CP_ccsManagerState : 11|3@1+ (1,0) [0|0] "" Vector__XXX
 SG_ CP_ccsAcState : 8|3@1+ (1,0) [0|0] "" Vector__XXX
 SG_ CP_ccsDcState : 4|4@1+ (1,0) [0|0] "" Vector__XXX
 SG_ CP_slacState : 0|4@1+ (1,0) [0|0] "" Vector__XXX

BO_ 1922 BMS_log3: 8 Vector__XXX
 SG_ BMS_cacRawEstimateBrick1 m0 : 48|13@1+ (0.1,0) [0|0] "" Vector__XXX
 SG_ BMS_cacRawEstimateBrick10 m9 : 48|13@1+ (0.1,0) [0|0] "" Vector__XXX
 SG_ BMS_cacRawEstimateBrick100 m99 : 48|13@1+ (0.1,0) [0|0] "" Vector__XXX
 SG_ BMS_cacRawEstimateBrick101 m100 : 48|13@1+ (0.1,0) [0|0] "" Vector__XXX
 SG_ BMS_cacRawEstimateBrick102 m101 : 48|13@1+ (0.1,0) [0|0] "" Vector__XXX
 SG_ BMS_cacRawEstimateBrick103 m102 : 48|13@1+ (0.1,0) [0|0] "" Vector__XXX
 SG_ BMS_cacRawEstimateBrick104 m103 : 48|13@1+ (0.1,0) [0|0] "" Vector__XXX
 SG_ BMS_cacRawEstimateBrick105 m104 : 48|13@1+ (0.1,0) [0|0] "" Vector__XXX
 SG_ BMS_cacRawEstimateBrick106 m105 : 48|13@1+ (0.1,0) [0|0] "" Vector__XXX
 SG_ BMS_cacRawEstimateBrick107 m106 : 48|13@1+ (0.1,0) [0|0] "" Vector__XXX
 SG_ BMS_cacRawEstimateBrick108 m107 : 48|13@1+ (0.1,0) [0|0] "" Vector__XXX
 SG_ BMS_cacRawEstimateBrick11 m10 : 48|13@1+ (0.1,0) [0|0] "" Vector__XXX
 SG_ BMS_cacRawEstimateBrick12 m11 : 48|13@1+ (0.1,0) [0|0] "" Vector__XXX
 SG_ BMS_cacRawEstimateBrick13 m12 : 48|13@1+ (0.1,0) [0|0] "" Vector__XXX
 SG_ BMS_cacRawEstimateBrick14 m13 : 48|13@1+ (0.1,0) [0|0] "" Vector__XXX
 SG_ BMS_cacRawEstimateBrick15 m14 : 48|13@1+ (0.1,0) [0|0] "" Vector__XXX
 SG_ BMS_cacRawEstimateBrick16 m15 : 48|13@1+ (0.1,0) [0|0] "" Vector__XXX
 SG_ BMS_cacRawEstimateBrick17 m16 : 48|13@1+ (0.1,0) [0|0] "" Vector__XXX
 SG_ BMS_cacRawEstimateBrick18 m17 : 48|13@1+ (0.1,0) [0|0] "" Vector__XXX
 SG_ BMS_cacRawEstimateBrick19 m18 : 48|13@1+ (0.1,0) [0|0] "" Vector__XXX
 SG_ BMS_cacRawEstimateBrick2 m1 : 48|13@1+ (0.1,0) [0|0] "" Vector__XXX
 SG_ BMS_cacRawEstimateBrick20 m19 : 48|13@1+ (0.1,0) [0|0] "" Vector__XXX
 SG_ BMS_cacRawEstimateBrick21 m20 : 48|13@1+ (0.1,0) [0|0] "" Vector__XXX
 SG_ BMS_cacRawEstimateBrick22 m21 : 48|13@1+ (0.1,0) [0|0] "" Vector__XXX
 SG_ BMS_cacRawEstimateBrick23 m22 : 48|13@1+ (0.1,0) [0|0] "" Vector__XXX
 SG_ BMS_cacRawEstimateBrick24 m23 : 48|13@1+ (0.1,0) [0|0] "" Vector__XXX
 SG_ BMS_cacRawEstimateBrick25 m24 : 48|13@1+ (0.1,0) [0|0] "" Vector__XXX
 SG_ BMS_cacRawEstimateBrick26 m25 : 48|13@1+ (0.1,0) [0|0] "" Vector__XXX
 SG_ BMS_cacRawEstimateBrick27 m26 : 48|13@1+ (0.1,0) [0|0] "" Vector__XXX
 SG_ BMS_cacRawEstimateBrick28 m27 : 48|13@1+ (0.1,0) [0|0] "" Vector__XXX
 SG_ BMS_cacRawEstimateBrick29 m28 : 48|13@1+ (0.1,0) [0|0] "" Vector__XXX
 SG_ BMS_cacRawEstimateBrick3 m2 : 48|13@1+ (0.1,0) [0|0] "" Vector__XXX
 SG_ BMS_cacRawEstimateBrick30 m29 : 48|13@1+ (0.1,0) [0|0] "" Vector__XXX
 SG_ BMS_cacRawEstimateBrick31 m30 : 48|13@1+ (0.1,0) [0|0] "" Vector__XXX
 SG_ BMS_cacRawEstimateBrick32 m31 : 48|13@1+ (0.1,0) [0|0] "" Vector__XXX
 SG_ BMS_cacRawEstimateBrick33 m32 : 48|13@1+ (0.1,0) [0|0] "" Vector__XXX
 SG_ BMS_cacRawEstimateBrick34 m33 : 48|13@1+ (0.1,0) [0|0] "" Vector__XXX
 SG_ BMS_cacRawEstimateBrick35 m34 : 48|13@1+ (0.1,0) [0|0] "" Vector__XXX
 SG_ BMS_cacRawEstimateBrick36 m35 : 48|13@1+ (0.1,0) [0|0] "" Vector__XXX
 SG_ BMS_cacRawEstimateBrick37 m36 : 48|13@1+ (0.1,0) [0|0] "" Vector__XXX
 SG_ BMS_cacRawEstimateBrick38 m37 : 48|13@1+ (0.1,0) [0|0] "" Vector__XXX
 SG_ BMS_cacRawEstimateBrick39 m38 : 48|13@1+ (0.1,0) [0|0] "" Vector__XXX
 SG_ BMS_cacRawEstimateBrick4 m3 : 48|13@1+ (0.1,0) [0|0] "" Vector__XXX
 SG_ BMS_cacRawEstimateBrick40 m39 : 48|13@1+ (0.1,0) [0|0] "" Vector__XXX
 SG_ BMS_cacRawEstimateBrick41 m40 : 48|13@1+ (0.1,0) [0|0] "" Vector__XXX
 SG_ BMS_cacRawEstimateBrick42 m41 : 48|13@1+ (0.1,0) [0|0] "" Vector__XXX
 SG_ BMS_cacRawEstimateBrick43 m42 : 48|13@1+ (0.1,0) [0|0] "" Vector__XXX
 SG_ BMS_cacRawEstimateBrick44 m43 : 48|13@1+ (0.1,0) [0|0] "" Vector__XXX
 SG_ BMS_cacRawEstimateBrick45 m44 : 48|13@1+ (0.1,0) [0|0] "" Vector__XXX
 SG_ BMS_cacRawEstimateBrick46 m45 : 48|13@1+ (0.1,0) [0|0] "" Vector__XXX
 SG_ BMS_cacRawEstimateBrick47 m46 : 48|13@1+ (0.1,0) [0|0] "" Vector__XXX
 SG_ BMS_cacRawEstimateBrick48 m47 : 48|13@1+ (0.1,0) [0|0] "" Vector__XXX
 SG_ BMS_cacRawEstimateBrick49 m48 : 48|13@1+ (0.1,0) [0|0] "" Vector__XXX
 SG_ BMS_cacRawEstimateBrick5 m4 : 48|13@1+ (0.1,0) [0|0] "" Vector__XXX
 SG_ BMS_cacRawEstimateBrick50 m49 : 48|13@1+ (0.1,0) [0|0] "" Vector__XXX
 SG_ BMS_cacRawEstimateBrick51 m50 : 48|13@1+ (0.1,0) [0|0] "" Vector__XXX
 SG_ BMS_cacRawEstimateBrick52 m51 : 48|13@1+ (0.1,0) [0|0] "" Vector__XXX
 SG_ BMS_cacRawEstimateBrick53 m52 : 48|13@1+ (0.1,0) [0|0] "" Vector__XXX
 SG_ BMS_cacRawEstimateBrick54 m53 : 48|13@1+ (0.1,0) [0|0] "" Vector__XXX
 SG_ BMS_cacRawEstimateBrick55 m54 : 48|13@1+ (0.1,0) [0|0] "" Vector__XXX
 SG_ BMS_cacRawEstimateBrick56 m55 : 48|13@1+ (0.1,0) [0|0] "" Vector__XXX
 SG_ BMS_cacRawEstimateBrick57 m56 : 48|13@1+ (0.1,0) [0|0] "" Vector__XXX
 SG_ BMS_cacRawEstimateBrick58 m57 : 48|13@1+ (0.1,0) [0|0] "" Vector__XXX
 SG_ BMS_cacRawEstimateBrick59 m58 : 48|13@1+ (0.1,0) [0|0] "" Vector__XXX
 SG_ BMS_cacRawEstimateBrick6 m5 : 48|13@1+ (0.1,0) [0|0] "" Vector__XXX
 SG_ BMS_cacRawEstimateBrick60 m59 : 48|13@1+ (0.1,0) [0|0] "" Vector__XXX
 SG_ BMS_cacRawEstimateBrick61 m60 : 48|13@1+ (0.1,0) [0|0] "" Vector__XXX
 SG_ BMS_cacRawEstimateBrick62 m61 : 48|13@1+ (0.1,0) [0|0] "" Vector__XXX
 SG_ BMS_cacRawEstimateBrick63 m62 : 48|13@1+ (0.1,0) [0|0] "" Vector__XXX
 SG_ BMS_cacRawEstimateBrick64 m63 : 48|13@1+ (0.1,0) [0|0] "" Vector__XXX
 SG_ BMS_cacRawEstimateBrick65 m64 : 48|13@1+ (0.1,0) [0|0] "" Vector__XXX
 SG_ BMS_cacRawEstimateBrick66 m65 : 48|13@1+ (0.1,0) [0|0] "" Vector__XXX
 SG_ BMS_cacRawEstimateBrick67 m66 : 48|13@1+ (0.1,0) [0|0] "" Vector__XXX
 SG_ BMS_cacRawEstimateBrick68 m67 : 48|13@1+ (0.1,0) [0|0] "" Vector__XXX
 SG_ BMS_cacRawEstimateBrick69 m68 : 48|13@1+ (0.1,0) [0|0] "" Vector__XXX
 SG_ BMS_cacRawEstimateBrick7 m6 : 48|13@1+ (0.1,0) [0|0] "" Vector__XXX
 SG_ BMS_cacRawEstimateBrick70 m69 : 48|13@1+ (0.1,0) [0|0] "" Vector__XXX
 SG_ BMS_cacRawEstimateBrick71 m70 : 48|13@1+ (0.1,0) [0|0] "" Vector__XXX
 SG_ BMS_cacRawEstimateBrick72 m71 : 48|13@1+ (0.1,0) [0|0] "" Vector__XXX
 SG_ BMS_cacRawEstimateBrick73 m72 : 48|13@1+ (0.1,0) [0|0] "" Vector__XXX
 SG_ BMS_cacRawEstimateBrick74 m73 : 48|13@1+ (0.1,0) [0|0] "" Vector__XXX
 SG_ BMS_cacRawEstimateBrick75 m74 : 48|13@1+ (0.1,0) [0|0] "" Vector__XXX
 SG_ BMS_cacRawEstimateBrick76 m75 : 48|13@1+ (0.1,0) [0|0] "" Vector__XXX
 SG_ BMS_cacRawEstimateBrick77 m76 : 48|13@1+ (0.1,0) [0|0] "" Vector__XXX
 SG_ BMS_cacRawEstimateBrick78 m77 : 48|13@1+ (0.1,0) [0|0] "" Vector__XXX
 SG_ BMS_cacRawEstimateBrick79 m78 : 48|13@1+ (0.1,0) [0|0] "" Vector__XXX
 SG_ BMS_cacRawEstimateBrick8 m7 : 48|13@1+ (0.1,0) [0|0] "" Vector__XXX
 SG_ BMS_cacRawEstimateBrick80 m79 : 48|13@1+ (0.1,0) [0|0] "" Vector__XXX
 SG_ BMS_cacRawEstimateBrick81 m80 : 48|13@1+ (0.1,0) [0|0] "" Vector__XXX
 SG_ BMS_cacRawEstimateBrick82 m81 : 48|13@1+ (0.1,0) [0|0] "" Vector__XXX
 SG_ BMS_cacRawEstimateBrick83 m82 : 48|13@1+ (0.1,0) [0|0] "" Vector__XXX
 SG_ BMS_cacRawEstimateBrick84 m83 : 48|13@1+ (0.1,0) [0|0] "" Vector__XXX
 SG_ BMS_cacRawEstimateBrick85 m84 : 48|13@1+ (0.1,0) [0|0] "" Vector__XXX
 SG_ BMS_cacRawEstimateBrick86 m85 : 48|13@1+ (0.1,0) [0|0] "" Vector__XXX
 SG_ BMS_cacRawEstimateBrick87 m86 : 48|13@1+ (0.1,0) [0|0] "" Vector__XXX
 SG_ BMS_cacRawEstimateBrick88 m87 : 48|13@1+ (0.1,0) [0|0] "" Vector__XXX
 SG_ BMS_cacRawEstimateBrick89 m88 : 48|13@1+ (0.1,0) [0|0] "" Vector__XXX
 SG_ BMS_cacRawEstimateBrick9 m8 : 48|13@1+ (0.1,0) [0|0] "" Vector__XXX
 SG_ BMS_cacRawEstimateBrick90 m89 : 48|13@1+ (0.1,0) [0|0] "" Vector__XXX
 SG_ BMS_cacRawEstimateBrick91 m90 : 48|13@1+ (0.1,0) [0|0] "" Vector__XXX
 SG_ BMS_cacRawEstimateBrick92 m91 : 48|13@1+ (0.1,0) [0|0] "" Vector__XXX
 SG_ BMS_cacRawEstimateBrick93 m92 : 48|13@1+ (0.1,0) [0|0] "" Vector__XXX
 SG_ BMS_cacRawEstimateBrick94 m93 : 48|13@1+ (0.1,0) [0|0] "" Vector__XXX
 SG_ BMS_cacRawEstimateBrick95 m94 : 48|13@1+ (0.1,0) [0|0] "" Vector__XXX
 SG_ BMS_cacRawEstimateBrick96 m95 : 48|13@1+ (0.1,0) [0|0] "" Vector__XXX
 SG_ BMS_cacRawEstimateBrick97 m96 : 48|13@1+ (0.1,0) [0|0] "" Vector__XXX
 SG_ BMS_cacRawEstimateBrick98 m97 : 48|13@1+ (0.1,0) [0|0] "" Vector__XXX
 SG_ BMS_cacRawEstimateBrick99 m98 : 48|13@1+ (0.1,0) [0|0] "" Vector__XXX
 SG_ BMS_cacLowerBoundBrick1 m0 : 35|13@1+ (0.1,0) [0|0] "" Vector__XXX
 SG_ BMS_cacLowerBoundBrick10 m9 : 35|13@1+ (0.1,0) [0|0] "" Vector__XXX
 SG_ BMS_cacLowerBoundBrick100 m99 : 35|13@1+ (0.1,0) [0|0] "" Vector__XXX
 SG_ BMS_cacLowerBoundBrick101 m100 : 35|13@1+ (0.1,0) [0|0] "" Vector__XXX
 SG_ BMS_cacLowerBoundBrick102 m101 : 35|13@1+ (0.1,0) [0|0] "" Vector__XXX
 SG_ BMS_cacLowerBoundBrick103 m102 : 35|13@1+ (0.1,0) [0|0] "" Vector__XXX
 SG_ BMS_cacLowerBoundBrick104 m103 : 35|13@1+ (0.1,0) [0|0] "" Vector__XXX
 SG_ BMS_cacLowerBoundBrick105 m104 : 35|13@1+ (0.1,0) [0|0] "" Vector__XXX
 SG_ BMS_cacLowerBoundBrick106 m105 : 35|13@1+ (0.1,0) [0|0] "" Vector__XXX
 SG_ BMS_cacLowerBoundBrick107 m106 : 35|13@1+ (0.1,0) [0|0] "" Vector__XXX
 SG_ BMS_cacLowerBoundBrick108 m107 : 35|13@1+ (0.1,0) [0|0] "" Vector__XXX
 SG_ BMS_cacLowerBoundBrick11 m10 : 35|13@1+ (0.1,0) [0|0] "" Vector__XXX
 SG_ BMS_cacLowerBoundBrick12 m11 : 35|13@1+ (0.1,0) [0|0] "" Vector__XXX
 SG_ BMS_cacLowerBoundBrick13 m12 : 35|13@1+ (0.1,0) [0|0] "" Vector__XXX
 SG_ BMS_cacLowerBoundBrick14 m13 : 35|13@1+ (0.1,0) [0|0] "" Vector__XXX
 SG_ BMS_cacLowerBoundBrick15 m14 : 35|13@1+ (0.1,0) [0|0] "" Vector__XXX
 SG_ BMS_cacLowerBoundBrick16 m15 : 35|13@1+ (0.1,0) [0|0] "" Vector__XXX
 SG_ BMS_cacLowerBoundBrick17 m16 : 35|13@1+ (0.1,0) [0|0] "" Vector__XXX
 SG_ BMS_cacLowerBoundBrick18 m17 : 35|13@1+ (0.1,0) [0|0] "" Vector__XXX
 SG_ BMS_cacLowerBoundBrick19 m18 : 35|13@1+ (0.1,0) [0|0] "" Vector__XXX
 SG_ BMS_cacLowerBoundBrick2 m1 : 35|13@1+ (0.1,0) [0|0] "" Vector__XXX
 SG_ BMS_cacLowerBoundBrick20 m19 : 35|13@1+ (0.1,0) [0|0] "" Vector__XXX
 SG_ BMS_cacLowerBoundBrick21 m20 : 35|13@1+ (0.1,0) [0|0] "" Vector__XXX
 SG_ BMS_cacLowerBoundBrick22 m21 : 35|13@1+ (0.1,0) [0|0] "" Vector__XXX
 SG_ BMS_cacLowerBoundBrick23 m22 : 35|13@1+ (0.1,0) [0|0] "" Vector__XXX
 SG_ BMS_cacLowerBoundBrick24 m23 : 35|13@1+ (0.1,0) [0|0] "" Vector__XXX
 SG_ BMS_cacLowerBoundBrick25 m24 : 35|13@1+ (0.1,0) [0|0] "" Vector__XXX
 SG_ BMS_cacLowerBoundBrick26 m25 : 35|13@1+ (0.1,0) [0|0] "" Vector__XXX
 SG_ BMS_cacLowerBoundBrick27 m26 : 35|13@1+ (0.1,0) [0|0] "" Vector__XXX
 SG_ BMS_cacLowerBoundBrick28 m27 : 35|13@1+ (0.1,0) [0|0] "" Vector__XXX
 SG_ BMS_cacLowerBoundBrick29 m28 : 35|13@1+ (0.1,0) [0|0] "" Vector__XXX
 SG_ BMS_cacLowerBoundBrick3 m2 : 35|13@1+ (0.1,0) [0|0] "" Vector__XXX
 SG_ BMS_cacLowerBoundBrick30 m29 : 35|13@1+ (0.1,0) [0|0] "" Vector__XXX
 SG_ BMS_cacLowerBoundBrick31 m30 : 35|13@1+ (0.1,0) [0|0] "" Vector__XXX
 SG_ BMS_cacLowerBoundBrick32 m31 : 35|13@1+ (0.1,0) [0|0] "" Vector__XXX
 SG_ BMS_cacLowerBoundBrick33 m32 : 35|13@1+ (0.1,0) [0|0] "" Vector__XXX
 SG_ BMS_cacLowerBoundBrick34 m33 : 35|13@1+ (0.1,0) [0|0] "" Vector__XXX
 SG_ BMS_cacLowerBoundBrick35 m34 : 35|13@1+ (0.1,0) [0|0] "" Vector__XXX
 SG_ BMS_cacLowerBoundBrick36 m35 : 35|13@1+ (0.1,0) [0|0] "" Vector__XXX
 SG_ BMS_cacLowerBoundBrick37 m36 : 35|13@1+ (0.1,0) [0|0] "" Vector__XXX
 SG_ BMS_cacLowerBoundBrick38 m37 : 35|13@1+ (0.1,0) [0|0] "" Vector__XXX
 SG_ BMS_cacLowerBoundBrick39 m38 : 35|13@1+ (0.1,0) [0|0] "" Vector__XXX
 SG_ BMS_cacLowerBoundBrick4 m3 : 35|13@1+ (0.1,0) [0|0] "" Vector__XXX
 SG_ BMS_cacLowerBoundBrick40 m39 : 35|13@1+ (0.1,0) [0|0] "" Vector__XXX
 SG_ BMS_cacLowerBoundBrick41 m40 : 35|13@1+ (0.1,0) [0|0] "" Vector__XXX
 SG_ BMS_cacLowerBoundBrick42 m41 : 35|13@1+ (0.1,0) [0|0] "" Vector__XXX
 SG_ BMS_cacLowerBoundBrick43 m42 : 35|13@1+ (0.1,0) [0|0] "" Vector__XXX
 SG_ BMS_cacLowerBoundBrick44 m43 : 35|13@1+ (0.1,0) [0|0] "" Vector__XXX
 SG_ BMS_cacLowerBoundBrick45 m44 : 35|13@1+ (0.1,0) [0|0] "" Vector__XXX
 SG_ BMS_cacLowerBoundBrick46 m45 : 35|13@1+ (0.1,0) [0|0] "" Vector__XXX
 SG_ BMS_cacLowerBoundBrick47 m46 : 35|13@1+ (0.1,0) [0|0] "" Vector__XXX
 SG_ BMS_cacLowerBoundBrick48 m47 : 35|13@1+ (0.1,0) [0|0] "" Vector__XXX
 SG_ BMS_cacLowerBoundBrick49 m48 : 35|13@1+ (0.1,0) [0|0] "" Vector__XXX
 SG_ BMS_cacLowerBoundBrick5 m4 : 35|13@1+ (0.1,0) [0|0] "" Vector__XXX
 SG_ BMS_cacLowerBoundBrick50 m49 : 35|13@1+ (0.1,0) [0|0] "" Vector__XXX
 SG_ BMS_cacLowerBoundBrick51 m50 : 35|13@1+ (0.1,0) [0|0] "" Vector__XXX
 SG_ BMS_cacLowerBoundBrick52 m51 : 35|13@1+ (0.1,0) [0|0] "" Vector__XXX
 SG_ BMS_cacLowerBoundBrick53 m52 : 35|13@1+ (0.1,0) [0|0] "" Vector__XXX
 SG_ BMS_cacLowerBoundBrick54 m53 : 35|13@1+ (0.1,0) [0|0] "" Vector__XXX
 SG_ BMS_cacLowerBoundBrick55 m54 : 35|13@1+ (0.1,0) [0|0] "" Vector__XXX
 SG_ BMS_cacLowerBoundBrick56 m55 : 35|13@1+ (0.1,0) [0|0] "" Vector__XXX
 SG_ BMS_cacLowerBoundBrick57 m56 : 35|13@1+ (0.1,0) [0|0] "" Vector__XXX
 SG_ BMS_cacLowerBoundBrick58 m57 : 35|13@1+ (0.1,0) [0|0] "" Vector__XXX
 SG_ BMS_cacLowerBoundBrick59 m58 : 35|13@1+ (0.1,0) [0|0] "" Vector__XXX
 SG_ BMS_cacLowerBoundBrick6 m5 : 35|13@1+ (0.1,0) [0|0] "" Vector__XXX
 SG_ BMS_cacLowerBoundBrick60 m59 : 35|13@1+ (0.1,0) [0|0] "" Vector__XXX
 SG_ BMS_cacLowerBoundBrick61 m60 : 35|13@1+ (0.1,0) [0|0] "" Vector__XXX
 SG_ BMS_cacLowerBoundBrick62 m61 : 35|13@1+ (0.1,0) [0|0] "" Vector__XXX
 SG_ BMS_cacLowerBoundBrick63 m62 : 35|13@1+ (0.1,0) [0|0] "" Vector__XXX
 SG_ BMS_cacLowerBoundBrick64 m63 : 35|13@1+ (0.1,0) [0|0] "" Vector__XXX
 SG_ BMS_cacLowerBoundBrick65 m64 : 35|13@1+ (0.1,0) [0|0] "" Vector__XXX
 SG_ BMS_cacLowerBoundBrick66 m65 : 35|13@1+ (0.1,0) [0|0] "" Vector__XXX
 SG_ BMS_cacLowerBoundBrick67 m66 : 35|13@1+ (0.1,0) [0|0] "" Vector__XXX
 SG_ BMS_cacLowerBoundBrick68 m67 : 35|13@1+ (0.1,0) [0|0] "" Vector__XXX
 SG_ BMS_cacLowerBoundBrick69 m68 : 35|13@1+ (0.1,0) [0|0] "" Vector__XXX
 SG_ BMS_cacLowerBoundBrick7 m6 : 35|13@1+ (0.1,0) [0|0] "" Vector__XXX
 SG_ BMS_cacLowerBoundBrick70 m69 : 35|13@1+ (0.1,0) [0|0] "" Vector__XXX
 SG_ BMS_cacLowerBoundBrick71 m70 : 35|13@1+ (0.1,0) [0|0] "" Vector__XXX
 SG_ BMS_cacLowerBoundBrick72 m71 : 35|13@1+ (0.1,0) [0|0] "" Vector__XXX
 SG_ BMS_cacLowerBoundBrick73 m72 : 35|13@1+ (0.1,0) [0|0] "" Vector__XXX
 SG_ BMS_cacLowerBoundBrick74 m73 : 35|13@1+ (0.1,0) [0|0] "" Vector__XXX
 SG_ BMS_cacLowerBoundBrick75 m74 : 35|13@1+ (0.1,0) [0|0] "" Vector__XXX
 SG_ BMS_cacLowerBoundBrick76 m75 : 35|13@1+ (0.1,0) [0|0] "" Vector__XXX
 SG_ BMS_cacLowerBoundBrick77 m76 : 35|13@1+ (0.1,0) [0|0] "" Vector__XXX
 SG_ BMS_cacLowerBoundBrick78 m77 : 35|13@1+ (0.1,0) [0|0] "" Vector__XXX
 SG_ BMS_cacLowerBoundBrick79 m78 : 35|13@1+ (0.1,0) [0|0] "" Vector__XXX
 SG_ BMS_cacLowerBoundBrick8 m7 : 35|13@1+ (0.1,0) [0|0] "" Vector__XXX
 SG_ BMS_cacLowerBoundBrick80 m79 : 35|13@1+ (0.1,0) [0|0] "" Vector__XXX
 SG_ BMS_cacLowerBoundBrick81 m80 : 35|13@1+ (0.1,0) [0|0] "" Vector__XXX
 SG_ BMS_cacLowerBoundBrick82 m81 : 35|13@1+ (0.1,0) [0|0] "" Vector__XXX
 SG_ BMS_cacLowerBoundBrick83 m82 : 35|13@1+ (0.1,0) [0|0] "" Vector__XXX
 SG_ BMS_cacLowerBoundBrick84 m83 : 35|13@1+ (0.1,0) [0|0] "" Vector__XXX
 SG_ BMS_cacLowerBoundBrick85 m84 : 35|13@1+ (0.1,0) [0|0] "" Vector__XXX
 SG_ BMS_cacLowerBoundBrick86 m85 : 35|13@1+ (0.1,0) [0|0] "" Vector__XXX
 SG_ BMS_cacLowerBoundBrick87 m86 : 35|13@1+ (0.1,0) [0|0] "" Vector__XXX
 SG_ BMS_cacLowerBoundBrick88 m87 : 35|13@1+ (0.1,0) [0|0] "" Vector__XXX
 SG_ BMS_cacLowerBoundBrick89 m88 : 35|13@1+ (0.1,0) [0|0] "" Vector__XXX
 SG_ BMS_cacLowerBoundBrick9 m8 : 35|13@1+ (0.1,0) [0|0] "" Vector__XXX
 SG_ BMS_cacLowerBoundBrick90 m89 : 35|13@1+ (0.1,0) [0|0] "" Vector__XXX
 SG_ BMS_cacLowerBoundBrick91 m90 : 35|13@1+ (0.1,0) [0|0] "" Vector__XXX
 SG_ BMS_cacLowerBoundBrick92 m91 : 35|13@1+ (0.1,0) [0|0] "" Vector__XXX
 SG_ BMS_cacLowerBoundBrick93 m92 : 35|13@1+ (0.1,0) [0|0] "" Vector__XXX
 SG_ BMS_cacLowerBoundBrick94 m93 : 35|13@1+ (0.1,0) [0|0] "" Vector__XXX
 SG_ BMS_cacLowerBoundBrick95 m94 : 35|13@1+ (0.1,0) [0|0] "" Vector__XXX
 SG_ BMS_cacLowerBoundBrick96 m95 : 35|13@1+ (0.1,0) [0|0] "" Vector__XXX
 SG_ BMS_cacLowerBoundBrick97 m96 : 35|13@1+ (0.1,0) [0|0] "" Vector__XXX
 SG_ BMS_cacLowerBoundBrick98 m97 : 35|13@1+ (0.1,0) [0|0] "" Vector__XXX
 SG_ BMS_cacLowerBoundBrick99 m98 : 35|13@1+ (0.1,0) [0|0] "" Vector__XXX
 SG_ BMS_cacBrick1 m0 : 22|13@1+ (0.1,0) [0|0] "" Vector__XXX
 SG_ BMS_cacBrick10 m9 : 22|13@1+ (0.1,0) [0|0] "" Vector__XXX
 SG_ BMS_cacBrick100 m99 : 22|13@1+ (0.1,0) [0|0] "" Vector__XXX
 SG_ BMS_cacBrick101 m100 : 22|13@1+ (0.1,0) [0|0] "" Vector__XXX
 SG_ BMS_cacBrick102 m101 : 22|13@1+ (0.1,0) [0|0] "" Vector__XXX
 SG_ BMS_cacBrick103 m102 : 22|13@1+ (0.1,0) [0|0] "" Vector__XXX
 SG_ BMS_cacBrick104 m103 : 22|13@1+ (0.1,0) [0|0] "" Vector__XXX
 SG_ BMS_cacBrick105 m104 : 22|13@1+ (0.1,0) [0|0] "" Vector__XXX
 SG_ BMS_cacBrick106 m105 : 22|13@1+ (0.1,0) [0|0] "" Vector__XXX
 SG_ BMS_cacBrick107 m106 : 22|13@1+ (0.1,0) [0|0] "" Vector__XXX
 SG_ BMS_cacBrick108 m107 : 22|13@1+ (0.1,0) [0|0] "" Vector__XXX
 SG_ BMS_cacBrick11 m10 : 22|13@1+ (0.1,0) [0|0] "" Vector__XXX
 SG_ BMS_cacBrick12 m11 : 22|13@1+ (0.1,0) [0|0] "" Vector__XXX
 SG_ BMS_cacBrick13 m12 : 22|13@1+ (0.1,0) [0|0] "" Vector__XXX
 SG_ BMS_cacBrick14 m13 : 22|13@1+ (0.1,0) [0|0] "" Vector__XXX
 SG_ BMS_cacBrick15 m14 : 22|13@1+ (0.1,0) [0|0] "" Vector__XXX
 SG_ BMS_cacBrick16 m15 : 22|13@1+ (0.1,0) [0|0] "" Vector__XXX
 SG_ BMS_cacBrick17 m16 : 22|13@1+ (0.1,0) [0|0] "" Vector__XXX
 SG_ BMS_cacBrick18 m17 : 22|13@1+ (0.1,0) [0|0] "" Vector__XXX
 SG_ BMS_cacBrick19 m18 : 22|13@1+ (0.1,0) [0|0] "" Vector__XXX
 SG_ BMS_cacBrick2 m1 : 22|13@1+ (0.1,0) [0|0] "" Vector__XXX
 SG_ BMS_cacBrick20 m19 : 22|13@1+ (0.1,0) [0|0] "" Vector__XXX
 SG_ BMS_cacBrick21 m20 : 22|13@1+ (0.1,0) [0|0] "" Vector__XXX
 SG_ BMS_cacBrick22 m21 : 22|13@1+ (0.1,0) [0|0] "" Vector__XXX
 SG_ BMS_cacBrick23 m22 : 22|13@1+ (0.1,0) [0|0] "" Vector__XXX
 SG_ BMS_cacBrick24 m23 : 22|13@1+ (0.1,0) [0|0] "" Vector__XXX
 SG_ BMS_cacBrick25 m24 : 22|13@1+ (0.1,0) [0|0] "" Vector__XXX
 SG_ BMS_cacBrick26 m25 : 22|13@1+ (0.1,0) [0|0] "" Vector__XXX
 SG_ BMS_cacBrick27 m26 : 22|13@1+ (0.1,0) [0|0] "" Vector__XXX
 SG_ BMS_cacBrick28 m27 : 22|13@1+ (0.1,0) [0|0] "" Vector__XXX
 SG_ BMS_cacBrick29 m28 : 22|13@1+ (0.1,0) [0|0] "" Vector__XXX
 SG_ BMS_cacBrick3 m2 : 22|13@1+ (0.1,0) [0|0] "" Vector__XXX
 SG_ BMS_cacBrick30 m29 : 22|13@1+ (0.1,0) [0|0] "" Vector__XXX
 SG_ BMS_cacBrick31 m30 : 22|13@1+ (0.1,0) [0|0] "" Vector__XXX
 SG_ BMS_cacBrick32 m31 : 22|13@1+ (0.1,0) [0|0] "" Vector__XXX
 SG_ BMS_cacBrick33 m32 : 22|13@1+ (0.1,0) [0|0] "" Vector__XXX
 SG_ BMS_cacBrick34 m33 : 22|13@1+ (0.1,0) [0|0] "" Vector__XXX
 SG_ BMS_cacBrick35 m34 : 22|13@1+ (0.1,0) [0|0] "" Vector__XXX
 SG_ BMS_cacBrick36 m35 : 22|13@1+ (0.1,0) [0|0] "" Vector__XXX
 SG_ BMS_cacBrick37 m36 : 22|13@1+ (0.1,0) [0|0] "" Vector__XXX
 SG_ BMS_cacBrick38 m37 : 22|13@1+ (0.1,0) [0|0] "" Vector__XXX
 SG_ BMS_cacBrick39 m38 : 22|13@1+ (0.1,0) [0|0] "" Vector__XXX
 SG_ BMS_cacBrick4 m3 : 22|13@1+ (0.1,0) [0|0] "" Vector__XXX
 SG_ BMS_cacBrick40 m39 : 22|13@1+ (0.1,0) [0|0] "" Vector__XXX
 SG_ BMS_cacBrick41 m40 : 22|13@1+ (0.1,0) [0|0] "" Vector__XXX
 SG_ BMS_cacBrick42 m41 : 22|13@1+ (0.1,0) [0|0] "" Vector__XXX
 SG_ BMS_cacBrick43 m42 : 22|13@1+ (0.1,0) [0|0] "" Vector__XXX
 SG_ BMS_cacBrick44 m43 : 22|13@1+ (0.1,0) [0|0] "" Vector__XXX
 SG_ BMS_cacBrick45 m44 : 22|13@1+ (0.1,0) [0|0] "" Vector__XXX
 SG_ BMS_cacBrick46 m45 : 22|13@1+ (0.1,0) [0|0] "" Vector__XXX
 SG_ BMS_cacBrick47 m46 : 22|13@1+ (0.1,0) [0|0] "" Vector__XXX
 SG_ BMS_cacBrick48 m47 : 22|13@1+ (0.1,0) [0|0] "" Vector__XXX
 SG_ BMS_cacBrick49 m48 : 22|13@1+ (0.1,0) [0|0] "" Vector__XXX
 SG_ BMS_cacBrick5 m4 : 22|13@1+ (0.1,0) [0|0] "" Vector__XXX
 SG_ BMS_cacBrick50 m49 : 22|13@1+ (0.1,0) [0|0] "" Vector__XXX
 SG_ BMS_cacBrick51 m50 : 22|13@1+ (0.1,0) [0|0] "" Vector__XXX
 SG_ BMS_cacBrick52 m51 : 22|13@1+ (0.1,0) [0|0] "" Vector__XXX
 SG_ BMS_cacBrick53 m52 : 22|13@1+ (0.1,0) [0|0] "" Vector__XXX
 SG_ BMS_cacBrick54 m53 : 22|13@1+ (0.1,0) [0|0] "" Vector__XXX
 SG_ BMS_cacBrick55 m54 : 22|13@1+ (0.1,0) [0|0] "" Vector__XXX
 SG_ BMS_cacBrick56 m55 : 22|13@1+ (0.1,0) [0|0] "" Vector__XXX
 SG_ BMS_cacBrick57 m56 : 22|13@1+ (0.1,0) [0|0] "" Vector__XXX
 SG_ BMS_cacBrick58 m57 : 22|13@1+ (0.1,0) [0|0] "" Vector__XXX
 SG_ BMS_cacBrick59 m58 : 22|13@1+ (0.1,0) [0|0] "" Vector__XXX
 SG_ BMS_cacBrick6 m5 : 22|13@1+ (0.1,0) [0|0] "" Vector__XXX
 SG_ BMS_cacBrick60 m59 : 22|13@1+ (0.1,0) [0|0] "" Vector__XXX
 SG_ BMS_cacBrick61 m60 : 22|13@1+ (0.1,0) [0|0] "" Vector__XXX
 SG_ BMS_cacBrick62 m61 : 22|13@1+ (0.1,0) [0|0] "" Vector__XXX
 SG_ BMS_cacBrick63 m62 : 22|13@1+ (0.1,0) [0|0] "" Vector__XXX
 SG_ BMS_cacBrick64 m63 : 22|13@1+ (0.1,0) [0|0] "" Vector__XXX
 SG_ BMS_cacBrick65 m64 : 22|13@1+ (0.1,0) [0|0] "" Vector__XXX
 SG_ BMS_cacBrick66 m65 : 22|13@1+ (0.1,0) [0|0] "" Vector__XXX
 SG_ BMS_cacBrick67 m66 : 22|13@1+ (0.1,0) [0|0] "" Vector__XXX
 SG_ BMS_cacBrick68 m67 : 22|13@1+ (0.1,0) [0|0] "" Vector__XXX
 SG_ BMS_cacBrick69 m68 : 22|13@1+ (0.1,0) [0|0] "" Vector__XXX
 SG_ BMS_cacBrick7 m6 : 22|13@1+ (0.1,0) [0|0] "" Vector__XXX
 SG_ BMS_cacBrick70 m69 : 22|13@1+ (0.1,0) [0|0] "" Vector__XXX
 SG_ BMS_cacBrick71 m70 : 22|13@1+ (0.1,0) [0|0] "" Vector__XXX
 SG_ BMS_cacBrick72 m71 : 22|13@1+ (0.1,0) [0|0] "" Vector__XXX
 SG_ BMS_cacBrick73 m72 : 22|13@1+ (0.1,0) [0|0] "" Vector__XXX
 SG_ BMS_cacBrick74 m73 : 22|13@1+ (0.1,0) [0|0] "" Vector__XXX
 SG_ BMS_cacBrick75 m74 : 22|13@1+ (0.1,0) [0|0] "" Vector__XXX
 SG_ BMS_cacBrick76 m75 : 22|13@1+ (0.1,0) [0|0] "" Vector__XXX
 SG_ BMS_cacBrick77 m76 : 22|13@1+ (0.1,0) [0|0] "" Vector__XXX
 SG_ BMS_cacBrick78 m77 : 22|13@1+ (0.1,0) [0|0] "" Vector__XXX
 SG_ BMS_cacBrick79 m78 : 22|13@1+ (0.1,0) [0|0] "" Vector__XXX
 SG_ BMS_cacBrick8 m7 : 22|13@1+ (0.1,0) [0|0] "" Vector__XXX
 SG_ BMS_cacBrick80 m79 : 22|13@1+ (0.1,0) [0|0] "" Vector__XXX
 SG_ BMS_cacBrick81 m80 : 22|13@1+ (0.1,0) [0|0] "" Vector__XXX
 SG_ BMS_cacBrick82 m81 : 22|13@1+ (0.1,0) [0|0] "" Vector__XXX
 SG_ BMS_cacBrick83 m82 : 22|13@1+ (0.1,0) [0|0] "" Vector__XXX
 SG_ BMS_cacBrick84 m83 : 22|13@1+ (0.1,0) [0|0] "" Vector__XXX
 SG_ BMS_cacBrick85 m84 : 22|13@1+ (0.1,0) [0|0] "" Vector__XXX
 SG_ BMS_cacBrick86 m85 : 22|13@1+ (0.1,0) [0|0] "" Vector__XXX
 SG_ BMS_cacBrick87 m86 : 22|13@1+ (0.1,0) [0|0] "" Vector__XXX
 SG_ BMS_cacBrick88 m87 : 22|13@1+ (0.1,0) [0|0] "" Vector__XXX
 SG_ BMS_cacBrick89 m88 : 22|13@1+ (0.1,0) [0|0] "" Vector__XXX
 SG_ BMS_cacBrick9 m8 : 22|13@1+ (0.1,0) [0|0] "" Vector__XXX
 SG_ BMS_cacBrick90 m89 : 22|13@1+ (0.1,0) [0|0] "" Vector__XXX
 SG_ BMS_cacBrick91 m90 : 22|13@1+ (0.1,0) [0|0] "" Vector__XXX
 SG_ BMS_cacBrick92 m91 : 22|13@1+ (0.1,0) [0|0] "" Vector__XXX
 SG_ BMS_cacBrick93 m92 : 22|13@1+ (0.1,0) [0|0] "" Vector__XXX
 SG_ BMS_cacBrick94 m93 : 22|13@1+ (0.1,0) [0|0] "" Vector__XXX
 SG_ BMS_cacBrick95 m94 : 22|13@1+ (0.1,0) [0|0] "" Vector__XXX
 SG_ BMS_cacBrick96 m95 : 22|13@1+ (0.1,0) [0|0] "" Vector__XXX
 SG_ BMS_cacBrick97 m96 : 22|13@1+ (0.1,0) [0|0] "" Vector__XXX
 SG_ BMS_cacBrick98 m97 : 22|13@1+ (0.1,0) [0|0] "" Vector__XXX
 SG_ BMS_cacBrick99 m98 : 22|13@1+ (0.1,0) [0|0] "" Vector__XXX
 SG_ BMS_dSocAlphaBrick1 m0 : 8|14@1- (0.0030517578125,0) [0|0] "" Vector__XXX
 SG_ BMS_dSocAlphaBrick10 m9 : 8|14@1- (0.0030517578125,0) [0|0] "" Vector__XXX
 SG_ BMS_dSocAlphaBrick100 m99 : 8|14@1- (0.0030517578125,0) [0|0] "" Vector__XXX
 SG_ BMS_dSocAlphaBrick101 m100 : 8|14@1- (0.0030517578125,0) [0|0] "" Vector__XXX
 SG_ BMS_dSocAlphaBrick102 m101 : 8|14@1- (0.0030517578125,0) [0|0] "" Vector__XXX
 SG_ BMS_dSocAlphaBrick103 m102 : 8|14@1- (0.0030517578125,0) [0|0] "" Vector__XXX
 SG_ BMS_dSocAlphaBrick104 m103 : 8|14@1- (0.0030517578125,0) [0|0] "" Vector__XXX
 SG_ BMS_dSocAlphaBrick105 m104 : 8|14@1- (0.0030517578125,0) [0|0] "" Vector__XXX
 SG_ BMS_dSocAlphaBrick106 m105 : 8|14@1- (0.0030517578125,0) [0|0] "" Vector__XXX
 SG_ BMS_dSocAlphaBrick107 m106 : 8|14@1- (0.0030517578125,0) [0|0] "" Vector__XXX
 SG_ BMS_dSocAlphaBrick108 m107 : 8|14@1- (0.0030517578125,0) [0|0] "" Vector__XXX
 SG_ BMS_dSocAlphaBrick11 m10 : 8|14@1- (0.0030517578125,0) [0|0] "" Vector__XXX
 SG_ BMS_dSocAlphaBrick12 m11 : 8|14@1- (0.0030517578125,0) [0|0] "" Vector__XXX
 SG_ BMS_dSocAlphaBrick13 m12 : 8|14@1- (0.0030517578125,0) [0|0] "" Vector__XXX
 SG_ BMS_dSocAlphaBrick14 m13 : 8|14@1- (0.0030517578125,0) [0|0] "" Vector__XXX
 SG_ BMS_dSocAlphaBrick15 m14 : 8|14@1- (0.0030517578125,0) [0|0] "" Vector__XXX
 SG_ BMS_dSocAlphaBrick16 m15 : 8|14@1- (0.0030517578125,0) [0|0] "" Vector__XXX
 SG_ BMS_dSocAlphaBrick17 m16 : 8|14@1- (0.0030517578125,0) [0|0] "" Vector__XXX
 SG_ BMS_dSocAlphaBrick18 m17 : 8|14@1- (0.0030517578125,0) [0|0] "" Vector__XXX
 SG_ BMS_dSocAlphaBrick19 m18 : 8|14@1- (0.0030517578125,0) [0|0] "" Vector__XXX
 SG_ BMS_dSocAlphaBrick2 m1 : 8|14@1- (0.0030517578125,0) [0|0] "" Vector__XXX
 SG_ BMS_dSocAlphaBrick20 m19 : 8|14@1- (0.0030517578125,0) [0|0] "" Vector__XXX
 SG_ BMS_dSocAlphaBrick21 m20 : 8|14@1- (0.0030517578125,0) [0|0] "" Vector__XXX
 SG_ BMS_dSocAlphaBrick22 m21 : 8|14@1- (0.0030517578125,0) [0|0] "" Vector__XXX
 SG_ BMS_dSocAlphaBrick23 m22 : 8|14@1- (0.0030517578125,0) [0|0] "" Vector__XXX
 SG_ BMS_dSocAlphaBrick24 m23 : 8|14@1- (0.0030517578125,0) [0|0] "" Vector__XXX
 SG_ BMS_dSocAlphaBrick25 m24 : 8|14@1- (0.0030517578125,0) [0|0] "" Vector__XXX
 SG_ BMS_dSocAlphaBrick26 m25 : 8|14@1- (0.0030517578125,0) [0|0] "" Vector__XXX
 SG_ BMS_dSocAlphaBrick27 m26 : 8|14@1- (0.0030517578125,0) [0|0] "" Vector__XXX
 SG_ BMS_dSocAlphaBrick28 m27 : 8|14@1- (0.0030517578125,0) [0|0] "" Vector__XXX
 SG_ BMS_dSocAlphaBrick29 m28 : 8|14@1- (0.0030517578125,0) [0|0] "" Vector__XXX
 SG_ BMS_dSocAlphaBrick3 m2 : 8|14@1- (0.0030517578125,0) [0|0] "" Vector__XXX
 SG_ BMS_dSocAlphaBrick30 m29 : 8|14@1- (0.0030517578125,0) [0|0] "" Vector__XXX
 SG_ BMS_dSocAlphaBrick31 m30 : 8|14@1- (0.0030517578125,0) [0|0] "" Vector__XXX
 SG_ BMS_dSocAlphaBrick32 m31 : 8|14@1- (0.0030517578125,0) [0|0] "" Vector__XXX
 SG_ BMS_dSocAlphaBrick33 m32 : 8|14@1- (0.0030517578125,0) [0|0] "" Vector__XXX
 SG_ BMS_dSocAlphaBrick34 m33 : 8|14@1- (0.0030517578125,0) [0|0] "" Vector__XXX
 SG_ BMS_dSocAlphaBrick35 m34 : 8|14@1- (0.0030517578125,0) [0|0] "" Vector__XXX
 SG_ BMS_dSocAlphaBrick36 m35 : 8|14@1- (0.0030517578125,0) [0|0] "" Vector__XXX
 SG_ BMS_dSocAlphaBrick37 m36 : 8|14@1- (0.0030517578125,0) [0|0] "" Vector__XXX
 SG_ BMS_dSocAlphaBrick38 m37 : 8|14@1- (0.0030517578125,0) [0|0] "" Vector__XXX
 SG_ BMS_dSocAlphaBrick39 m38 : 8|14@1- (0.0030517578125,0) [0|0] "" Vector__XXX
 SG_ BMS_dSocAlphaBrick4 m3 : 8|14@1- (0.0030517578125,0) [0|0] "" Vector__XXX
 SG_ BMS_dSocAlphaBrick40 m39 : 8|14@1- (0.0030517578125,0) [0|0] "" Vector__XXX
 SG_ BMS_dSocAlphaBrick41 m40 : 8|14@1- (0.0030517578125,0) [0|0] "" Vector__XXX
 SG_ BMS_dSocAlphaBrick42 m41 : 8|14@1- (0.0030517578125,0) [0|0] "" Vector__XXX
 SG_ BMS_dSocAlphaBrick43 m42 : 8|14@1- (0.0030517578125,0) [0|0] "" Vector__XXX
 SG_ BMS_dSocAlphaBrick44 m43 : 8|14@1- (0.0030517578125,0) [0|0] "" Vector__XXX
 SG_ BMS_dSocAlphaBrick45 m44 : 8|14@1- (0.0030517578125,0) [0|0] "" Vector__XXX
 SG_ BMS_dSocAlphaBrick46 m45 : 8|14@1- (0.0030517578125,0) [0|0] "" Vector__XXX
 SG_ BMS_dSocAlphaBrick47 m46 : 8|14@1- (0.0030517578125,0) [0|0] "" Vector__XXX
 SG_ BMS_dSocAlphaBrick48 m47 : 8|14@1- (0.0030517578125,0) [0|0] "" Vector__XXX
 SG_ BMS_dSocAlphaBrick49 m48 : 8|14@1- (0.0030517578125,0) [0|0] "" Vector__XXX
 SG_ BMS_dSocAlphaBrick5 m4 : 8|14@1- (0.0030517578125,0) [0|0] "" Vector__XXX
 SG_ BMS_dSocAlphaBrick50 m49 : 8|14@1- (0.0030517578125,0) [0|0] "" Vector__XXX
 SG_ BMS_dSocAlphaBrick51 m50 : 8|14@1- (0.0030517578125,0) [0|0] "" Vector__XXX
 SG_ BMS_dSocAlphaBrick52 m51 : 8|14@1- (0.0030517578125,0) [0|0] "" Vector__XXX
 SG_ BMS_dSocAlphaBrick53 m52 : 8|14@1- (0.0030517578125,0) [0|0] "" Vector__XXX
 SG_ BMS_dSocAlphaBrick54 m53 : 8|14@1- (0.0030517578125,0) [0|0] "" Vector__XXX
 SG_ BMS_dSocAlphaBrick55 m54 : 8|14@1- (0.0030517578125,0) [0|0] "" Vector__XXX
 SG_ BMS_dSocAlphaBrick56 m55 : 8|14@1- (0.0030517578125,0) [0|0] "" Vector__XXX
 SG_ BMS_dSocAlphaBrick57 m56 : 8|14@1- (0.0030517578125,0) [0|0] "" Vector__XXX
 SG_ BMS_dSocAlphaBrick58 m57 : 8|14@1- (0.0030517578125,0) [0|0] "" Vector__XXX
 SG_ BMS_dSocAlphaBrick59 m58 : 8|14@1- (0.0030517578125,0) [0|0] "" Vector__XXX
 SG_ BMS_dSocAlphaBrick6 m5 : 8|14@1- (0.0030517578125,0) [0|0] "" Vector__XXX
 SG_ BMS_dSocAlphaBrick60 m59 : 8|14@1- (0.0030517578125,0) [0|0] "" Vector__XXX
 SG_ BMS_dSocAlphaBrick61 m60 : 8|14@1- (0.0030517578125,0) [0|0] "" Vector__XXX
 SG_ BMS_dSocAlphaBrick62 m61 : 8|14@1- (0.0030517578125,0) [0|0] "" Vector__XXX
 SG_ BMS_dSocAlphaBrick63 m62 : 8|14@1- (0.0030517578125,0) [0|0] "" Vector__XXX
 SG_ BMS_dSocAlphaBrick64 m63 : 8|14@1- (0.0030517578125,0) [0|0] "" Vector__XXX
 SG_ BMS_dSocAlphaBrick65 m64 : 8|14@1- (0.0030517578125,0) [0|0] "" Vector__XXX
 SG_ BMS_dSocAlphaBrick66 m65 : 8|14@1- (0.0030517578125,0) [0|0] "" Vector__XXX
 SG_ BMS_dSocAlphaBrick67 m66 : 8|14@1- (0.0030517578125,0) [0|0] "" Vector__XXX
 SG_ BMS_dSocAlphaBrick68 m67 : 8|14@1- (0.0030517578125,0) [0|0] "" Vector__XXX
 SG_ BMS_dSocAlphaBrick69 m68 : 8|14@1- (0.0030517578125,0) [0|0] "" Vector__XXX
 SG_ BMS_dSocAlphaBrick7 m6 : 8|14@1- (0.0030517578125,0) [0|0] "" Vector__XXX
 SG_ BMS_dSocAlphaBrick70 m69 : 8|14@1- (0.0030517578125,0) [0|0] "" Vector__XXX
 SG_ BMS_dSocAlphaBrick71 m70 : 8|14@1- (0.0030517578125,0) [0|0] "" Vector__XXX
 SG_ BMS_dSocAlphaBrick72 m71 : 8|14@1- (0.0030517578125,0) [0|0] "" Vector__XXX
 SG_ BMS_dSocAlphaBrick73 m72 : 8|14@1- (0.0030517578125,0) [0|0] "" Vector__XXX
 SG_ BMS_dSocAlphaBrick74 m73 : 8|14@1- (0.0030517578125,0) [0|0] "" Vector__XXX
 SG_ BMS_dSocAlphaBrick75 m74 : 8|14@1- (0.0030517578125,0) [0|0] "" Vector__XXX
 SG_ BMS_dSocAlphaBrick76 m75 : 8|14@1- (0.0030517578125,0) [0|0] "" Vector__XXX
 SG_ BMS_dSocAlphaBrick77 m76 : 8|14@1- (0.0030517578125,0) [0|0] "" Vector__XXX
 SG_ BMS_dSocAlphaBrick78 m77 : 8|14@1- (0.0030517578125,0) [0|0] "" Vector__XXX
 SG_ BMS_dSocAlphaBrick79 m78 : 8|14@1- (0.0030517578125,0) [0|0] "" Vector__XXX
 SG_ BMS_dSocAlphaBrick8 m7 : 8|14@1- (0.0030517578125,0) [0|0] "" Vector__XXX
 SG_ BMS_dSocAlphaBrick80 m79 : 8|14@1- (0.0030517578125,0) [0|0] "" Vector__XXX
 SG_ BMS_dSocAlphaBrick81 m80 : 8|14@1- (0.0030517578125,0) [0|0] "" Vector__XXX
 SG_ BMS_dSocAlphaBrick82 m81 : 8|14@1- (0.0030517578125,0) [0|0] "" Vector__XXX
 SG_ BMS_dSocAlphaBrick83 m82 : 8|14@1- (0.0030517578125,0) [0|0] "" Vector__XXX
 SG_ BMS_dSocAlphaBrick84 m83 : 8|14@1- (0.0030517578125,0) [0|0] "" Vector__XXX
 SG_ BMS_dSocAlphaBrick85 m84 : 8|14@1- (0.0030517578125,0) [0|0] "" Vector__XXX
 SG_ BMS_dSocAlphaBrick86 m85 : 8|14@1- (0.0030517578125,0) [0|0] "" Vector__XXX
 SG_ BMS_dSocAlphaBrick87 m86 : 8|14@1- (0.0030517578125,0) [0|0] "" Vector__XXX
 SG_ BMS_dSocAlphaBrick88 m87 : 8|14@1- (0.0030517578125,0) [0|0] "" Vector__XXX
 SG_ BMS_dSocAlphaBrick89 m88 : 8|14@1- (0.0030517578125,0) [0|0] "" Vector__XXX
 SG_ BMS_dSocAlphaBrick9 m8 : 8|14@1- (0.0030517578125,0) [0|0] "" Vector__XXX
 SG_ BMS_dSocAlphaBrick90 m89 : 8|14@1- (0.0030517578125,0) [0|0] "" Vector__XXX
 SG_ BMS_dSocAlphaBrick91 m90 : 8|14@1- (0.0030517578125,0) [0|0] "" Vector__XXX
 SG_ BMS_dSocAlphaBrick92 m91 : 8|14@1- (0.0030517578125,0) [0|0] "" Vector__XXX
 SG_ BMS_dSocAlphaBrick93 m92 : 8|14@1- (0.0030517578125,0) [0|0] "" Vector__XXX
 SG_ BMS_dSocAlphaBrick94 m93 : 8|14@1- (0.0030517578125,0) [0|0] "" Vector__XXX
 SG_ BMS_dSocAlphaBrick95 m94 : 8|14@1- (0.0030517578125,0) [0|0] "" Vector__XXX
 SG_ BMS_dSocAlphaBrick96 m95 : 8|14@1- (0.0030517578125,0) [0|0] "" Vector__XXX
 SG_ BMS_dSocAlphaBrick97 m96 : 8|14@1- (0.0030517578125,0) [0|0] "" Vector__XXX
 SG_ BMS_dSocAlphaBrick98 m97 : 8|14@1- (0.0030517578125,0) [0|0] "" Vector__XXX
 SG_ BMS_dSocAlphaBrick99 m98 : 8|14@1- (0.0030517578125,0) [0|0] "" Vector__XXX
 SG_ BMS_log3MuxId M : 0|8@1+ (1,0) [0|0] "" Vector__XXX

BO_ 1924 XCP_pmfRequest: 12 Vector__XXX
 SG_ XCP_pmfRequestData : 7|64@0+ (1,0) [0|0] "" Vector__XXX

BO_ 1926 DBG_dynoVehicleSim: 8 Vector__XXX
 SG_ DBG_wheelSpeedReR : 48|12@1+ (0.08,-40) [0|0] "" Vector__XXX
 SG_ DBG_wheelSpeedReL : 36|12@1+ (0.08,-40) [0|0] "" Vector__XXX
 SG_ DBG_wheelSpeedFrR : 24|12@1+ (0.08,-40) [0|0] "" Vector__XXX
 SG_ DBG_wheelSpeedFrL : 12|12@1+ (0.08,-40) [0|0] "" Vector__XXX
 SG_ DBG_vehicleSpeed : 0|12@1+ (0.08,-40) [0|0] "" Vector__XXX

BO_ 1928 EPBL_debugOutput: 8 Vector__XXX
 SG_ EPBL_uiNotAvailable m0 : 62|1@1+ (1,0) [0|0] "" Vector__XXX
 SG_ EPBL_driverIsLeavingDisabled m0 : 61|1@1+ (1,0) [0|0] "" Vector__XXX
 SG_ EPBL_slopeParkable m0 : 60|1@1+ (1,0) [0|0] "" Vector__XXX
 SG_ EPBL_epbOpenUnableToPark m0 : 59|1@1+ (1,0) [0|0] "" Vector__XXX
 SG_ EPBL_brakePressHeld m0 : 58|1@1+ (1,0) [0|0] "" Vector__XXX
 SG_ EPBL_esmCaliperRequest m0 : 55|3@1+ (1,0) [0|0] "" Vector__XXX
 SG_ EPBL_12VFilt m1 : 52|9@1+ (0.043549408784,0) [0|0] "" Vector__XXX
 SG_ EPBL_lockoutUnlockCount m0 : 49|6@1+ (1,0) [0|0] "" Vector__XXX
 SG_ EPBL_brakeDiscWipeAccumul m2 : 48|8@1+ (1,0) [0|0] "" Vector__XXX
 SG_ EPBL_lockoutCommandDI m2 : 41|1@1+ (1,0) [0|0] "" Vector__XXX
 SG_ EPBL_lockoutOutputDI m2 : 40|1@1+ (1,0) [0|0] "" Vector__XXX
 SG_ EPBL_pid_error m1 : 40|12@1+ (0.016997132,-37.55274262) [0|0] "" Vector__XXX
 SG_ EPBL_currentVariance m0 : 35|14@1- (0.0007629394535064697,0) [0|0] "" Vector__XXX
 SG_ EPBL_atEndStop m0 : 34|1@1+ (1,0) [0|0] "" Vector__XXX
 SG_ EPBL_oocViolation m0 : 33|1@1+ (1,0) [0|0] "" Vector__XXX
 SG_ EPBL_nFault m0 : 32|1@1+ (1,0) [0|0] "" Vector__XXX
 SG_ EPBL_ramp m1 : 32|8@1+ (0.392157,0) [0|0] "" Vector__XXX
 SG_ EPBL_caliperState m0 : 29|3@1+ (1,0) [0|0] "" Vector__XXX
 SG_ EPBL_filteredCurrentPeak m2 : 28|12@1+ (0.01,0) [0|0] "" Vector__XXX
 SG_ EPBL_pid_duty m1 : 22|10@1- (0.2,0) [0|0] "" Vector__XXX
 SG_ EPBL_pvFilt m0 : 20|9@1+ (0.043549408784,0) [0|0] "" Vector__XXX
 SG_ EPBL_currentOffset m2 : 16|12@1+ (0.016997132,-37.55274262) [0|0] "" Vector__XXX
 SG_ EPBL_driverLockedOut m2 : 15|1@1+ (1,0) [0|0] "" Vector__XXX
 SG_ EPBL_dynamicManagerReady m2 : 14|1@1+ (1,0) [0|0] "" Vector__XXX
 SG_ EPBL_emergencyOperationMode m2 : 12|2@1+ (1,0) [0|0] "" Vector__XXX
 SG_ EPBL_pid_uI m1 : 12|10@1- (0.2,0) [0|0] "" Vector__XXX
 SG_ EPBL_nvFilt m0 : 11|9@1+ (0.043549408784,0) [0|0] "" Vector__XXX
 SG_ EPBL_12VFilt_SW m0 : 2|9@1+ (0.043549408784,0) [0|0] "" Vector__XXX
 SG_ EPBL_limpToDecelTimer m2 : 2|10@1+ (1,0) [0|0] "" Vector__XXX
 SG_ EPBL_pid_uP m1 : 2|10@1- (0.2,0) [0|0] "" Vector__XXX
 SG_ EPBL_debugOutputIndex M : 0|2@1+ (1,0) [0|0] "" Vector__XXX

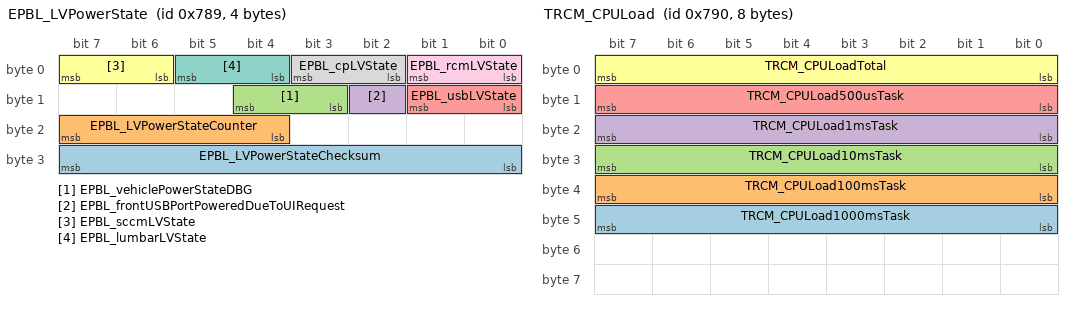
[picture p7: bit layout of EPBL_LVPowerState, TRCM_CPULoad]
BO_ 1929 EPBL_LVPowerState: 4 Vector__XXX
 SG_ EPBL_LVPowerStateChecksum : 24|8@1+ (1,0) [0|0] "" Vector__XXX
 SG_ EPBL_LVPowerStateCounter : 20|4@1+ (1,0) [0|0] "" Vector__XXX
 SG_ EPBL_vehiclePowerStateDBG : 11|2@1+ (1,0) [0|0] "" Vector__XXX
 SG_ EPBL_frontUSBPortPoweredDueToUIRequest : 10|1@1+ (1,0) [0|0] "" Vector__XXX
 SG_ EPBL_usbLVState : 8|2@1+ (1,0) [0|0] "" Vector__XXX
 SG_ EPBL_sccmLVState : 6|2@1+ (1,0) [0|0] "" Vector__XXX
 SG_ EPBL_lumbarLVState : 4|2@1+ (1,0) [0|0] "" Vector__XXX
 SG_ EPBL_cpLVState : 2|2@1+ (1,0) [0|0] "" Vector__XXX
 SG_ EPBL_rcmLVState : 0|2@1+ (1,0) [0|0] "" Vector__XXX

BO_ 1930 HVP_pyroDeviceDbg: 8 Vector__XXX
 SG_ HVP_pyroAoutEr2 m1 : 48|16@1+ (0.001,0) [0|0] "" Vector__XXX
 SG_ HVP_pyroAoutGnd m5 : 48|16@1+ (0.001,0) [0|0] "" Vector__XXX
 SG_ HVP_pyroAoutLeakIgl1 m2 : 48|16@1+ (0.001,0) [0|0] "" Vector__XXX
 SG_ HVP_pyroAoutRref m3 : 48|16@1+ (0.001,0) [0|0] "" Vector__XXX
 SG_ HVP_pyroAoutSquibResIgl1 m4 : 48|16@1+ (0.001,0) [0|0] "" Vector__XXX
 SG_ HVP_pyroAoutVst2 m0 : 48|16@1+ (0.001,0) [0|0] "" Vector__XXX
 SG_ HVP_pyroAoutEr1 m1 : 32|16@1+ (0.001,0) [0|0] "" Vector__XXX
 SG_ HVP_pyroAoutHighsideSwitchIgh1 m5 : 32|16@1+ (0.001,0) [0|0] "" Vector__XXX
 SG_ HVP_pyroAoutLeakIgh1 m2 : 32|16@1+ (0.001,0) [0|0] "" Vector__XXX
 SG_ HVP_pyroAoutLowsideSwitchIgl1 m6 : 32|16@1+ (0.001,0) [0|0] "" Vector__XXX
 SG_ HVP_pyroAoutRm m3 : 32|16@1+ (0.001,0) [0|0] "" Vector__XXX
 SG_ HVP_pyroAoutSquibResIgh1 m4 : 32|16@1+ (0.001,0) [0|0] "" Vector__XXX
 SG_ HVP_pyroAoutVst1 m0 : 32|16@1+ (0.001,0) [0|0] "" Vector__XXX
 SG_ HVP_pyroAoutMultiplexer M : 16|3@1+ (1,0) [0|0] "" Vector__XXX
 SG_ HVP_pyroFiringHandle : 10|4@1+ (1,0) [0|0] "" Vector__XXX
 SG_ HVP_pyroSquibFired : 9|1@1+ (1,0) [0|0] "" Vector__XXX
 SG_ HVP_pyroTestPyroLeakFailed : 8|1@1+ (1,0) [0|0] "" Vector__XXX
 SG_ HVP_pyroTestLowSideSwitchFailed : 7|1@1+ (1,0) [0|0] "" Vector__XXX
 SG_ HVP_pyroTestHighSideSwitchFailed : 6|1@1+ (1,0) [0|0] "" Vector__XXX
 SG_ HVP_pyroTestVstFailed : 5|1@1+ (1,0) [0|0] "" Vector__XXX
 SG_ HVP_pyroTestErFailed : 4|1@1+ (1,0) [0|0] "" Vector__XXX
 SG_ HVP_pyroTestSquibResFailed : 3|1@1+ (1,0) [0|0] "" Vector__XXX
 SG_ HVP_pyroTestRefCurrentFailed : 2|1@1+ (1,0) [0|0] "" Vector__XXX
 SG_ HVP_pyroStatus : 0|2@1+ (1,0) [0|0] "" Vector__XXX

BO_ 1931 EPBL_xcpResponse: 12 Vector__XXX
 SG_ EPBL_xcpResponse : 7|64@0+ (1,0) [0|0] "" Vector__XXX

BO_ 1932 EPBR_xcpResponse: 12 Vector__XXX
 SG_ EPBR_xcpResponse : 7|64@0+ (1,0) [0|0] "" Vector__XXX

BO_ 1936 TRCM_CPULoad: 8 Vector__XXX
 SG_ TRCM_CPULoad1000msTask : 40|8@1+ (1,0) [0|0] "" Vector__XXX
 SG_ TRCM_CPULoad100msTask : 32|8@1+ (1,0) [0|0] "" Vector__XXX
 SG_ TRCM_CPULoad10msTask : 24|8@1+ (1,0) [0|0] "" Vector__XXX
 SG_ TRCM_CPULoad1msTask : 16|8@1+ (1,0) [0|0] "" Vector__XXX
 SG_ TRCM_CPULoad500usTask : 8|8@1+ (1,0) [0|0] "" Vector__XXX
 SG_ TRCM_CPULoadTotal : 0|8@1+ (1,0) [0|0] "" Vector__XXX

BO_ 1940 PMF_xcpResponse: 12 Vector__XXX
 SG_ PMF_xcpResponseData : 7|64@0+ (1,0) [0|0] "" Vector__XXX

BO_ 1942 DIF_xcpResponse: 12 Vector__XXX
 SG_ DIF_xcpResponseData : 7|64@0+ (1,0) [0|0] "" Vector__XXX

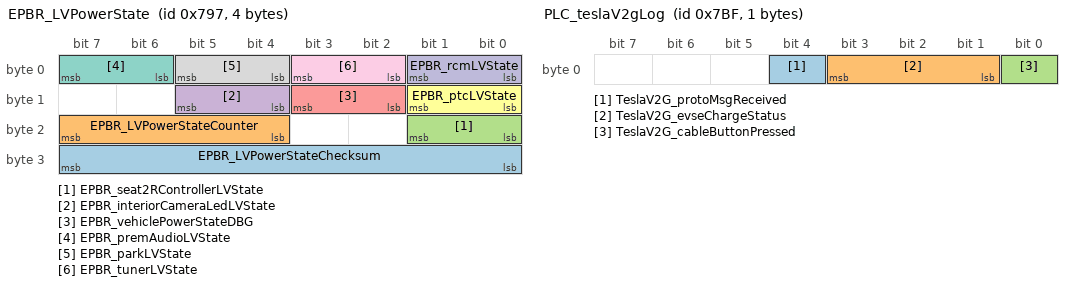
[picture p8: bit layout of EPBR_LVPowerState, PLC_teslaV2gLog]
BO_ 1943 EPBR_LVPowerState: 4 Vector__XXX
 SG_ EPBR_LVPowerStateChecksum : 24|8@1+ (1,0) [0|0] "" Vector__XXX
 SG_ EPBR_LVPowerStateCounter : 20|4@1+ (1,0) [0|0] "" Vector__XXX
 SG_ EPBR_seat2RControllerLVState : 16|2@1+ (1,0) [0|0] "" Vector__XXX
 SG_ EPBR_interiorCameraLedLVState : 12|2@1+ (1,0) [0|0] "" Vector__XXX
 SG_ EPBR_vehiclePowerStateDBG : 10|2@1+ (1,0) [0|0] "" Vector__XXX
 SG_ EPBR_ptcLVState : 8|2@1+ (1,0) [0|0] "" Vector__XXX
 SG_ EPBR_premAudioLVState : 6|2@1+ (1,0) [0|0] "" Vector__XXX
 SG_ EPBR_parkLVState : 4|2@1+ (1,0) [0|0] "" Vector__XXX
 SG_ EPBR_tunerLVState : 2|2@1+ (1,0) [0|0] "" Vector__XXX
 SG_ EPBR_rcmLVState : 0|2@1+ (1,0) [0|0] "" Vector__XXX

BO_ 1944 EPBL_remoteADC: 8 Vector__XXX
 SG_ EPBL_remoteADCChecksum : 56|8@1+ (1,0) [0|0] "" Vector__XXX
 SG_ EPBL_remoteADCCounter : 52|4@1+ (1,0) [0|0] "" Vector__XXX
 SG_ EPBL_2ndRowLeftCushionTemp m3 : 34|10@1+ (0.0009775171065493646,0) [0|0] "" Vector__XXX
 SG_ EPBL_chargePortMonitor m4 : 34|10@1+ (0.017595307917888565,0) [0|0] "" Vector__XXX
 SG_ EPBL_liftGateStrutOpenMonitor m1 : 34|10@1+ (0.017595307917888565,0) [0|0] "" Vector__XXX
 SG_ EPBL_seatFrontTiltUpMonitor m0 : 34|10@1+ (0.017595307917888565,0) [0|0] "" Vector__XXX
 SG_ EPBL_steeringColumnUpMonitor m2 : 34|10@1+ (0.017595307917888565,0) [0|0] "" Vector__XXX
 SG_ EPBL_2ndRowCenterCushionTemp m3 : 24|10@1+ (0.0009775171065493646,0) [0|0] "" Vector__XXX
 SG_ EPBL_accessoryFeedAlwaysOnMonitor m2 : 24|10@1+ (0.017595307917888565,0) [0|0] "" Vector__XXX
 SG_ EPBL_liftGateStrutCloseMonitor m1 : 24|10@1+ (0.017595307917888565,0) [0|0] "" Vector__XXX
 SG_ EPBL_seatFrontLiftUpMonitor m0 : 24|10@1+ (0.017595307917888565,0) [0|0] "" Vector__XXX
 SG_ EPBL_securityControllerMonitor m4 : 24|10@1+ (0.017595307917888565,0) [0|0] "" Vector__XXX
 SG_ EPBL_2ndRowRightCushionTemp m3 : 13|10@1+ (0.0009775171065493646,0) [0|0] "" Vector__XXX
 SG_ EPBL_BLEMonitor m4 : 13|10@1+ (0.017595307917888565,0) [0|0] "" Vector__XXX
 SG_ EPBL_efuseNonContinuousMonitor m1 : 13|10@1+ (0.017595307917888565,0) [0|0] "" Vector__XXX
 SG_ EPBL_mirrorDimMonitor m2 : 13|10@1+ (0.004887585532746823,0) [0|0] "" Vector__XXX
 SG_ EPBL_windowLiftRearDownMonitor m0 : 13|10@1+ (0.017595307917888565,0) [0|0] "" Vector__XXX
 SG_ EPBL_PCBATemp m4 : 3|10@1+ (0.0009775171065493646,0) [0|0] "" Vector__XXX
 SG_ EPBL_efuseContinousMonitor m1 : 3|10@1+ (0.017595307917888565,0) [0|0] "" Vector__XXX
 SG_ EPBL_frontCushionTemp m3 : 3|10@1+ (0.0009775171065493646,0) [0|0] "" Vector__XXX
 SG_ EPBL_seatFrontBackRestUpMonitor m2 : 3|10@1+ (0.017595307917888565,0) [0|0] "" Vector__XXX
 SG_ EPBL_trailerAuxMonitor m6 : 3|10@1+ (0.017595307917888565,0) [0|0] "" Vector__XXX
 SG_ EPBL_windowLiftFrontUpMonitor m0 : 3|10@1+ (0.017595307917888565,0) [0|0] "" Vector__XXX
 SG_ EPBL_remoteADCIndex M : 0|3@1+ (1,0) [0|0] "" Vector__XXX

BO_ 1945 DI_xcpResponse: 12 Vector__XXX
 SG_ DI_xcpResponseData : 7|64@0+ (1,0) [0|0] "" Vector__XXX

BO_ 1947 XCP_epblRequest: 12 Vector__XXX
 SG_ XCP_epblRequest : 7|64@0+ (1,0) [0|0] "" Vector__XXX

BO_ 1948 XCP_epbrRequest: 12 Vector__XXX
 SG_ XCP_epbrRequest : 7|64@0+ (1,0) [0|0] "" Vector__XXX

BO_ 1949 V2G_evseLogData: 8 Vector__XXX
 SG_ V2G_chgParamRes_isoState_val m7 : 62|1@1+ (1,0) [0|0] "" Vector__XXX
 SG_ V2G_currDemRes_isoState m11 : 61|3@1+ (1,0) [0|0] "" Vector__XXX
 SG_ V2G_currDemRes_evseMaxPower_val m11 : 60|1@1+ (1,0) [0|0] "" Vector__XXX
 SG_ V2G_chgParamRes_isoState m7 : 59|3@1+ (1,0) [0|0] "" Vector__XXX
 SG_ V2G_chgParamRes_evseMaxPower_val m7 : 58|1@1+ (1,0) [0|0] "" Vector__XXX
 SG_ V2G_currDemRes_evseMaxPowerLim m11 : 52|8@1+ (5.9766,0) [0|0] "" Vector__XXX
 SG_ V2G_currDemRes_evseMaxVLim_val m11 : 51|1@1+ (1,0) [0|0] "" Vector__XXX
 SG_ V2G_chgParamRes_evseMaxPowerLim m7 : 50|8@1+ (5.9766,0) [0|0] "" Vector__XXX
 SG_ V2G_currDemRes_evseMaxVLim m11 : 43|8@1+ (4.688,0) [0|0] "" Vector__XXX
 SG_ V2G_chgParamRes_evseMinVLim m7 : 42|8@1+ (4.688,0) [0|0] "" Vector__XXX
 SG_ V2G_currDemRes_evseMaxILim_val m11 : 42|1@1+ (1,0) [0|0] "" Vector__XXX
 SG_ V2G_prechargeRes_isoState_val m9 : 35|1@1+ (1,0) [0|0] "" Vector__XXX
 SG_ V2G_chgParamRes_evseMinILim m7 : 34|8@1+ (7.032,0) [0|0] "" Vector__XXX
 SG_ V2G_currDemRes_evseMaxILim m11 : 34|8@1+ (7.032,0) [0|0] "" Vector__XXX
 SG_ V2G_prechargeRes_isoState m9 : 32|3@1+ (1,0) [0|0] "" Vector__XXX
 SG_ V2G_chgParamRes_evseMaxVLim m7 : 26|8@1+ (4.688,0) [0|0] "" Vector__XXX
 SG_ V2G_chargingStatusRes_rcd m12 : 24|1@1+ (1,0) [0|0] "" Vector__XXX
 SG_ V2G_currDemRes_outputI m11 : 24|10@1+ (1.7578125,0) [0|0] "" Vector__XXX
 SG_ V2G_cableCheckRes_isoState_val m8 : 23|1@1+ (1,0) [0|0] "" Vector__XXX
 SG_ V2G_chargingStatusRes_maxI_val m12 : 23|1@1+ (1,0) [0|0] "" Vector__XXX
 SG_ V2G_pwrDelEndRes_isoState_val m13 : 23|1@1+ (1,0) [0|0] "" Vector__XXX
 SG_ V2G_pwrDelStartRes_isoState_val m10 : 23|1@1+ (1,0) [0|0] "" Vector__XXX
 SG_ V2G_cableCheckRes_isoState m8 : 20|3@1+ (1,0) [0|0] "" Vector__XXX
 SG_ V2G_prechargeRes_outputV m9 : 20|10@1+ (1.171875,0) [0|0] "" Vector__XXX
 SG_ V2G_pwrDelEndRes_isoState m13 : 20|3@1+ (1,0) [0|0] "" Vector__XXX
 SG_ V2G_pwrDelStartRes_isoState m10 : 20|3@1+ (1,0) [0|0] "" Vector__XXX
 SG_ V2G_chgParamRes_evseMaxILim m7 : 18|8@1+ (7.032,0) [0|0] "" Vector__XXX
 SG_ V2G_cableCheckRes_evseStatus m8 : 16|4@1+ (1,0) [0|0] "" Vector__XXX
 SG_ V2G_chargingStatusRes_maxI m12 : 16|7@1+ (1,0) [0|0] "" Vector__XXX
 SG_ V2G_powerDelEndRes_evseStatus m13 : 16|4@1+ (1,0) [0|0] "" Vector__XXX
 SG_ V2G_powerDelStartRes_evseStatus m10 : 16|4@1+ (1,0) [0|0] "" Vector__XXX
 SG_ V2G_prechargeRes_evseStatus m9 : 16|4@1+ (1,0) [0|0] "" Vector__XXX
 SG_ V2G_serviceDiscRes_dcExtended m2 : 16|1@1+ (1,0) [0|0] "" Vector__XXX
 SG_ V2G_serviceDiscRes_evChgAvail m2 : 15|1@1+ (1,0) [0|0] "" Vector__XXX
 SG_ V2G_chgParamRes_evseStatus m7 : 14|4@1+ (1,0) [0|0] "" Vector__XXX
 SG_ V2G_currDemRes_outputV m11 : 14|10@1+ (1.171875,0) [0|0] "" Vector__XXX
 SG_ V2G_serviceDiscRes_pncAvail m2 : 14|1@1+ (1,0) [0|0] "" Vector__XXX
 SG_ V2G_cableCheckRes_finished m8 : 13|1@1+ (1,0) [0|0] "" Vector__XXX
 SG_ V2G_chgParamRes_finished m7 : 13|1@1+ (1,0) [0|0] "" Vector__XXX
 SG_ V2G_contractAuthRes_finished m6 : 13|1@1+ (1,0) [0|0] "" Vector__XXX
 SG_ V2G_serviceDiscRes_extPayAvail m2 : 13|1@1+ (1,0) [0|0] "" Vector__XXX
 SG_ V2G_currDemRes_evseStatus m11 : 10|4@1+ (1,0) [0|0] "" Vector__XXX
 SG_ V2G_cableCheckRes_respCode m8 : 8|5@1+ (1,0) [0|0] "" Vector__XXX
 SG_ V2G_chargingStatusRes_respCode m12 : 8|5@1+ (1,0) [0|0] "" Vector__XXX
 SG_ V2G_chgParamRes_respCode m7 : 8|5@1+ (1,0) [0|0] "" Vector__XXX
 SG_ V2G_contractAuthRes_respCode m6 : 8|5@1+ (1,0) [0|0] "" Vector__XXX
 SG_ V2G_paymentDetailsRes_respCode m5 : 8|5@1+ (1,0) [0|0] "" Vector__XXX
 SG_ V2G_powerDelEndRes_respCode m13 : 8|5@1+ (1,0) [0|0] "" Vector__XXX
 SG_ V2G_powerDelStartRes_respCode m10 : 8|5@1+ (1,0) [0|0] "" Vector__XXX
 SG_ V2G_prechargeRes_respCode m9 : 8|5@1+ (1,0) [0|0] "" Vector__XXX
 SG_ V2G_serviceDetailRes_respCode m3 : 8|5@1+ (1,0) [0|0] "" Vector__XXX
 SG_ V2G_serviceDiscoveryRes_respCode m2 : 8|5@1+ (1,0) [0|0] "" Vector__XXX
 SG_ V2G_servicePaymntSelRes_respCode m4 : 8|5@1+ (1,0) [0|0] "" Vector__XXX
 SG_ V2G_sessionSetupRes_respCode m1 : 8|5@1+ (1,0) [0|0] "" Vector__XXX
 SG_ V2G_sessionStopRes_respCode m14 : 8|5@1+ (1,0) [0|0] "" Vector__XXX
 SG_ V2G_suppAppProtocolRes_schemaId m0 : 8|8@1+ (1,0) [0|0] "" Vector__XXX
 SG_ V2G_currDemRes_isoState_val m13 : 5|1@1+ (1,0) [0|0] "" Vector__XXX
 SG_ V2G_currDemRes_respCode m11 : 5|5@1+ (1,0) [0|0] "" Vector__XXX
 SG_ V2G_suppAppProtocolRes_respCode m0 : 5|2@1+ (1,0) [0|0] "" Vector__XXX
 SG_ V2G_evseLogDataSelect M : 0|5@1+ (1,0) [0|0] "" Vector__XXX

BO_ 1951 ADSP_audioVisualizer: 8 Vector__XXX
 SG_ ADSP_audioVisualizerBrightness : 0|8@1+ (1,0) [0|0] "" Vector__XXX

BO_ 1960 EPBR_debugOutput: 8 Vector__XXX
 SG_ EPBR_uiNotAvailable m0 : 62|1@1+ (1,0) [0|0] "" Vector__XXX
 SG_ EPBR_driverIsLeavingDisabled m0 : 61|1@1+ (1,0) [0|0] "" Vector__XXX
 SG_ EPBR_slopeParkable m0 : 60|1@1+ (1,0) [0|0] "" Vector__XXX
 SG_ EPBR_epbOpenUnableToPark m0 : 59|1@1+ (1,0) [0|0] "" Vector__XXX
 SG_ EPBR_brakePressHeld m0 : 58|1@1+ (1,0) [0|0] "" Vector__XXX
 SG_ EPBR_esmCaliperRequest m0 : 55|3@1+ (1,0) [0|0] "" Vector__XXX
 SG_ EPBR_12VFilt m1 : 52|9@1+ (0.043549408784,0) [0|0] "" Vector__XXX
 SG_ EPBR_lockoutUnlockCount m0 : 49|6@1+ (1,0) [0|0] "" Vector__XXX
 SG_ EPBR_brakeDiscWipeAccumul m2 : 48|8@1+ (1,0) [0|0] "" Vector__XXX
 SG_ EPBR_lockoutCommandHVC m2 : 43|1@1+ (1,0) [0|0] "" Vector__XXX
 SG_ EPBR_lockoutOutputHVC m2 : 42|1@1+ (1,0) [0|0] "" Vector__XXX
 SG_ EPBR_lockoutCmdContactor m2 : 41|1@1+ (1,0) [0|0] "" Vector__XXX
 SG_ EPBR_lockoutOutContactor m2 : 40|1@1+ (1,0) [0|0] "" Vector__XXX
 SG_ EPBR_pid_error m1 : 40|12@1+ (0.016997132,-37.55274262) [0|0] "" Vector__XXX
 SG_ EPBR_currentVariance m0 : 35|14@1- (0.0007629394535064697,0) [0|0] "" Vector__XXX
 SG_ EPBR_atEndStop m0 : 34|1@1+ (1,0) [0|0] "" Vector__XXX
 SG_ EPBR_oocViolation m0 : 33|1@1+ (1,0) [0|0] "" Vector__XXX
 SG_ EPBR_nFault m0 : 32|1@1+ (1,0) [0|0] "" Vector__XXX
 SG_ EPBR_ramp m1 : 32|8@1+ (0.392157,0) [0|0] "" Vector__XXX
 SG_ EPBR_caliperState m0 : 29|3@1+ (1,0) [0|0] "" Vector__XXX
 SG_ EPBR_filteredCurrentPeak m2 : 28|12@1+ (0.01,0) [0|0] "" Vector__XXX
 SG_ EPBR_pid_duty m1 : 22|10@1- (0.2,0) [0|0] "" Vector__XXX
 SG_ EPBR_pvFilt m0 : 20|9@1+ (0.043549408784,0) [0|0] "" Vector__XXX
 SG_ EPBR_currentOffset m2 : 16|12@1+ (0.016997132,-37.55274262) [0|0] "" Vector__XXX
 SG_ EPBR_driverLockedOut m2 : 15|1@1+ (1,0) [0|0] "" Vector__XXX
 SG_ EPBR_dynamicManagerReady m2 : 14|1@1+ (1,0) [0|0] "" Vector__XXX
 SG_ EPBR_emergencyOperationMode m2 : 12|2@1+ (1,0) [0|0] "" Vector__XXX
 SG_ EPBR_pid_uI m1 : 12|10@1- (0.2,0) [0|0] "" Vector__XXX
 SG_ EPBR_nvFilt m0 : 11|9@1+ (0.043549408784,0) [0|0] "" Vector__XXX
 SG_ EPBR_12VFilt_SW m0 : 2|9@1+ (0.043549408784,0) [0|0] "" Vector__XXX
 SG_ EPBR_limpToDecelTimer m2 : 2|10@1+ (1,0) [0|0] "" Vector__XXX
 SG_ EPBR_pid_uP m1 : 2|10@1- (0.2,0) [0|0] "" Vector__XXX
 SG_ EPBR_debugOutputIndex M : 0|2@1+ (1,0) [0|0] "" Vector__XXX

BO_ 1970 DBG_bmsServiceReq: 8 Vector__XXX
 SG_ DBG_bmsDebugEnableAll : 0|1@1+ (1,0) [0|0] "" Vector__XXX

BO_ 1971 UI_dynamicTriggersCampaignFired: 8 Vector__XXX
 SG_ UI_campaignFired : 0|64@1+ (1,0) [0|0] "" Vector__XXX

BO_ 1973 PM_itpmsDisplay: 3 Vector__XXX
 SG_ PM_indirectTPMSDisplayWarningIndicatorRR m0 : 20|2@1+ (1,0) [0|0] "" Vector__XXX
 SG_ PM_indirectTPMSDisplayWarningIndicatorRL m0 : 18|2@1+ (1,0) [0|0] "" Vector__XXX
 SG_ PM_indirectTPMSDisplayWarningIndicatorFR m0 : 16|2@1+ (1,0) [0|0] "" Vector__XXX
 SG_ PM_indirectTPMSRecommendedColdPressureRear m1 : 16|8@1+ (0.025,0) [0|0] "" Vector__XXX
 SG_ PM_indirectTPMSDisplayWarningIndicatorFL m0 : 13|2@1+ (1,0) [0|0] "" Vector__XXX
 SG_ PM_fusedPressureEstimateFrR m2 : 11|9@1+ (0.008,0) [0|0] "" Vector__XXX
 SG_ PM_fusedPressureEstimateReR m3 : 11|9@1+ (0.008,0) [0|0] "" Vector__XXX
 SG_ PM_indirectTPMSDisplayProgress m0 : 8|5@1+ (0.05,0) [0|0] "" Vector__XXX
 SG_ PM_indirectTPMSRecommendedColdPressureFront m1 : 8|8@1+ (0.025,0) [0|0] "" Vector__XXX
 SG_ PM_indirectTPMSDisplayState m0 : 4|2@1+ (1,0) [0|0] "" Vector__XXX
 SG_ PM_fusedPressureEstimateFrL m2 : 2|9@1+ (0.008,0) [0|0] "" Vector__XXX
 SG_ PM_fusedPressureEstimateReL m3 : 2|9@1+ (0.008,0) [0|0] "" Vector__XXX
 SG_ PM_indirectTPMSTellTale m0 : 2|2@1+ (1,0) [0|0] "" Vector__XXX
 SG_ PM_itpmsDisplaySelector M : 0|2@1+ (1,0) [0|0] "" Vector__XXX

BO_ 1976 EPBR_remoteADC: 8 Vector__XXX
 SG_ EPBR_remoteADCChecksum : 56|8@1+ (1,0) [0|0] "" Vector__XXX
 SG_ EPBR_remoteADCCounter : 52|4@1+ (1,0) [0|0] "" Vector__XXX
 SG_ EPBR_2rSeatInboardFloorSensor m5 : 34|10@1+ (0.004887585532746823,0) [0|0] "" Vector__XXX
 SG_ EPBR_PCBATemp m2 : 34|10@1+ (0.0009775171065493646,0) [0|0] "" Vector__XXX
 SG_ EPBR_gloveBoxReleaseMonitor m1 : 34|10@1+ (0.017595307917888565,0) [0|0] "" Vector__XXX
 SG_ EPBR_hvacLeftLowerVentDuctTemp m3 : 34|10@1+ (0.0009775171065493646,0) [0|0] "" Vector__XXX
 SG_ EPBR_premiumAmpCurrent m4 : 34|10@1+ (0.029296875,0) [0|0] "" Vector__XXX
 SG_ EPBR_seatFrontTiltUpMonitor m0 : 34|10@1+ (0.017595307917888565,0) [0|0] "" Vector__XXX
 SG_ EPBR_2rSeatOutboardFloorSensor m5 : 24|10@1+ (0.004887585532746823,0) [0|0] "" Vector__XXX
 SG_ EPBR_ecallStandbyPowerMonitor m2 : 24|10@1+ (0.02932551319648094,0) [0|0] "" Vector__XXX
 SG_ EPBR_gloveBoxLatchUpstreamI m4 : 24|10@1+ (0.019550342130987292,0) [0|0] "" Vector__XXX
 SG_ EPBR_hvacRightLowerVentDuctTemp m3 : 24|10@1+ (0.0009775171065493646,0) [0|0] "" Vector__XXX
 SG_ EPBR_seatFrontLiftUpMonitor m0 : 24|10@1+ (0.017595307917888565,0) [0|0] "" Vector__XXX
 SG_ EPBR_seatFrontTrackForwardMonitor m1 : 24|10@1+ (0.017595307917888565,0) [0|0] "" Vector__XXX
 SG_ EPBR_efuseNonContinuousMonitor m1 : 13|10@1+ (0.017595307917888565,0) [0|0] "" Vector__XXX
 SG_ EPBR_frontCushionTemp m5 : 13|10@1+ (0.0009775171065493646,0) [0|0] "" Vector__XXX
 SG_ EPBR_hvContactorsMonitor m4 : 13|10@1+ (0.017595307917888565,0) [0|0] "" Vector__XXX
 SG_ EPBR_hvacLeftVentDuctTemp m3 : 13|10@1+ (0.0009775171065493646,0) [0|0] "" Vector__XXX
 SG_ EPBR_seatFrontBackRestUpMonitor m2 : 13|10@1+ (0.017595307917888565,0) [0|0] "" Vector__XXX
 SG_ EPBR_windowLiftRearUpMonitor m0 : 13|10@1+ (0.017595307917888565,0) [0|0] "" Vector__XXX
 SG_ EPBR_BLEBPillarMonitor m4 : 3|10@1+ (0.017595307917888565,0) [0|0] "" Vector__XXX
 SG_ EPBR_efuseContinousMonitor m1 : 3|10@1+ (0.017595307917888565,0) [0|0] "" Vector__XXX
 SG_ EPBR_hvacRightVentDuctTemp m3 : 3|10@1+ (0.0009775171065493646,0) [0|0] "" Vector__XXX
 SG_ EPBR_mirrorDimMonitor m2 : 3|10@1+ (0.004887585532746823,0) [0|0] "" Vector__XXX
 SG_ EPBR_rearGlassHeaterCurrent m5 : 3|10@1+ (0.068359375,0) [0|0] "" Vector__XXX
 SG_ EPBR_windowLiftFrontDownMonitor m0 : 3|10@1+ (0.017595307917888565,0) [0|0] "" Vector__XXX
 SG_ EPBR_remoteADCIndex M : 0|3@1+ (1,0) [0|0] "" Vector__XXX

BO_ 1980 HCMR_info: 8 Vector__XXX
 SG_ VC_hcmrVoltage_boostRail m6 : 54|10@1+ (0.1,0) [0|0] "" Vector__XXX
 SG_ VC_hcmrUartQueueResetCounter m8 : 48|8@1+ (1,0) [0|0] "" Vector__XXX
 SG_ VC_hcmrVoltage_SM m6 : 44|10@1+ (0.1,0) [0|0] "" Vector__XXX
 SG_ VC_hcmrUartDmaQueueFullErrorCoun m8 : 40|8@1+ (1,0) [0|0] "" Vector__XXX
 SG_ VC_infoHCMRUsageId m1 : 40|16@1+ (1,0) [0|0] "" Vector__XXX
 SG_ VC_hcmrVoltage_TURN m6 : 34|10@1+ (0.1,0) [0|0] "" Vector__XXX
 SG_ VC_hcmrUartValidatedGroupsFullEr m8 : 32|8@1+ (1,0) [0|0] "" Vector__XXX
 SG_ VC_hcmrUartGroupsFullErrorCounte m8 : 24|8@1+ (1,0) [0|0] "" Vector__XXX
 SG_ VC_hcmrVoltage_DRL m6 : 24|10@1+ (0.1,0) [0|0] "" Vector__XXX
 SG_ VC_hcmr_ic600_EEPROMWriteCount m4 : 24|16@1+ (1,0) [0|0] "" Vector__XXX
 SG_ VC_infoHCMRPcbaId m1 : 24|16@1+ (1,0) [0|0] "" Vector__XXX
 SG_ VC_rightHeadlampLMMVariant m0 : 24|2@1+ (1,0) [0|0] "" Vector__XXX
 SG_ VC_hcmrFault_TURN_LEDOV m4 : 23|1@1+ (1,0) [0|0] "" Vector__XXX
 SG_ VC_hcmrFault_TURN_LEDUV m4 : 22|1@1+ (1,0) [0|0] "" Vector__XXX
 SG_ VC_hcmrFault_TURN_TOFFMIN m4 : 21|1@1+ (1,0) [0|0] "" Vector__XXX
 SG_ VC_hcmrFault_TURN_BOOTUV m4 : 20|1@1+ (1,0) [0|0] "" Vector__XXX
 SG_ VC_hcmrFault_TURN_LSILIM m4 : 19|1@1+ (1,0) [0|0] "" Vector__XXX
 SG_ VC_hcmrFault_TURN_HSILIM m4 : 18|1@1+ (1,0) [0|0] "" Vector__XXX
 SG_ VC_hcmrFault_TURN_COMPOV m4 : 17|1@1+ (1,0) [0|0] "" Vector__XXX
 SG_ VC_hcmrDRLSideMarkerTurnDerating m8 : 16|8@1+ (0.5,0) [0|0] "" Vector__XXX
 SG_ VC_hcmrFault_TURN_SHORT m4 : 16|1@1+ (1,0) [0|0] "" Vector__XXX
 SG_ VC_hcmr_ic400_EEPROMWriteCount m2 : 16|16@1+ (1,0) [0|0] "" Vector__XXX
 SG_ VC_hcmr_ic500_EEPROMWriteCount m3 : 16|16@1+ (1,0) [0|0] "" Vector__XXX
 SG_ VC_hcmr_ic700_EEPROMWriteCount m5 : 16|16@1+ (1,0) [0|0] "" Vector__XXX
 SG_ VC_hcmrFault_TURN_VBCKUVLO m4 : 15|1@1+ (1,0) [0|0] "" Vector__XXX
 SG_ VC_hcmrFault_TURN_THERMAL m4 : 14|1@1+ (1,0) [0|0] "" Vector__XXX
 SG_ VC_hcmrVoltage_LB m6 : 14|10@1+ (0.1,0) [0|0] "" Vector__XXX
 SG_ VC_hcmrFault_DRL_LEDOV m4 : 13|1@1+ (1,0) [0|0] "" Vector__XXX
 SG_ VC_hcmrFault_HB_LEDOV m2 : 13|1@1+ (1,0) [0|0] "" Vector__XXX
 SG_ VC_hcmrFault_LB_LEDOV m3 : 13|1@1+ (1,0) [0|0] "" Vector__XXX
 SG_ VC_hcmrFault_SM_LEDOV m5 : 13|1@1+ (1,0) [0|0] "" Vector__XXX
 SG_ VC_hcmrFault_DRL_LEDUV m4 : 12|1@1+ (1,0) [0|0] "" Vector__XXX
 SG_ VC_hcmrFault_HB_LEDUV m2 : 12|1@1+ (1,0) [0|0] "" Vector__XXX
 SG_ VC_hcmrFault_LB_LEDUV m3 : 12|1@1+ (1,0) [0|0] "" Vector__XXX
 SG_ VC_hcmrFault_SM_LEDUV m5 : 12|1@1+ (1,0) [0|0] "" Vector__XXX
 SG_ VC_hcmrFault_DRL_TOFFMIN m4 : 11|1@1+ (1,0) [0|0] "" Vector__XXX
 SG_ VC_hcmrFault_HB_TOFFMIN m2 : 11|1@1+ (1,0) [0|0] "" Vector__XXX
 SG_ VC_hcmrFault_LB_TOFFMIN m3 : 11|1@1+ (1,0) [0|0] "" Vector__XXX
 SG_ VC_hcmrFault_SM_TOFFMIN m5 : 11|1@1+ (1,0) [0|0] "" Vector__XXX
 SG_ VC_hcmrFault_DRL_BOOTUV m4 : 10|1@1+ (1,0) [0|0] "" Vector__XXX
 SG_ VC_hcmrFault_HB_BOOTUV m2 : 10|1@1+ (1,0) [0|0] "" Vector__XXX
 SG_ VC_hcmrFault_LB_BOOTUV m3 : 10|1@1+ (1,0) [0|0] "" Vector__XXX
 SG_ VC_hcmrFault_SM_BOOTUV m5 : 10|1@1+ (1,0) [0|0] "" Vector__XXX
 SG_ VC_hcmrFault_DRL_LSILIM m4 : 9|1@1+ (1,0) [0|0] "" Vector__XXX
 SG_ VC_hcmrFault_HB_LSILIM m2 : 9|1@1+ (1,0) [0|0] "" Vector__XXX
 SG_ VC_hcmrFault_LB_LSILIM m3 : 9|1@1+ (1,0) [0|0] "" Vector__XXX
 SG_ VC_hcmrFault_SM_LSILIM m5 : 9|1@1+ (1,0) [0|0] "" Vector__XXX
 SG_ VC_hcmrFault_DRL_HSILIM m4 : 8|1@1+ (1,0) [0|0] "" Vector__XXX
 SG_ VC_hcmrFault_HB_HSILIM m2 : 8|1@1+ (1,0) [0|0] "" Vector__XXX
 SG_ VC_hcmrFault_LB_HSILIM m3 : 8|1@1+ (1,0) [0|0] "" Vector__XXX
 SG_ VC_hcmrFault_SM_HSILIM m5 : 8|1@1+ (1,0) [0|0] "" Vector__XXX
 SG_ VC_hcmrLowBeamHighBeamDeratingFa m8 : 8|8@1+ (0.5,0) [0|0] "" Vector__XXX
 SG_ VC_infoHCMRAssemblyId m1 : 8|16@1+ (1,0) [0|0] "" Vector__XXX
 SG_ VC_infoHCMRBuildConfigId m0 : 8|16@1+ (1,0) [0|0] "" Vector__XXX
 SG_ VC_hcmrBoost_ISPUV m7 : 7|1@1+ (1,0) [0|0] "" Vector__XXX
 SG_ VC_hcmrFault_DRL_COMPOV m4 : 7|1@1+ (1,0) [0|0] "" Vector__XXX
 SG_ VC_hcmrFault_HB_COMPOV m2 : 7|1@1+ (1,0) [0|0] "" Vector__XXX
 SG_ VC_hcmrFault_LB_COMPOV m3 : 7|1@1+ (1,0) [0|0] "" Vector__XXX
 SG_ VC_hcmrFault_SM_COMPOV m5 : 7|1@1+ (1,0) [0|0] "" Vector__XXX
 SG_ VC_hcmrBoost_ILIM m7 : 6|1@1+ (1,0) [0|0] "" Vector__XXX
 SG_ VC_hcmrFault_DRL_SHORT m4 : 6|1@1+ (1,0) [0|0] "" Vector__XXX
 SG_ VC_hcmrFault_HB_SHORT m2 : 6|1@1+ (1,0) [0|0] "" Vector__XXX
 SG_ VC_hcmrFault_LB_SHORT m3 : 6|1@1+ (1,0) [0|0] "" Vector__XXX
 SG_ VC_hcmrFault_SM_SHORT m5 : 6|1@1+ (1,0) [0|0] "" Vector__XXX
 SG_ VC_hcmrBoost_BOOTUV m7 : 5|1@1+ (1,0) [0|0] "" Vector__XXX
 SG_ VC_hcmrFault_DRL_VBCKUVLO m4 : 5|1@1+ (1,0) [0|0] "" Vector__XXX
 SG_ VC_hcmrFault_HB_VBCKUVLO m2 : 5|1@1+ (1,0) [0|0] "" Vector__XXX
 SG_ VC_hcmrFault_LB_VBCKUVLO m3 : 5|1@1+ (1,0) [0|0] "" Vector__XXX
 SG_ VC_hcmrFault_SM_VBCKUVLO m5 : 5|1@1+ (1,0) [0|0] "" Vector__XXX
 SG_ VC_hcmrBoost_OV m7 : 4|1@1+ (1,0) [0|0] "" Vector__XXX
 SG_ VC_hcmrFault_DRL_THERMAL m4 : 4|1@1+ (1,0) [0|0] "" Vector__XXX
 SG_ VC_hcmrFault_HB_THERMAL m2 : 4|1@1+ (1,0) [0|0] "" Vector__XXX
 SG_ VC_hcmrFault_LB_THERMAL m3 : 4|1@1+ (1,0) [0|0] "" Vector__XXX
 SG_ VC_hcmrFault_SM_THERMAL m5 : 4|1@1+ (1,0) [0|0] "" Vector__XXX
 SG_ VC_hcmrVoltage_HB m6 : 4|10@1+ (0.1,0) [0|0] "" Vector__XXX
 SG_ VC_hcmrInfoIndex M : 0|4@1+ (1,0) [0|0] "" Vector__XXX

BO_ 1981 V2G_vehLogData: 8 Vector__XXX
 SG_ V2G_chgParamReq_evReady m7 : 60|1@1+ (1,0) [0|0] "" Vector__XXX
 SG_ V2G_chgParamReq_evStatusCode m7 : 56|4@1+ (1,0) [0|0] "" Vector__XXX
 SG_ V2G_currentDemReq_maxPowerLim m11 : 50|10@1+ (1.494138,0) [0|0] "" Vector__XXX
 SG_ V2G_chgParamReq_maxPowerLim m7 : 40|13@1+ (0.1867675781,0) [0|0] "" Vector__XXX
 SG_ V2G_currentDemReq_maxVoltageLim m11 : 40|10@1+ (1.171875,0) [0|0] "" Vector__XXX
 SG_ V2G_currentDemReq_maxCurrentLim m11 : 29|10@1+ (1.7578125,0) [0|0] "" Vector__XXX
 SG_ V2G_chgParamReq_maxVoltageLim m7 : 24|13@1+ (0.146484375,0) [0|0] "" Vector__XXX
 SG_ V2G_currentDemReq_targetV m11 : 16|13@1+ (0.146484375,0) [0|0] "" Vector__XXX
 SG_ V2G_chgParamReq_maxCurrentLim m7 : 8|13@1+ (0.2197265625,0) [0|0] "" Vector__XXX
 SG_ V2G_prechargeReq_targetV m9 : 8|13@1+ (0.146484375,0) [0|0] "" Vector__XXX
 SG_ V2G_powerDelEndReq_evStatusCode m13 : 6|1@1+ (1,0) [0|0] "" Vector__XXX
 SG_ V2G_cableCheckReq_sent m8 : 5|1@1+ (1,0) [0|0] "" Vector__XXX
 SG_ V2G_chargingStatusReq_sent m12 : 5|1@1+ (1,0) [0|0] "" Vector__XXX
 SG_ V2G_contractAuthReq_sent m6 : 5|1@1+ (1,0) [0|0] "" Vector__XXX
 SG_ V2G_currentDemReq_targetI m11 : 5|10@1+ (1.7578125,0) [0|0] "" Vector__XXX
 SG_ V2G_paymentDetailsReq_sent m5 : 5|1@1+ (1,0) [0|0] "" Vector__XXX
 SG_ V2G_powerDeliveryEndReq_sent m13 : 5|1@1+ (1,0) [0|0] "" Vector__XXX
 SG_ V2G_powerDeliveryStartReq_sent m10 : 5|1@1+ (1,0) [0|0] "" Vector__XXX
 SG_ V2G_serviceDetailReq_sent m3 : 5|1@1+ (1,0) [0|0] "" Vector__XXX
 SG_ V2G_serviceDiscoveryReq_sent m2 : 5|1@1+ (1,0) [0|0] "" Vector__XXX
 SG_ V2G_servicePaymentSelReq_sent m4 : 5|1@1+ (1,0) [0|0] "" Vector__XXX
 SG_ V2G_sessionSetupReq_sent m1 : 5|1@1+ (1,0) [0|0] "" Vector__XXX
 SG_ V2G_sessionStopReq_sent m14 : 5|1@1+ (1,0) [0|0] "" Vector__XXX
 SG_ V2G_suppAppProtocolReq_sent m0 : 5|1@1+ (1,0) [0|0] "" Vector__XXX
 SG_ V2G_vehLogDataSelect M : 0|5@1+ (1,0) [0|0] "" Vector__XXX

BO_ 1983 PLC_teslaV2gLog: 1 Vector__XXX
 SG_ TeslaV2G_protoMsgReceived : 4|1@1+ (1,0) [0|0] "" Vector__XXX
 SG_ TeslaV2G_evseChargeStatus : 1|3@1+ (1,0) [0|0] "" Vector__XXX
 SG_ TeslaV2G_cableButtonPressed : 0|1@1+ (1,0) [0|0] "" Vector__XXX

BO_ 1999 PM_debug: 8 Vector__XXX
 SG_ PM_cpu100HzMin m64 : 56|8@1+ (0.4,0) [0|0] "" Vector__XXX
 SG_ PM_cpu10kHzMax m65 : 56|8@1+ (0.4,0) [0|0] "" Vector__XXX
 SG_ PM_cpu1kHzAvg m64 : 48|8@1+ (0.4,0) [0|0] "" Vector__XXX
 SG_ PM_cpu20kHzMin m65 : 48|8@1+ (0.4,0) [0|0] "" Vector__XXX
 SG_ PM_regenBackfillState m4 : 48|2@1+ (1,0) [0|0] "" Vector__XXX
 SG_ PM_cpu100HzMax m64 : 40|8@1+ (0.4,0) [0|0] "" Vector__XXX
 SG_ PM_cpu20kHzMax m65 : 40|8@1+ (0.4,0) [0|0] "" Vector__XXX
 SG_ PM_pedalRailB m5 : 40|6@1+ (0.085,0) [0|0] "" Vector__XXX
 SG_ PM_speedMin m3 : 40|16@1- (0.1,0) [0|0] "" Vector__XXX
 SG_ PM_torqueAccelAvg m1 : 40|13@1- (2,0) [0|0] "" Vector__XXX
 SG_ PM_torqueReversalWindow m2 : 40|13@1- (2,0) [0|0] "" Vector__XXX
 SG_ PM_allowedRegenBackfillBrakeTorq m4 : 32|16@1- (0.5,0) [0|0] "" Vector__XXX
 SG_ PM_cpu10HzMin m65 : 32|8@1+ (0.4,0) [0|0] "" Vector__XXX
 SG_ PM_cpu10kHzAvg m64 : 32|8@1+ (0.4,0) [0|0] "" Vector__XXX
 SG_ PM_pedalRailA m5 : 32|6@1+ (0.085,0) [0|0] "" Vector__XXX
 SG_ PM_cpu10HzAvg m65 : 24|8@1+ (0.4,0) [0|0] "" Vector__XXX
 SG_ PM_cpu1kHzMin m64 : 24|8@1+ (0.4,0) [0|0] "" Vector__XXX
 SG_ PM_idleStackMax m67 : 24|16@1+ (1,0) [0|0] "" Vector__XXX
 SG_ PM_pedalPosA m5 : 24|8@1+ (0.4,0) [0|0] "" Vector__XXX
 SG_ PM_shiftRequest m4 : 24|1@1+ (1,0) [0|0] "" Vector__XXX
 SG_ PM_speedMax m3 : 24|16@1- (0.1,0) [0|0] "" Vector__XXX
 SG_ PM_torqueAccelWindow m1 : 24|13@1- (2,0) [0|0] "" Vector__XXX
 SG_ PM_torqueDecelAvg m2 : 24|13@1- (2,0) [0|0] "" Vector__XXX
 SG_ PM_udsStackMax m68 : 24|16@1+ (1,0) [0|0] "" Vector__XXX
 SG_ PM_xcpStackMax m69 : 24|16@1+ (1,0) [0|0] "" Vector__XXX
 SG_ PM_sysPedalMaxTorque m16 : 23|15@1+ (0.5,0) [0|0] "" Vector__XXX
 SG_ PM_sysPostPedalMaxTorque m17 : 23|15@1+ (0.5,0) [0|0] "" Vector__XXX
 SG_ PM_cpu10HzMax m65 : 16|8@1+ (0.4,0) [0|0] "" Vector__XXX
 SG_ PM_cpu20kHzAvg m64 : 16|8@1+ (0.4,0) [0|0] "" Vector__XXX
 SG_ PM_pedalPosB m5 : 16|8@1+ (0.4,0) [0|0] "" Vector__XXX
 SG_ PM_vehicleHoldState m18 : 16|3@1+ (1,0) [0|0] "" Vector__XXX
 SG_ PM_aebState m18 : 11|3@1+ (1,0) [0|0] "" Vector__XXX
 SG_ PM_cpu100HzAvg m65 : 8|8@1+ (0.4,0) [0|0] "" Vector__XXX
 SG_ PM_cpu10kHzMin m66 : 8|8@1+ (0.4,0) [0|0] "" Vector__XXX
 SG_ PM_cpu1kHzMax m64 : 8|8@1+ (0.4,0) [0|0] "" Vector__XXX
 SG_ PM_gear m18 : 8|3@1+ (1,0) [0|0] "" Vector__XXX
 SG_ PM_idleStackSize m67 : 8|16@1+ (1,0) [0|0] "" Vector__XXX
 SG_ PM_pedalPos m5 : 8|8@1+ (0.4,0) [0|0] "" Vector__XXX
 SG_ PM_speedAverage m3 : 8|16@1- (0.1,0) [0|0] "" Vector__XXX
 SG_ PM_sysPedalMinTorque m16 : 8|15@1+ (0.5,-13000) [0|0] "" Vector__XXX
 SG_ PM_sysPostPedalMinTorque m17 : 8|15@1+ (0.5,-13000) [0|0] "" Vector__XXX
 SG_ PM_systemTorqueCommand m4 : 8|16@1- (0.5,0) [0|0] "" Vector__XXX
 SG_ PM_torqueDecelWindow m2 : 8|13@1- (2,0) [0|0] "" Vector__XXX
 SG_ PM_torqueSignError m1 : 8|13@1- (2,0) [0|0] "" Vector__XXX
 SG_ PM_udsStackSize m68 : 8|16@1+ (1,0) [0|0] "" Vector__XXX
 SG_ PM_xcpStackSize m69 : 8|16@1+ (1,0) [0|0] "" Vector__XXX
 SG_ PM_debugSelector M : 0|8@1+ (1,0) [0|0] "" Vector__XXX

BO_ 2002 BMS_debugInfo_1Hz: 8 Vector__XXX
 SG_ BMS_brickBleedDbg112 m1 : 63|1@1+ (1,0) [0|0] "" Vector__XXX
 SG_ BMS_brickBleedDbg56 m0 : 63|1@1+ (1,0) [0|0] "" Vector__XXX
 SG_ BMS_brickBleedDbg111 m1 : 62|1@1+ (1,0) [0|0] "" Vector__XXX
 SG_ BMS_brickBleedDbg55 m0 : 62|1@1+ (1,0) [0|0] "" Vector__XXX
 SG_ BMS_dbgEnergyVariableChgRequeste m2 : 62|1@1+ (1,0) [0|0] "" Vector__XXX
 SG_ BMS_brickBleedDbg110 m1 : 61|1@1+ (1,0) [0|0] "" Vector__XXX
 SG_ BMS_brickBleedDbg54 m0 : 61|1@1+ (1,0) [0|0] "" Vector__XXX
 SG_ BMS_brickBleedDbg109 m1 : 60|1@1+ (1,0) [0|0] "" Vector__XXX
 SG_ BMS_brickBleedDbg53 m0 : 60|1@1+ (1,0) [0|0] "" Vector__XXX
 SG_ BMS_brickBleedDbg108 m1 : 59|1@1+ (1,0) [0|0] "" Vector__XXX
 SG_ BMS_brickBleedDbg52 m0 : 59|1@1+ (1,0) [0|0] "" Vector__XXX
 SG_ BMS_brickBleedDbg107 m1 : 58|1@1+ (1,0) [0|0] "" Vector__XXX
 SG_ BMS_brickBleedDbg51 m0 : 58|1@1+ (1,0) [0|0] "" Vector__XXX
 SG_ BMS_brickBleedDbg106 m1 : 57|1@1+ (1,0) [0|0] "" Vector__XXX
 SG_ BMS_brickBleedDbg50 m0 : 57|1@1+ (1,0) [0|0] "" Vector__XXX
 SG_ BMS_brickBleedDbg105 m1 : 56|1@1+ (1,0) [0|0] "" Vector__XXX
 SG_ BMS_brickBleedDbg49 m0 : 56|1@1+ (1,0) [0|0] "" Vector__XXX
 SG_ BMS_energyInitialPackTemp m3 : 56|8@1- (1,40) [0|0] "" Vector__XXX
 SG_ BMS_brickBleedDbg104 m1 : 55|1@1+ (1,0) [0|0] "" Vector__XXX
 SG_ BMS_brickBleedDbg48 m0 : 55|1@1+ (1,0) [0|0] "" Vector__XXX
 SG_ BMS_brickBleedDbg103 m1 : 54|1@1+ (1,0) [0|0] "" Vector__XXX
 SG_ BMS_brickBleedDbg47 m0 : 54|1@1+ (1,0) [0|0] "" Vector__XXX
 SG_ BMS_dbgStackUse_UDS m4 : 54|10@1+ (1,0) [0|0] "" Vector__XXX
 SG_ BMS_brickBleedDbg102 m1 : 53|1@1+ (1,0) [0|0] "" Vector__XXX
 SG_ BMS_brickBleedDbg46 m0 : 53|1@1+ (1,0) [0|0] "" Vector__XXX
 SG_ BMS_brickBleedDbg101 m1 : 52|1@1+ (1,0) [0|0] "" Vector__XXX
 SG_ BMS_brickBleedDbg45 m0 : 52|1@1+ (1,0) [0|0] "" Vector__XXX
 SG_ BMS_energyStopTarget m2 : 52|10@1+ (0.1,0) [0|0] "" Vector__XXX
 SG_ BMS_brickBleedDbg100 m1 : 51|1@1+ (1,0) [0|0] "" Vector__XXX
 SG_ BMS_brickBleedDbg44 m0 : 51|1@1+ (1,0) [0|0] "" Vector__XXX
 SG_ BMS_brickBleedDbg43 m0 : 50|1@1+ (1,0) [0|0] "" Vector__XXX
 SG_ BMS_brickBleedDbg99 m1 : 50|1@1+ (1,0) [0|0] "" Vector__XXX
 SG_ BMS_brickBleedDbg42 m0 : 49|1@1+ (1,0) [0|0] "" Vector__XXX
 SG_ BMS_brickBleedDbg98 m1 : 49|1@1+ (1,0) [0|0] "" Vector__XXX
 SG_ BMS_brickBleedDbg41 m0 : 48|1@1+ (1,0) [0|0] "" Vector__XXX
 SG_ BMS_brickBleedDbg97 m1 : 48|1@1+ (1,0) [0|0] "" Vector__XXX
 SG_ BMS_brickBleedDbg40 m0 : 47|1@1+ (1,0) [0|0] "" Vector__XXX
 SG_ BMS_brickBleedDbg96 m1 : 47|1@1+ (1,0) [0|0] "" Vector__XXX
 SG_ BMS_brickBleedDbg39 m0 : 46|1@1+ (1,0) [0|0] "" Vector__XXX
 SG_ BMS_brickBleedDbg95 m1 : 46|1@1+ (1,0) [0|0] "" Vector__XXX
 SG_ BMS_brickBleedDbg38 m0 : 45|1@1+ (1,0) [0|0] "" Vector__XXX
 SG_ BMS_brickBleedDbg94 m1 : 45|1@1+ (1,0) [0|0] "" Vector__XXX
 SG_ BMS_brickBleedDbg37 m0 : 44|1@1+ (1,0) [0|0] "" Vector__XXX
 SG_ BMS_brickBleedDbg93 m1 : 44|1@1+ (1,0) [0|0] "" Vector__XXX
 SG_ BMS_dbgStackUse_1KHz m4 : 44|10@1+ (1,0) [0|0] "" Vector__XXX
 SG_ BMS_energyLatchedAveCac m3 : 44|12@1+ (0.1,0) [0|0] "" Vector__XXX
 SG_ BMS_brickBleedDbg36 m0 : 43|1@1+ (1,0) [0|0] "" Vector__XXX
 SG_ BMS_brickBleedDbg92 m1 : 43|1@1+ (1,0) [0|0] "" Vector__XXX
 SG_ BMS_brickBleedDbg35 m0 : 42|1@1+ (1,0) [0|0] "" Vector__XXX
 SG_ BMS_brickBleedDbg91 m1 : 42|1@1+ (1,0) [0|0] "" Vector__XXX
 SG_ BMS_energyChgTargetPackSoc m2 : 42|10@1+ (0.1,0) [0|0] "" Vector__XXX
 SG_ BMS_brickBleedDbg34 m0 : 41|1@1+ (1,0) [0|0] "" Vector__XXX
 SG_ BMS_brickBleedDbg90 m1 : 41|1@1+ (1,0) [0|0] "" Vector__XXX
 SG_ BMS_brickBleedDbg33 m0 : 40|1@1+ (1,0) [0|0] "" Vector__XXX
 SG_ BMS_brickBleedDbg89 m1 : 40|1@1+ (1,0) [0|0] "" Vector__XXX
 SG_ BMS_brickBleedDbg32 m0 : 39|1@1+ (1,0) [0|0] "" Vector__XXX
 SG_ BMS_brickBleedDbg88 m1 : 39|1@1+ (1,0) [0|0] "" Vector__XXX
 SG_ BMS_brickBleedDbg31 m0 : 38|1@1+ (1,0) [0|0] "" Vector__XXX
 SG_ BMS_brickBleedDbg87 m1 : 38|1@1+ (1,0) [0|0] "" Vector__XXX
 SG_ BMS_brickBleedDbg30 m0 : 37|1@1+ (1,0) [0|0] "" Vector__XXX
 SG_ BMS_brickBleedDbg86 m1 : 37|1@1+ (1,0) [0|0] "" Vector__XXX
 SG_ BMS_brickBleedDbg29 m0 : 36|1@1+ (1,0) [0|0] "" Vector__XXX
 SG_ BMS_brickBleedDbg85 m1 : 36|1@1+ (1,0) [0|0] "" Vector__XXX
 SG_ BMS_brickBleedDbg28 m0 : 35|1@1+ (1,0) [0|0] "" Vector__XXX
 SG_ BMS_brickBleedDbg84 m1 : 35|1@1+ (1,0) [0|0] "" Vector__XXX
 SG_ BMS_dchAhLimitingBrickIndex m2 : 35|7@1+ (1,0) [0|0] "" Vector__XXX
 SG_ BMS_brickBleedDbg27 m0 : 34|1@1+ (1,0) [0|0] "" Vector__XXX
 SG_ BMS_brickBleedDbg83 m1 : 34|1@1+ (1,0) [0|0] "" Vector__XXX
 SG_ BMS_dbgStackUse_100Hz m4 : 34|10@1+ (1,0) [0|0] "" Vector__XXX
 SG_ BMS_brickBleedDbg26 m0 : 33|1@1+ (1,0) [0|0] "" Vector__XXX
 SG_ BMS_brickBleedDbg82 m1 : 33|1@1+ (1,0) [0|0] "" Vector__XXX
 SG_ BMS_brickBleedDbg25 m0 : 32|1@1+ (1,0) [0|0] "" Vector__XXX
 SG_ BMS_brickBleedDbg81 m1 : 32|1@1+ (1,0) [0|0] "" Vector__XXX
 SG_ BMS_energyLatchedMinCac m3 : 32|12@1+ (0.1,0) [0|0] "" Vector__XXX
 SG_ BMS_brickBleedDbg24 m0 : 31|1@1+ (1,0) [0|0] "" Vector__XXX
 SG_ BMS_brickBleedDbg80 m1 : 31|1@1+ (1,0) [0|0] "" Vector__XXX
 SG_ BMS_brickBleedDbg23 m0 : 30|1@1+ (1,0) [0|0] "" Vector__XXX
 SG_ BMS_brickBleedDbg79 m1 : 30|1@1+ (1,0) [0|0] "" Vector__XXX
 SG_ BMS_brickBleedDbg22 m0 : 29|1@1+ (1,0) [0|0] "" Vector__XXX
 SG_ BMS_brickBleedDbg78 m1 : 29|1@1+ (1,0) [0|0] "" Vector__XXX
 SG_ BMS_brickBleedDbg21 m0 : 28|1@1+ (1,0) [0|0] "" Vector__XXX
 SG_ BMS_brickBleedDbg77 m1 : 28|1@1+ (1,0) [0|0] "" Vector__XXX
 SG_ BMS_chgAhLimitingBrickIndex m2 : 28|7@1+ (1,0) [0|0] "" Vector__XXX
 SG_ BMS_brickBleedDbg20 m0 : 27|1@1+ (1,0) [0|0] "" Vector__XXX
 SG_ BMS_brickBleedDbg76 m1 : 27|1@1+ (1,0) [0|0] "" Vector__XXX
 SG_ BMS_brickBleedDbg19 m0 : 26|1@1+ (1,0) [0|0] "" Vector__XXX
 SG_ BMS_brickBleedDbg75 m1 : 26|1@1+ (1,0) [0|0] "" Vector__XXX
 SG_ BMS_brickBleedDbg18 m0 : 25|1@1+ (1,0) [0|0] "" Vector__XXX
 SG_ BMS_brickBleedDbg74 m1 : 25|1@1+ (1,0) [0|0] "" Vector__XXX
 SG_ BMS_brickBleedDbg17 m0 : 24|1@1+ (1,0) [0|0] "" Vector__XXX
 SG_ BMS_brickBleedDbg73 m1 : 24|1@1+ (1,0) [0|0] "" Vector__XXX
 SG_ BMS_dbgStackUse_10Hz m4 : 24|10@1+ (1,0) [0|0] "" Vector__XXX
 SG_ BMS_brickBleedDbg16 m0 : 23|1@1+ (1,0) [0|0] "" Vector__XXX
 SG_ BMS_brickBleedDbg72 m1 : 23|1@1+ (1,0) [0|0] "" Vector__XXX
 SG_ BMS_brickBleedDbg15 m0 : 22|1@1+ (1,0) [0|0] "" Vector__XXX
 SG_ BMS_brickBleedDbg71 m1 : 22|1@1+ (1,0) [0|0] "" Vector__XXX
 SG_ BMS_energyLatchedAveSoc m3 : 22|10@1+ (0.1,0) [0|0] "" Vector__XXX
 SG_ BMS_brickBleedDbg14 m0 : 21|1@1+ (1,0) [0|0] "" Vector__XXX
 SG_ BMS_brickBleedDbg70 m1 : 21|1@1+ (1,0) [0|0] "" Vector__XXX
 SG_ BMS_brickBleedDbg13 m0 : 20|1@1+ (1,0) [0|0] "" Vector__XXX
 SG_ BMS_brickBleedDbg69 m1 : 20|1@1+ (1,0) [0|0] "" Vector__XXX
 SG_ BMS_brickBleedDbg12 m0 : 19|1@1+ (1,0) [0|0] "" Vector__XXX
 SG_ BMS_brickBleedDbg68 m1 : 19|1@1+ (1,0) [0|0] "" Vector__XXX
 SG_ BMS_brickBleedDbg11 m0 : 18|1@1+ (1,0) [0|0] "" Vector__XXX
 SG_ BMS_brickBleedDbg67 m1 : 18|1@1+ (1,0) [0|0] "" Vector__XXX
 SG_ BMS_brickBleedDbg10 m0 : 17|1@1+ (1,0) [0|0] "" Vector__XXX
 SG_ BMS_brickBleedDbg66 m1 : 17|1@1+ (1,0) [0|0] "" Vector__XXX
 SG_ BMS_brickBleedDbg65 m1 : 16|1@1+ (1,0) [0|0] "" Vector__XXX
 SG_ BMS_brickBleedDbg9 m0 : 16|1@1+ (1,0) [0|0] "" Vector__XXX
 SG_ BMS_dbgStoredEpochTime m12 : 16|32@1+ (1,0) [0|0] "" Vector__XXX
 SG_ BMS_energyDchAhRemaining m2 : 16|12@1+ (0.1,0) [0|0] "" Vector__XXX
 SG_ BMS_brickBleedDbg64 m1 : 15|1@1+ (1,0) [0|0] "" Vector__XXX
 SG_ BMS_brickBleedDbg8 m0 : 15|1@1+ (1,0) [0|0] "" Vector__XXX
 SG_ BMS_brickBleedDbg63 m1 : 14|1@1+ (1,0) [0|0] "" Vector__XXX
 SG_ BMS_brickBleedDbg7 m0 : 14|1@1+ (1,0) [0|0] "" Vector__XXX
 SG_ BMS_dbgStackUse_1Hz m4 : 14|10@1+ (2,0) [0|0] "" Vector__XXX
 SG_ BMS_brickBleedDbg6 m0 : 13|1@1+ (1,0) [0|0] "" Vector__XXX
 SG_ BMS_brickBleedDbg62 m1 : 13|1@1+ (1,0) [0|0] "" Vector__XXX
 SG_ BMS_brickBleedDbg5 m0 : 12|1@1+ (1,0) [0|0] "" Vector__XXX
 SG_ BMS_brickBleedDbg61 m1 : 12|1@1+ (1,0) [0|0] "" Vector__XXX
 SG_ BMS_energyLatchedMinSoc m3 : 12|10@1+ (0.1,0) [0|0] "" Vector__XXX
 SG_ BMS_brickBleedDbg4 m0 : 11|1@1+ (1,0) [0|0] "" Vector__XXX
 SG_ BMS_brickBleedDbg60 m1 : 11|1@1+ (1,0) [0|0] "" Vector__XXX
 SG_ BMS_brickBleedDbg3 m0 : 10|1@1+ (1,0) [0|0] "" Vector__XXX
 SG_ BMS_brickBleedDbg59 m1 : 10|1@1+ (1,0) [0|0] "" Vector__XXX
 SG_ BMS_brickBleedDbg2 m0 : 9|1@1+ (1,0) [0|0] "" Vector__XXX
 SG_ BMS_brickBleedDbg58 m1 : 9|1@1+ (1,0) [0|0] "" Vector__XXX
 SG_ BMS_brickBleedDbg1 m0 : 8|1@1+ (1,0) [0|0] "" Vector__XXX
 SG_ BMS_brickBleedDbg57 m1 : 8|1@1+ (1,0) [0|0] "" Vector__XXX
 SG_ BMS_dbgBirthDateModule1 m6 : 8|32@1+ (1,0) [0|0] "" Vector__XXX
 SG_ BMS_dbgBirthDateModule2 m7 : 8|32@1+ (1,0) [0|0] "" Vector__XXX
 SG_ BMS_dbgBirthDateModule3 m8 : 8|32@1+ (1,0) [0|0] "" Vector__XXX
 SG_ BMS_dbgBirthDateModule4 m9 : 8|32@1+ (1,0) [0|0] "" Vector__XXX
 SG_ BMS_dbgPackBirthDate m5 : 8|32@1+ (1,0) [0|0] "" Vector__XXX
 SG_ BMS_dbgEpochTimeCorrectionCount m3 : 4|8@1+ (1,0) [0|0] "" Vector__XXX
 SG_ BMS_dbgMinBrickTempForFullWallPo m12 : 4|11@1+ (0.1,-50) [0|0] "" Vector__XXX
 SG_ BMS_dbgStackUse_Idle m11 : 4|10@1+ (2,0) [0|0] "" Vector__XXX
 SG_ BMS_dbgStackUse_Nvram m4 : 4|10@1+ (1,0) [0|0] "" Vector__XXX
 SG_ BMS_energyChgAhRemaining m2 : 4|12@1+ (0.1,0) [0|0] "" Vector__XXX
 SG_ BMS_1HzDebug_Id M : 0|4@1+ (1,0) [0|0] "" Vector__XXX

BO_ 2004 PMR_debug: 8 Vector__XXX
 SG_ PMR_resolverDiMIA m17 : 57|1@1+ (1,0) [0|0] "" Vector__XXX
 SG_ PMR_cpu100HzMin m64 : 56|8@1+ (0.4,0) [0|0] "" Vector__XXX
 SG_ PMR_cpu10kHzMax m65 : 56|8@1+ (0.4,0) [0|0] "" Vector__XXX
 SG_ PMR_lmSatCoeff m3 : 56|8@1+ (0.00391,0) [0|0] "" Vector__XXX
 SG_ PMR_resolverClaMIA m17 : 56|1@1+ (1,0) [0|0] "" Vector__XXX
 SG_ PMR_statorT m4 : 56|8@1+ (1,-40) [0|0] "" Vector__XXX
 SG_ PMR_resolverPhaseOutOfSpec m17 : 55|1@1+ (1,0) [0|0] "" Vector__XXX
 SG_ PMR_resolverNoCarrier m17 : 54|1@1+ (1,0) [0|0] "" Vector__XXX
 SG_ PMR_cpu1kHzAvg m64 : 48|8@1+ (0.4,0) [0|0] "" Vector__XXX
 SG_ PMR_cpu20kHzMin m65 : 48|8@1+ (0.4,0) [0|0] "" Vector__XXX
 SG_ PMR_resolverOffsetExt m17 : 48|6@1+ (0.053,0) [0|0] "" Vector__XXX
 SG_ PMR_torqueOutOfMap m5 : 47|1@1+ (1,0) [0|0] "" Vector__XXX
 SG_ PMR_switchingActive m5 : 46|1@1+ (1,0) [0|0] "" Vector__XXX
 SG_ PMR_cpu100HzMax m64 : 40|8@1+ (0.4,0) [0|0] "" Vector__XXX
 SG_ PMR_cpu20kHzMax m65 : 40|8@1+ (0.4,0) [0|0] "" Vector__XXX
 SG_ PMR_iDQmagnitude m3 : 40|16@1- (0.0939,0) [0|0] "" Vector__XXX
 SG_ PMR_motorRPM m4 : 40|16@1- (1,0) [0|0] "" Vector__XXX
 SG_ PMR_resolverOffsetSin m17 : 40|6@1+ (0.053,0) [0|0] "" Vector__XXX
 SG_ PMR_torqueAccelAvg m1 : 40|13@1- (2,0) [0|0] "" Vector__XXX
 SG_ PMR_torqueReversalWindow m2 : 40|13@1- (2,0) [0|0] "" Vector__XXX
 SG_ PMR_cpu10HzMin m65 : 32|8@1+ (0.4,0) [0|0] "" Vector__XXX
 SG_ PMR_cpu10kHzAvg m64 : 32|8@1+ (0.4,0) [0|0] "" Vector__XXX
 SG_ PMR_resolverOffsetCos m17 : 32|6@1+ (0.053,0) [0|0] "" Vector__XXX
 SG_ PMR_Ib m3 : 24|16@1- (0.0939,0) [0|0] "" Vector__XXX
 SG_ PMR_cpu10HzAvg m65 : 24|8@1+ (0.4,0) [0|0] "" Vector__XXX
 SG_ PMR_cpu1kHzMin m64 : 24|8@1+ (0.4,0) [0|0] "" Vector__XXX
 SG_ PMR_idleStackMax m67 : 24|16@1+ (1,0) [0|0] "" Vector__XXX
 SG_ PMR_resolverExcitationGain m17 : 24|7@1+ (0.063,0) [0|0] "" Vector__XXX
 SG_ PMR_sysStackMax m70 : 24|16@1+ (1,0) [0|0] "" Vector__XXX
 SG_ PMR_torqueAccelWindow m1 : 24|13@1- (2,0) [0|0] "" Vector__XXX
 SG_ PMR_torqueDecelAvg m2 : 24|13@1- (2,0) [0|0] "" Vector__XXX
 SG_ PMR_udsStackMax m68 : 24|16@1+ (1,0) [0|0] "" Vector__XXX
 SG_ PMR_xcpStackMax m69 : 24|16@1+ (1,0) [0|0] "" Vector__XXX
 SG_ PMR_offsetIb m5 : 20|12@1- (0.1,0) [0|0] "" Vector__XXX
 SG_ PMR_resolverCommonGain m17 : 17|7@1+ (0.063,0) [0|0] "" Vector__XXX
 SG_ PMR_cpu10HzMax m65 : 16|8@1+ (0.4,0) [0|0] "" Vector__XXX
 SG_ PMR_cpu20kHzAvg m64 : 16|8@1+ (0.4,0) [0|0] "" Vector__XXX
 SG_ PMR_Ia m3 : 8|16@1- (0.0939,0) [0|0] "" Vector__XXX
 SG_ PMR_cpu100HzAvg m65 : 8|8@1+ (0.4,0) [0|0] "" Vector__XXX
 SG_ PMR_cpu10kHzMin m66 : 8|8@1+ (0.4,0) [0|0] "" Vector__XXX
 SG_ PMR_cpu1kHzMax m64 : 8|8@1+ (0.4,0) [0|0] "" Vector__XXX
 SG_ PMR_idleStackSize m67 : 8|16@1+ (1,0) [0|0] "" Vector__XXX
 SG_ PMR_offsetIa m5 : 8|12@1- (0.1,0) [0|0] "" Vector__XXX
 SG_ PMR_resolverPhaseAngle m17 : 8|9@1+ (0.001537,0) [0|0] "" Vector__XXX
 SG_ PMR_resolverSpeedError m16 : 8|16@1- (0.75,0) [0|0] "" Vector__XXX
 SG_ PMR_slipFrequency m4 : 8|16@1- (0.005,0) [0|0] "" Vector__XXX
 SG_ PMR_sysStackSize m70 : 8|16@1+ (1,0) [0|0] "" Vector__XXX
 SG_ PMR_torqueDecelWindow m2 : 8|13@1- (2,0) [0|0] "" Vector__XXX
 SG_ PMR_torqueSignError m1 : 8|13@1- (2,0) [0|0] "" Vector__XXX
 SG_ PMR_udsStackSize m68 : 8|16@1+ (1,0) [0|0] "" Vector__XXX
 SG_ PMR_xcpStackSize m69 : 8|16@1+ (1,0) [0|0] "" Vector__XXX
 SG_ PMR_debugSelector M : 0|8@1+ (1,0) [0|0] "" Vector__XXX

CM_ BO_ 1666 "ESP32-DualCAN Model3_VEH. Seen on this car: 8-byte frames; fit ok (bits covered 100%, mux 100%, ranges 100%, checksum 0%).";
VAL_ 1666 HVP_hvilStatus 0 "UNKNOWN" 1 "OK" 2 "FAULT" ;
CM_ BO_ 1668 "ESP32-DualCAN Model3_VEH. Not seen on this car in the logs.";
CM_ BO_ 1669 "ESP32-DualCAN Model3_VEH. Not seen on this car in the logs.";
CM_ BO_ 1673 "ESP32-DualCAN Model3_VEH. Not seen on this car in the logs.";
CM_ BO_ 1680 "ESP32-DualCAN Model3_VEH. Not seen on this car in the logs.";
VAL_ 1680 SCCM_functionalResponseData_0 0 "0" 1 "1" 2 "2" 3 "3" 4 "4" 5 "5" 6 "6" 7 "7" 8 "8" 9 "9" 10 "10" 11 "11" 12 "12" 13 "13" 14 "14" 15 "15" 16 "16" 17 "17" 18 "18" 19 "19" 20 "20" 21 "21" 22 "22" 23 "23" 24 "24" 25 "25" 26 "26" 27 "27" 28 "28" 29 "29" 30 "30" 31 "31" ;
CM_ BO_ 1697 "ESP32-DualCAN Model3_VEH. Not seen on this car in the logs.";
CM_ BO_ 1698 "ESP32-DualCAN Model3_VEH. Seen on this car: 4-byte frames; fit poor (bits covered 0%, mux 100%, ranges 100%).; 1 signals past the 4 bytes this car sends were left out";
CM_ BO_ 1723 "ESP32-DualCAN Model3_VEH. Seen on this car: 8-byte frames; fit poor (bits covered 0%, mux 100%, ranges 100%).";
CM_ BO_ 1734 "ESP32-DualCAN Model3_VEH. Not seen on this car in the logs.";
CM_ BO_ 1736 "ESP32-DualCAN Model3_VEH. Seen on this car: 8-byte frames; fit good (bits covered 100%, mux 100%, ranges 100%).";
CM_ BO_ 1750 "ESP32-DualCAN Model3_VEH. Not seen on this car in the logs.";
CM_ BO_ 1766 "ESP32-DualCAN Model3_VEH. Not seen on this car in the logs.";
CM_ BO_ 1767 "ESP32-DualCAN Model3_VEH. Not seen on this car in the logs.";
CM_ BO_ 1768 "ESP32-DualCAN Model3_VEH. Seen on this car: 8-byte frames; fit good (bits covered 100%, mux 100%, ranges 100%).";
CM_ BO_ 1776 "Alive message: checksum + counter only; no data seen (route 494, 2026-11-19). CRC-8 SAE J1850 over byte 1.";
CM_ BO_ 1779 "Alive message: checksum + counter only; no data seen (route 494, 2026-11-19). CRC-8 SAE J1850 over bytes 1-2; byte 2 always 0.";
CM_ BO_ 1787 "ESP32-DualCAN Model3_VEH. Not seen on this car in the logs.";
CM_ BO_ 1793 "ESP32-DualCAN Model3_VEH. Not seen on this car in the logs.";
VAL_ 1793 VCFRONT_debugThermal10HzIndex 0 "heaterAndEvapWatts" 1 "temps" 2 "airflow" 3 "cabinModel" 4 "actuatorStatus" 5 "END" ;
CM_ BO_ 1796 "ESP32-DualCAN Model3_VEH. Not seen on this car in the logs.";
CM_ BO_ 1797 "ESP32-DualCAN Model3_VEH. Not seen on this car in the logs.";
CM_ BO_ 1798 "ESP32-DualCAN Model3_VEH. Not seen on this car in the logs.";
CM_ BO_ 1799 "ESP32-DualCAN Model3_VEH. Seen on this car: 8-byte frames; fit weak (bits covered 0%, mux 100%, ranges 100%).";
CM_ BO_ 1800 "ESP32-DualCAN Model3_VEH. Seen on this car: 5-byte frames; fit ok (bits covered 100%, mux 100%, ranges 100%).";
CM_ BO_ 1801 "ESP32-DualCAN Model3_VEH. Seen on this car: 8-byte frames; fit good (bits covered 100%, mux 81%, ranges 100%).";
CM_ BO_ 1802 "ESP32-DualCAN Model3_VEH. Seen on this car: 5-byte frames; fit ok (bits covered 100%, mux 100%, ranges 100%).";
CM_ BO_ 1803 "ESP32-DualCAN Model3_VEH. Seen on this car: 8-byte frames; fit good (bits covered 100%, mux 90%, ranges 100%).";
VAL_ 1803 VCRIGHT_tempIncarCabinDeep 255 "SNA" ;
CM_ BO_ 1806 "ESP32-DualCAN Model3_CH. Seen on this car: 8-byte frames; fit good (bits covered 100%, mux 100%, ranges 100%).";
CM_ BO_ 1807 "ESP32-DualCAN Model3_CH. Seen on this car: 8-byte frames; fit good (bits covered 100%, mux 100%, ranges 100%).";
CM_ BO_ 1810 "ESP32-DualCAN Model3_VEH. Seen on this car: 8-byte frames; fit good (bits covered 100%, mux 100%, ranges 100%).";
CM_ BO_ 1812 "ESP32-DualCAN Model3_VEH. Not seen on this car in the logs.";
CM_ BO_ 1814 "ESP32-DualCAN Model3_VEH. Not seen on this car in the logs.";
CM_ BO_ 1815 "ESP32-DualCAN Model3_VEH. Seen on this car: 7-byte frames; fit ok (bits covered 100%, mux 100%, ranges 100%).";
CM_ BO_ 1816 "ESP32-DualCAN Model3_VEH. Seen on this car: 8-byte frames; fit good (bits covered 90%, mux 100%, ranges 100%).";
VAL_ 1816 VC_LVBMS_SOP 16777215 "SNA" ;
VAL_ 1816 VC_LVBMS_MaxSleepCurrent 65535 "SNA" ;
VAL_ 1816 VC_LVBMS_MinSleepCurrent 65535 "SNA" ;
VAL_ 1816 VC_LVBMS_dynamicSOCCorrection 0 "INACTIVE" 1 "ACTIVE" ;
VAL_ 1816 VC_LVBMS_staticSOCCorrection 0 "INACTIVE" 1 "ACTIVE" ;
VAL_ 1816 VC_LVBMS_minCellSOC 127 "SNA" ;
VAL_ 1816 VC_LVBMS_SOH 127 "SNA" ;
VAL_ 1816 VC_LVBMS_TimeSlept 16777215 "SNA" ;
VAL_ 1816 VC_LVBMS_maxCellSOC 127 "SNA" ;
VAL_ 1816 VC_LVBMS_SOE 127 "SNA" ;
VAL_ 1816 VC_LVBMS_AvgSleepCurrent 65535 "SNA" ;
VAL_ 1816 VC_LVBMS_SOC 127 "SNA" ;
VAL_ 1816 VC_LVBMS_sumCellVoltageFiltered 65534 "INVALID" 65535 "SNA" ;
VAL_ 1816 VC_lvbmsStatusLowIndex 0 "STATE" 1 "THROUGHPUT_1" 2 "THROUGHPUT_2" 3 "THROUGHPUT_3" 4 "PACK_VITALS_2" 5 "FAULT_STATS" 6 "CELL_VITALS_3" 7 "CELL_VITALS_4" 8 "INVALID" ;
CM_ BO_ 1817 "ESP32-DualCAN Model3_VEH. Seen on this car: 8-byte frames; fit good (bits covered 100%, mux 100%, ranges 100%).";
CM_ BO_ 1822 "ESP32-DualCAN Model3_VEH. Not seen on this car in the logs.";
VAL_ 1822 GB_EVSE_maxCurrentLimit_value 4294934528 "SNA" ;
VAL_ 1822 GB_EVSE_outputCurrent_value 4294934528 "SNA" ;
VAL_ 1822 GB_FC_maxCurrentLimit 8191 "SNA" ;
CM_ BO_ 1824 "ESP32-DualCAN Model3_VEH. Seen on this car: 5-byte frames; fit poor (bits covered 0%, mux 100%, ranges 100%).";
CM_ BO_ 1825 "ESP32-DualCAN Model3_VEH. Not seen on this car in the logs.";
CM_ BO_ 1826 "ESP32-DualCAN Model3_CH. Not seen on this car in the logs.";
VAL_ 1826 DAS_ussSensorIdY 0 "REAR_INNER" 1 "REAR_CORNER" 2 "REAR_SIDE" 3 "FRONT_INNER" 4 "FRONT_CORNER" 5 "FRONT_SIDE" ;
CM_ BO_ 1827 "ESP32-DualCAN Model3_CH. Not seen on this car in the logs.";
VAL_ 1827 UI_ussSensorIdX 0 "REAR_INNER" 1 "REAR_CORNER" 2 "REAR_SIDE" 3 "FRONT_INNER" 4 "FRONT_CORNER" 5 "FRONT_SIDE" ;
CM_ BO_ 1828 "ESP32-DualCAN Model3_VEH. Seen on this car: 3-byte frames; fit ok (bits covered 100%, mux 100%, ranges 100%).";
VAL_ 1828 VCFRONT_loadShedStsBatteryPump_duty 127 "SNA" ;
VAL_ 1828 VCFRONT_loadShedStsCondenserFan_duty 127 "SNA" ;
VAL_ 1828 VCFRONT_loadShedStsPTPump_duty 127 "SNA" ;
CM_ BO_ 1829 "ESP32-DualCAN Model3_VEH. Not seen on this car in the logs.";
VAL_ 1829 VCBATT2_loadShedStsBatteryPump_d 127 "SNA" ;
VAL_ 1829 VCBATT2_loadShedStsCondenserFan_ 127 "SNA" ;
VAL_ 1829 VCBATT2_loadShedStsPTPump_duty 127 "SNA" ;
CM_ BO_ 1830 "ESP32-DualCAN Model3_VEH. Seen on this car: 3-byte frames; fit ok (bits covered 100%, mux 100%, ranges 100%).";
VAL_ 1830 VCLEFT_loadShedStsHVACBlower_duty 127 "SNA" ;
CM_ BO_ 1831 "ESP32-DualCAN Model3_VEH. Seen on this car: 2-byte frames; fit ok (bits covered 100%, mux 100%, ranges 100%).";
CM_ BO_ 1833 "ESP32-DualCAN Model3_CH. Not seen on this car in the logs.";
CM_ BO_ 1834 "ESP32-DualCAN Model3_VEH. Seen on this car: 8-byte frames; fit good (bits covered 100%, mux 100%, ranges 100%).";
CM_ BO_ 1835 "ESP32-DualCAN Model3_VEH. Not seen on this car in the logs.";
CM_ BO_ 1840 "ESP32-DualCAN Model3_CH.";
CM_ BO_ 1842 "ESP32-DualCAN Model3_VEH. Not seen on this car in the logs.";
CM_ BO_ 1847 "ESP32-DualCAN Model3_VEH. Seen on this car: 7-byte frames; fit ok (bits covered 100%, mux 100%, ranges 100%).";
VAL_ 1847 VCFRONT_LVBMS_FWBuildType 0 "UNKNOWN_BUILD" 1 "PLATFORM_BUILD" 2 "LOCAL_BUILD" 3 "TRACEABLE_CI_BUILD" 4 "MFG_BUILD" ;
VAL_ 1847 VCFRONT_LVBMS_InfoIndex 0 "PCBAID_ASSYID" 1 "APP_USAGEID_CRC" 2 "GITHASH" 3 "BUILDTYPE" 4 "SERIAL_NUMBER" 5 "INVALID" ;
CM_ BO_ 1848 "ESP32-DualCAN Model3_CH. Not seen on this car in the logs.";
CM_ BO_ 1849 "ESP32-DualCAN Model3_VEH. Seen on this car: 5-byte frames; fit ok (bits covered 100%, mux 100%, ranges 100%).";
CM_ BO_ 1850 "ESP32-DualCAN Model3_VEH. Seen on this car: 8-byte frames; fit good (bits covered 100%, mux 100%, ranges 100%).";
CM_ BO_ 1851 "ESP32-DualCAN Model3_VEH. Not seen on this car in the logs.";
CM_ BO_ 1853 "ESP32-DualCAN Model3_VEH. Not seen on this car in the logs.";
CM_ BO_ 1854 "ESP32-DualCAN Model3_VEH. Not seen on this car in the logs.";
VAL_ 1854 VEH_chargeCurrent_exp_log 0 "NO_CHARGER_PRESENT" 1 "DC_CHARGER_PRESENT" 2 "AC_CHARGER_PRESENT" ;
VAL_ 1854 VEH_GB_SOC 127 "SNA" ;
VAL_ 1854 VEH_currentDemand_exp_log 0 "NO_CHARGER_PRESENT" 1 "DC_CHARGER_PRESENT" 2 "AC_CHARGER_PRESENT" ;
VAL_ 1854 VEH_GB_BAT_SOC 127 "SNA" ;
VAL_ 1854 VEH_chargeCurrent_value_log 0 "NO_CHARGER_PRESENT" 1 "DC_CHARGER_PRESENT" 2 "AC_CHARGER_PRESENT" ;
VAL_ 1854 VEH_GB_Final_SOC 127 "SNA" ;
VAL_ 1854 VEH_GB_Protocol_Ver_log 0 "NO_CHARGER_PRESENT" 1 "DC_CHARGER_PRESENT" 2 "AC_CHARGER_PRESENT" ;
VAL_ 1854 VEH_GB_Status 0 "IDLE" 1 "RX" ;
VAL_ 1854 VEH_currentDemand_value_log 0 "NO_CHARGER_PRESENT" 1 "DC_CHARGER_PRESENT" 2 "AC_CHARGER_PRESENT" ;
VAL_ 1854 VEH_teslaGbProtocolVersion_log 0 "NO_CHARGER_PRESENT" 1 "DC_CHARGER_PRESENT" 2 "AC_CHARGER_PRESENT" ;
VAL_ 1854 VEH_GB_Chg_Stop_Rsn_SOC 127 "SNA" ;
CM_ BO_ 1856 "ESP32-DualCAN Model3_CH.";
CM_ BO_ 1858 "ESP32-DualCAN Model3_VEH. Seen on this car: 8-byte frames; fit weak (bits covered 0%, mux 100%, ranges 100%).";
VAL_ 1858 VCBATT1_LVBMS_MOSTemperature 4095 "SNA" ;
VAL_ 1858 VCBATT1_LVBMS_maxAllowedDischargeCurrent 8191 "SNA" ;
VAL_ 1858 VCBATT1_LVBMS_packTemperature 511 "SNA" ;
VAL_ 1858 VCBATT1_LVBMS_maxAllowedChargeCurrent 8191 "SNA" ;
VAL_ 1858 VCBATT1_LVBMS_packVoltage 65535 "SNA" ;
VAL_ 1858 VCBATT1_LVBMS_currentTarget 32767 "SNA" ;
VAL_ 1858 VCBATT1_LVBMS_chargeType 0 "UNDEFINED" 1 "CONSTANT_CURRENT" 2 "CONSTANT_VOLTAGE" 3 "COMPLETE" 4 "SNA" ;
VAL_ 1858 VCBATT1_LVBMS_LINWakeDisabled 0 "ENABLED" 1 "DISABLED" ;
VAL_ 1858 VCBATT1_LVBMS_VehicleState 0 "DRIVE" 1 "ACCESSORY" 2 "CONDITIONING" 3 "OFF" ;
VAL_ 1858 VCBATT1_LVBMS_MOSState 0 "OPEN" 1 "CLOSED" 2 "INVALID" 3 "SNA" ;
VAL_ 1858 VCBATT1_LVBMS_ECPAState 0 "OPEN" 1 "CLOSED" 2 "INVALID" 3 "SNA" ;
VAL_ 1858 VCBATT1_LVBMS_sumCellVoltage 65534 "INVALID" 65535 "SNA" ;
VAL_ 1858 VCBATT1_LVBMS_packCurrent 4294934528 "SNA" ;
VAL_ 1858 VCBATT1_LVBMS_voltageTarget 32767 "SNA" ;
VAL_ 1858 VCBATT1_lvbmsStatusHighIndex 0 "PACK_VITALS_1" 1 "CELL_VITALS_1" 2 "CELL_VITALS_2" 3 "TARGETS" 4 "STATE_AND_COMMANDS" 5 "PCS_INTERFACE" 6 "INVALID" ;
CM_ BO_ 1863 "ESP32-DualCAN Model3_VEH. Not seen on this car in the logs.";
CM_ BO_ 1864 "ESP32-DualCAN Model3_VEH. Seen on this car: 5-byte frames; fit ok (bits covered 100%, mux 100%, ranges 100%).";
CM_ BO_ 1870 "ESP32-DualCAN Model3_VEH. Seen on this car: 8-byte frames; fit poor (bits covered 0%, mux 100%, ranges 100%).";
CM_ BO_ 1871 "ESP32-DualCAN Model3_VEH. Seen on this car: 8-byte frames; fit poor (bits covered 0%, mux 100%, ranges 100%).";
CM_ BO_ 1872 "ESP32-DualCAN Model3_VEH. Not seen on this car in the logs.";
CM_ BO_ 1873 "ESP32-DualCAN Model3_VEH. Not seen on this car in the logs.";
CM_ BO_ 1874 "ESP32-DualCAN Model3_VEH. Seen on this car: 8-byte frames; fit good (bits covered 100%, mux 100%, ranges 100%).";
VAL_ 1874 BMS_100HzDebug_Id 0 "MUX0" 1 "MUX1" 2 "MUX2" 3 "MUX3" 4 "MUX4" 5 "MUX5" 6 "MUX6" 7 "MUX7" 8 "MUX8" 9 "MUX9" 10 "MUX10" 11 "MUX11" 12 "MUX12" 13 "MUX13" 14 "END" ;
CM_ BO_ 1875 "ESP32-DualCAN Model3_VEH. Not seen on this car in the logs.";
CM_ BO_ 1876 "ESP32-DualCAN Model3_VEH. Not seen on this car in the logs.";
CM_ BO_ 1877 "ESP32-DualCAN Model3_VEH. Not seen on this car in the logs.";
CM_ BO_ 1878 "ESP32-DualCAN Model3_VEH. Not seen on this car in the logs.";
CM_ BO_ 1879 "ESP32-DualCAN Model3_VEH. Seen on this car: 8-byte frames; fit poor (bits covered 0%, mux 0%, ranges 100%).";
VAL_ 1879 DIF_debugSelector 64 "Mux64" 128 "Mux128" 66 "Mux66" 67 "Mux67" 131 "Mux131" 68 "Mux68" 132 "Mux132" 69 "Mux69" 70 "Mux70" 72 "Mux72" 32 "Mux32" 33 "Mux33" 34 "Mux34" 35 "Mux35" 36 "Mux36" 37 "Mux37" 38 "Mux38" 39 "Mux39" 40 "Mux40" 41 "Mux41" 42 "Mux42" 43 "Mux43" 46 "Mux46" 47 "Mux47" 48 "Mux48" 49 "Mux49" 50 "Mux50" 52 "Mux52" 63 "Mux63" ;
CM_ BO_ 1881 "ESP32-DualCAN Model3_VEH. Not seen on this car in the logs.";
CM_ BO_ 1882 "ESP32-DualCAN Model3_VEH. Not seen on this car in the logs.";
CM_ BO_ 1883 "ESP32-DualCAN Model3_VEH. Not seen on this car in the logs.";
CM_ BO_ 1886 "ESP32-DualCAN Model3_VEH. Not seen on this car in the logs.";
VAL_ 1886 CA_VEH_BAT_SOC 127 "SNA" ;
CM_ BO_ 1889 "ESP32-DualCAN Model3_VEH. Not seen on this car in the logs.";
VAL_ 1889 PMF_debugSelector 64 "Mux64" 128 "Mux128" 66 "Mux66" 67 "Mux67" 131 "Mux131" 68 "Mux68" 132 "Mux132" 69 "Mux69" 70 "Mux70" 72 "Mux72" 32 "Mux32" 33 "Mux33" 34 "Mux34" 35 "Mux35" 36 "Mux36" 37 "Mux37" 38 "Mux38" 39 "Mux39" 40 "Mux40" 41 "Mux41" 42 "Mux42" 43 "Mux43" 46 "Mux46" 47 "Mux47" 48 "Mux48" 49 "Mux49" 50 "Mux50" 52 "Mux52" 63 "Mux63" ;
CM_ BO_ 1890 "ESP32-DualCAN Model3_VEH. Not seen on this car in the logs.";
CM_ BO_ 1891 "ESP32-DualCAN Model3_VEH. Not seen on this car in the logs.";
CM_ BO_ 1892 "ESP32-DualCAN Model3_VEH. Not seen on this car in the logs.";
CM_ BO_ 1894 "ESP32-DualCAN Model3_VEH. Not seen on this car in the logs.";
CM_ BO_ 1896 "ESP32-DualCAN Model3_VEH. Not seen on this car in the logs.";
CM_ BO_ 1897 "ESP32-DualCAN Model3_VEH. Seen on this car: 8-byte frames; fit weak (bits covered 0%, mux 100%, ranges 100%).";
CM_ BO_ 1899 "ESP32-DualCAN Model3_VEH. Not seen on this car in the logs.";
CM_ BO_ 1904 "ESP32-DualCAN Model3_VEH. Not seen on this car in the logs.";
CM_ BO_ 1910 "ESP32-DualCAN Model3_VEH. Not seen on this car in the logs.";
CM_ BO_ 1911 "ESP32-DualCAN Model3_VEH. Not seen on this car in the logs.";
CM_ BO_ 1914 "ESP32-DualCAN Model3_VEH. Seen on this car: 8-byte frames; fit good (bits covered 100%, mux 100%, ranges 100%).";
CM_ BO_ 1917 "ESP32-DualCAN Model3_VEH. Seen on this car: 4-byte frames; fit ok (bits covered 100%, mux 100%, ranges 100%).";
CM_ BO_ 1922 "ESP32-DualCAN Model3_VEH. Seen on this car: 8-byte frames; fit good (bits covered 100%, mux 100%, ranges 100%).";
CM_ BO_ 1924 "ESP32-DualCAN Model3_VEH. Not seen on this car in the logs.";
CM_ BO_ 1926 "ESP32-DualCAN Model3_VEH. Not seen on this car in the logs.";
VAL_ 1926 DBG_vehicleSpeed 8191 "SNA" ;
CM_ BO_ 1928 "ESP32-DualCAN Model3_VEH. Seen on this car: 8-byte frames; fit good (bits covered 100%, mux 100%, ranges 100%).";
VAL_ 1928 EPBL_esmCaliperRequest 0 "INVALID" 1 "NONE" 2 "APPLY" 3 "RELEASE" 4 "ENDSTOP" ;
VAL_ 1928 EPBL_pid_duty 127 "SNA" ;
CM_ BO_ 1929 "ESP32-DualCAN Model3_VEH. Seen on this car: 4-byte frames; fit weak (bits covered 100%, mux 100%, ranges 100%, checksum 0%).";
VAL_ 1929 EPBL_vehiclePowerStateDBG 0 "INIT" 1 "LOW_POWER_AWAKE" 2 "CONDITIONING" 3 "ACCESSORY" 4 "ACCESSORY_PLUS" 5 "DRIVE" 6 "OTA" 7 "WAIT_FOR_HIGH_POWER" 8 "TURN_ON_LV" 9 "SYSTEM_CHECKS" 10 "LV_ON" 11 "JUMP_START" 12 "LV_SHUTDOWN" 13 "GO_QUIET" 14 "SLEEP_SHUTDOWN" 15 "LOW_POWER_STANDBY" 16 "RESET" ;
VAL_ 1929 EPBL_lumbarLVState 0 "OFF" 1 "ON" 2 "GOING_DOWN" 3 "FAULT" ;
VAL_ 1929 EPBL_rcmLVState 0 "OFF" 1 "ON" 2 "GOING_DOWN" 3 "FAULT" ;
CM_ BO_ 1930 "ESP32-DualCAN Model3_VEH. Seen on this car: 8-byte frames; fit good (bits covered 100%, mux 100%, ranges 100%).";
CM_ BO_ 1931 "ESP32-DualCAN Model3_VEH. Not seen on this car in the logs.";
CM_ BO_ 1932 "ESP32-DualCAN Model3_VEH. Not seen on this car in the logs.";
CM_ BO_ 1936 "ESP32-DualCAN Model3_CH. Not seen on this car in the logs.";
CM_ BO_ 1940 "ESP32-DualCAN Model3_VEH. Not seen on this car in the logs.";
CM_ BO_ 1942 "ESP32-DualCAN Model3_VEH. Not seen on this car in the logs.";
CM_ BO_ 1943 "ESP32-DualCAN Model3_VEH. Seen on this car: 4-byte frames; fit weak (bits covered 100%, mux 100%, ranges 100%, checksum 0%).";
VAL_ 1943 EPBR_vehiclePowerStateDBG 0 "INIT" 1 "LOW_POWER_AWAKE" 2 "CONDITIONING" 3 "ACCESSORY" 4 "ACCESSORY_PLUS" 5 "DRIVE" 6 "OTA" 7 "WAIT_FOR_HIGH_POWER" 8 "TURN_ON_LV" 9 "SYSTEM_CHECKS" 10 "LV_ON" 11 "JUMP_START" 12 "LV_SHUTDOWN" 13 "GO_QUIET" 14 "SLEEP_SHUTDOWN" 15 "LOW_POWER_STANDBY" 16 "RESET" ;
VAL_ 1943 EPBR_ptcLVState 0 "OFF" 1 "ON" 2 "GOING_DOWN" 3 "FAULT" ;
VAL_ 1943 EPBR_premAudioLVState 0 "OFF" 1 "ON" 2 "GOING_DOWN" 3 "FAULT" ;
VAL_ 1943 EPBR_parkLVState 0 "OFF" 1 "ON" 2 "GOING_DOWN" 3 "FAULT" ;
VAL_ 1943 EPBR_tunerLVState 0 "OFF" 1 "ON" 2 "GOING_DOWN" 3 "FAULT" ;
VAL_ 1943 EPBR_rcmLVState 0 "OFF" 1 "ON" 2 "GOING_DOWN" 3 "FAULT" ;
CM_ BO_ 1944 "ESP32-DualCAN Model3_VEH. Seen on this car: 8-byte frames; fit ok (bits covered 100%, mux 86%, ranges 100%, checksum 0%).";
VAL_ 1944 EPBL_remoteADCIndex 0 "0" 1 "1" 2 "2" 3 "3" 4 "4" 5 "5" ;
CM_ BO_ 1945 "ESP32-DualCAN Model3_VEH. Not seen on this car in the logs.";
CM_ BO_ 1947 "ESP32-DualCAN Model3_VEH. Not seen on this car in the logs.";
CM_ BO_ 1948 "ESP32-DualCAN Model3_VEH. Not seen on this car in the logs.";
CM_ BO_ 1949 "ESP32-DualCAN Model3_VEH. Seen on this car: 8-byte frames; fit good (bits covered 100%, mux 100%, ranges 100%).";
CM_ BO_ 1951 "ESP32-DualCAN Model3_VEH. Not seen on this car in the logs.";
CM_ BO_ 1960 "ESP32-DualCAN Model3_VEH. Seen on this car: 8-byte frames; fit good (bits covered 100%, mux 100%, ranges 100%).";
VAL_ 1960 EPBR_esmCaliperRequest 0 "INVALID" 1 "NONE" 2 "APPLY" 3 "RELEASE" 4 "ENDSTOP" ;
VAL_ 1960 EPBR_pid_duty 127 "SNA" ;
CM_ BO_ 1970 "ESP32-DualCAN Model3_VEH. Not seen on this car in the logs.";
CM_ BO_ 1971 "ESP32-DualCAN Model3_CH.";
CM_ BO_ 1973 "ESP32-DualCAN Model3_VEH. Seen on this car: 3-byte frames; fit ok (bits covered 100%, mux 100%, ranges 100%).";
CM_ BO_ 1976 "ESP32-DualCAN Model3_VEH. Seen on this car: 8-byte frames; fit ok (bits covered 100%, mux 86%, ranges 100%, checksum 0%).";
VAL_ 1976 EPBR_remoteADCIndex 0 "0" 1 "1" 2 "2" 3 "3" 4 "4" 5 "5" ;
CM_ BO_ 1980 "ESP32-DualCAN Model3_VEH. Seen on this car: 8-byte frames; fit good (bits covered 100%, mux 100%, ranges 100%).";
CM_ BO_ 1981 "ESP32-DualCAN Model3_VEH. Seen on this car: 8-byte frames; fit good (bits covered 100%, mux 100%, ranges 100%).";
CM_ BO_ 1983 "ESP32-DualCAN Model3_VEH. Seen on this car: 1-byte frames; fit poor (bits covered 0%, mux 100%, ranges 100%).";
CM_ BO_ 1999 "ESP32-DualCAN Model3_VEH. Not seen on this car in the logs.";
VAL_ 1999 PM_regenBackfillState 0 "UNAVAILABLE" 1 "STANDBY" 2 "ACTIVE" ;
VAL_ 1999 PM_vehicleHoldState 0 "UNAVAILABLE" 1 "STANDBY" 2 "BLEND_IN" 3 "STANDSTILL" 4 "BLEND_OUT" 5 "PARK" 6 "FAULT" 7 "INIT" ;
VAL_ 1999 PM_aebState 0 "UNAVAILABLE" 1 "STANDBY" 2 "ENABLED" 3 "STANDSTILL" 4 "FAULT" 7 "SNA" ;
VAL_ 1999 PM_gear 0 "INVALID" 1 "P" 2 "R" 3 "N" 4 "D" 7 "SNA" ;
VAL_ 1999 PM_debugSelector 64 "Mux64" 128 "Mux128" 66 "Mux66" 67 "Mux67" 131 "Mux131" 68 "Mux68" 132 "Mux132" 69 "Mux69" 70 "Mux70" 72 "Mux72" 32 "Mux32" 33 "Mux33" 34 "Mux34" 35 "Mux35" 36 "Mux36" 37 "Mux37" 38 "Mux38" 39 "Mux39" 40 "Mux40" 41 "Mux41" 42 "Mux42" 43 "Mux43" 46 "Mux46" 47 "Mux47" 48 "Mux48" 49 "Mux49" 50 "Mux50" 52 "Mux52" 63 "Mux63" ;
CM_ BO_ 2002 "ESP32-DualCAN Model3_VEH. Not seen on this car in the logs.";
VAL_ 2002 BMS_1HzDebug_Id 0 "MUX0" 1 "MUX1" 2 "MUX2" 3 "MUX3" 4 "MUX4" 5 "MUX5" 6 "MUX6" 7 "MUX7" 8 "MUX8" 9 "MUX9" 10 "MUX10" 11 "MUX11" 12 "MUX12" 13 "MUX13" 14 "END" ;
CM_ BO_ 2004 "ESP32-DualCAN Model3_VEH. Seen on this car: 8-byte frames; fit weak (bits covered 0%, mux 100%, ranges 100%).";
VAL_ 2004 PMR_debugSelector 64 "Mux64" 128 "Mux128" 66 "Mux66" 67 "Mux67" 131 "Mux131" 68 "Mux68" 132 "Mux132" 69 "Mux69" 70 "Mux70" 72 "Mux72" 32 "Mux32" 33 "Mux33" 34 "Mux34" 35 "Mux35" 36 "Mux36" 37 "Mux37" 38 "Mux38" 39 "Mux39" 40 "Mux40" 41 "Mux41" 42 "Mux42" 43 "Mux43" 46 "Mux46" 47 "Mux47" 48 "Mux48" 49 "Mux49" 50 "Mux50" 52 "Mux52" 63 "Mux63" ;
